VERSION ""

NS_ :

BS_:

BU_: Turbocharger OnBoardDataLogger OffBoardDiagnosticTool2 OffBoardDiagnosticTool1 FileServer ParkingBrakeController SeatControl2 FanDriveController SteeringColumnUnit CommunicationUnitRadio CommunicationUnitSatellite CommunicationUnitCellular PropulsionBatteryCharger ChassisController2 ChassisController1 EngineValveControl AuxiliaryHeater2 AuxiliaryHeater1 ClutchUnit RampControl InformationSystem1 SuspensionSystemController2 OilSensor VehicleDynamicStability ExhaustEmissionController TransmissionDisplay2 TransmissionDisplay1 ClimateControl2 WaterPumpController RearAxleSteeringController LightingOperatorControl SeatController1 IgnitionController2 IgnitionController1 TirePressureController CabController2 CabController1 PneumaticSystemController SuspensionSystemController1 HydraulicPumpController EnduranceBrakingSystem RetarderExhaustEngine2 OnBoardDiagnosticUnit HeadwayController RetarderExhaustEngine1 CabDisplay1 ManagementComputer VirtualTerminal OffVehicleGateway PowerTakeOffFront HitchControl AuxiliaryValveControl BodyController TractorTrailerBridge1 StarterSystem ElectricalSystem VehicleSecurity VehicleNavigation AerodynamicControl ElectricalChargingSystem ClimateControl1 TripRecorder InstrumentCluster SuspensionDriveAxle2 SuspensionDriveAxle1 SuspensionSteerAxle SteeringController FuelSystem CruiseControl RetarderDriveline RetarderEngine BrakesDriveAxle2 BrakesDriveAxle1 BrakesSystemController BrakesSteerAxle AxleDrive2 AxleDrive1 AxleSteering PowerTakeOff ShiftConsoleSecondary ShiftConsolePrimary Transmission2 Transmission1 Engine2 Engine1

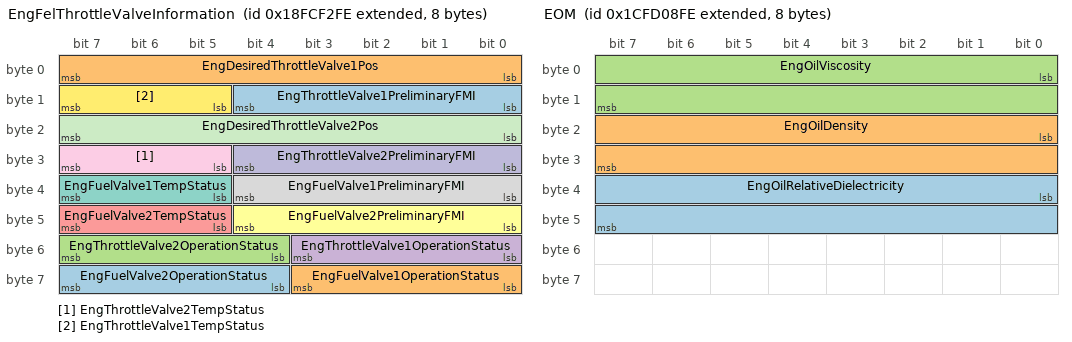
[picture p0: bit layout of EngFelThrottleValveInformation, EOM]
BO_ 2566714110 EngFelThrottleValveInformation: 8 Vector__XXX
 SG_ EngFuelValve2OperationStatus : 60|4@1+ (1,0) [0|15] "" Vector__XXX
 SG_ EngFuelValve1OperationStatus : 56|4@1+ (1,0) [0|15] "" Vector__XXX
 SG_ EngThrottleValve2OperationStatus : 52|4@1+ (1,0) [0|15] "" Vector__XXX
 SG_ EngThrottleValve1OperationStatus : 48|4@1+ (1,0) [0|15] "" Vector__XXX
 SG_ EngFuelValve2TempStatus : 45|3@1+ (1,0) [0|7] "" Vector__XXX
 SG_ EngFuelValve2PreliminaryFMI : 40|5@1+ (1,0) [0|31] "" Vector__XXX
 SG_ EngFuelValve1TempStatus : 37|3@1+ (1,0) [0|7] "" Vector__XXX
 SG_ EngFuelValve1PreliminaryFMI : 32|5@1+ (1,0) [0|31] "" Vector__XXX
 SG_ EngThrottleValve2TempStatus : 29|3@1+ (1,0) [0|7] "" Vector__XXX
 SG_ EngThrottleValve2PreliminaryFMI : 24|5@1+ (1,0) [0|31] "" Vector__XXX
 SG_ EngDesiredThrottleValve2Pos : 16|8@1+ (1,0) [0|100] "%" Vector__XXX
 SG_ EngThrottleValve1TempStatus : 13|3@1+ (1,0) [0|7] "" Vector__XXX
 SG_ EngThrottleValve1PreliminaryFMI : 8|5@1+ (1,0) [0|31] "" Vector__XXX
 SG_ EngDesiredThrottleValve1Pos : 0|8@1+ (1,0) [0|100] "%" Vector__XXX

BO_ 2566717438 ET5: 8 Vector__XXX
 SG_ EngExhstGsRcrcltn2MxerIntakeTemp : 16|16@1+ (0.03125,-273) [-273|1734.96875] "deg C" Vector__XXX
 SG_ EngExhaustGasRecirculation2Temp : 0|16@1+ (0.03125,-273) [-273|1734.96875] "deg C" Vector__XXX

BO_ 2633828606 EOM: 8 Vector__XXX
 SG_ EngOilRelativeDielectricity : 32|16@1+ (0.000122076103027,0) [0|7.844] "" Vector__XXX
 SG_ EngOilDensity : 16|16@1+ (3.051902575675E-005,0) [0|1.961] "g/cc" Vector__XXX
 SG_ EngOilViscosity : 0|16@1+ (0.015625,0) [0|1003.984375] "Cp" Vector__XXX

BO_ 2499607550 EMAP: 8 Vector__XXX
 SG_ EngExhstMnfldBnk2FlwBlncVlvActtr : 16|16@1+ (0.0025,0) [0|160.6375] "%" Vector__XXX
 SG_ EngExhstMnfldBnk1FlwBlncVlvActtr : 0|16@1+ (0.0025,0) [0|160.6375] "%" Vector__XXX

BO_ 2633825534 EMAC: 8 Vector__XXX
 SG_ EngExhstMnfldBnk2FlwBlncVlvActtr : 16|16@1+ (1,0) [0|160.6375] "%" Vector__XXX
 SG_ EngExhstMnfldBnk1FlwBlncVlvActtr : 0|16@1+ (1,0) [0|160.6375] "%" Vector__XXX

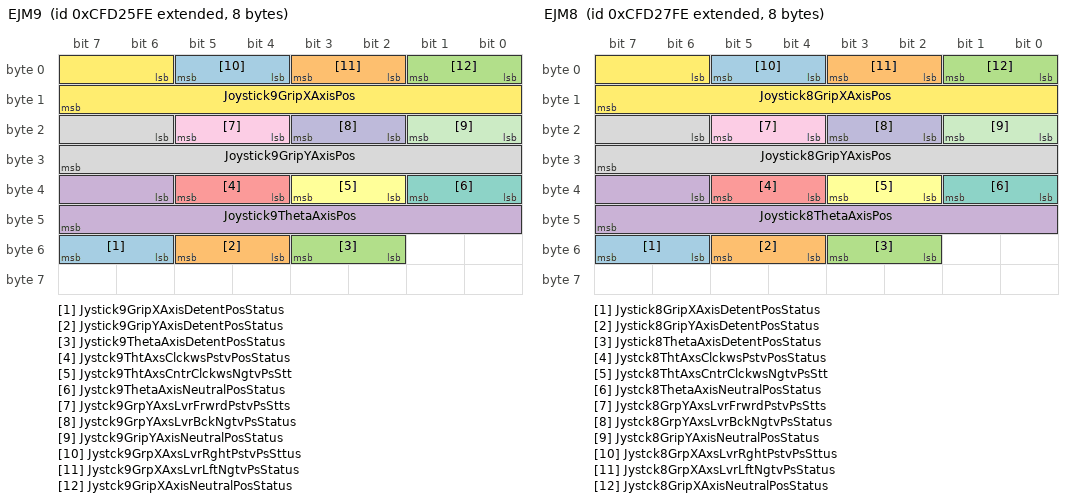
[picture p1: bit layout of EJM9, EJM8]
BO_ 2365400574 EJM9: 8 Vector__XXX
 SG_ Jystick9GripXAxisDetentPosStatus : 54|2@1+ (1,0) [0|3] "" Vector__XXX
 SG_ Jystick9GripYAxisDetentPosStatus : 52|2@1+ (1,0) [0|3] "" Vector__XXX
 SG_ Jystick9ThetaAxisDetentPosStatus : 50|2@1+ (1,0) [0|3] "" Vector__XXX
 SG_ Joystick9ThetaAxisPos : 38|10@1+ (1,0) [0|102] "%" Vector__XXX
 SG_ Jystck9ThtAxsClckwsPstvPosStatus : 36|2@1+ (1,0) [0|3] "" Vector__XXX
 SG_ Jystck9ThtAxsCntrClckwsNgtvPsStt : 34|2@1+ (1,0) [0|3] "" Vector__XXX
 SG_ Jystck9ThetaAxisNeutralPosStatus : 32|2@1+ (1,0) [0|3] "" Vector__XXX
 SG_ Joystick9GripYAxisPos : 22|10@1+ (1,0) [0|102] "%" Vector__XXX
 SG_ Jystck9GrpYAxsLvrFrwrdPstvPsStts : 20|2@1+ (1,0) [0|3] "" Vector__XXX
 SG_ Jystck9GrpYAxsLvrBckNgtvPsStatus : 18|2@1+ (1,0) [0|3] "" Vector__XXX
 SG_ Jystck9GripYAxisNeutralPosStatus : 16|2@1+ (1,0) [0|3] "" Vector__XXX
 SG_ Joystick9GripXAxisPos : 6|10@1+ (1,0) [0|102] "%" Vector__XXX
 SG_ Jystck9GrpXAxsLvrRghtPstvPsSttus : 4|2@1+ (1,0) [0|3] "" Vector__XXX
 SG_ Jystck9GrpXAxsLvrLftNgtvPsStatus : 2|2@1+ (1,0) [0|3] "" Vector__XXX
 SG_ Jystck9GripXAxisNeutralPosStatus : 0|2@1+ (1,0) [0|3] "" Vector__XXX

BO_ 2365401086 EJM8: 8 Vector__XXX
 SG_ Jystick8GripXAxisDetentPosStatus : 54|2@1+ (1,0) [0|3] "" Vector__XXX
 SG_ Jystick8GripYAxisDetentPosStatus : 52|2@1+ (1,0) [0|3] "" Vector__XXX
 SG_ Jystick8ThetaAxisDetentPosStatus : 50|2@1+ (1,0) [0|3] "" Vector__XXX
 SG_ Joystick8ThetaAxisPos : 38|10@1+ (1,0) [0|102] "%" Vector__XXX
 SG_ Jystck8ThtAxsClckwsPstvPosStatus : 36|2@1+ (1,0) [0|3] "" Vector__XXX
 SG_ Jystck8ThtAxsCntrClckwsNgtvPsStt : 34|2@1+ (1,0) [0|3] "" Vector__XXX
 SG_ Jystck8ThetaAxisNeutralPosStatus : 32|2@1+ (1,0) [0|3] "" Vector__XXX
 SG_ Joystick8GripYAxisPos : 22|10@1+ (1,0) [0|102] "%" Vector__XXX
 SG_ Jystck8GrpYAxsLvrFrwrdPstvPsStts : 20|2@1+ (1,0) [0|3] "" Vector__XXX
 SG_ Jystck8GrpYAxsLvrBckNgtvPsStatus : 18|2@1+ (1,0) [0|3] "" Vector__XXX
 SG_ Jystck8GripYAxisNeutralPosStatus : 16|2@1+ (1,0) [0|3] "" Vector__XXX
 SG_ Joystick8GripXAxisPos : 6|10@1+ (1,0) [0|102] "%" Vector__XXX
 SG_ Jystck8GrpXAxsLvrRghtPstvPsSttus : 4|2@1+ (1,0) [0|3] "" Vector__XXX
 SG_ Jystck8GrpXAxsLvrLftNgtvPsStatus : 2|2@1+ (1,0) [0|3] "" Vector__XXX
 SG_ Jystck8GripXAxisNeutralPosStatus : 0|2@1+ (1,0) [0|3] "" Vector__XXX

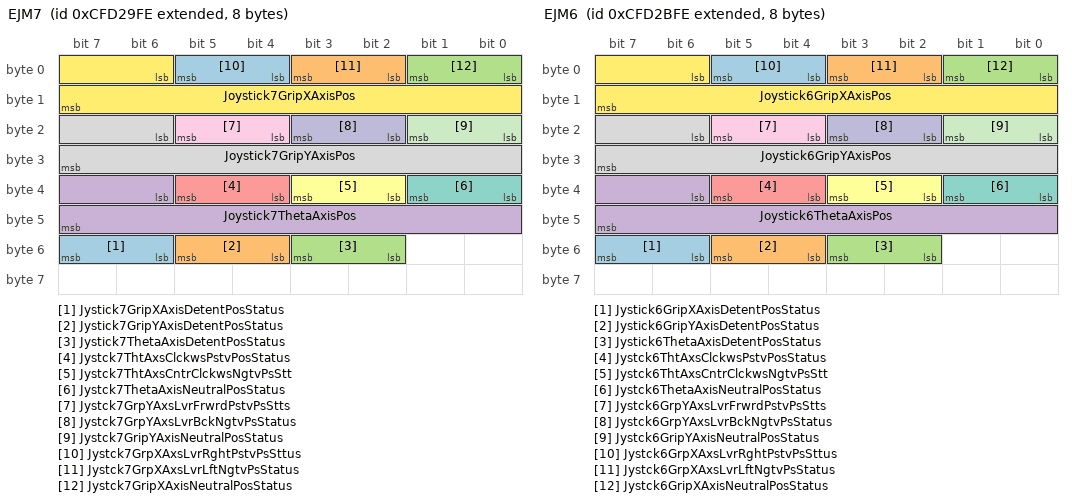
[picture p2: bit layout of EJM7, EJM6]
BO_ 2365401598 EJM7: 8 Vector__XXX
 SG_ Jystick7GripXAxisDetentPosStatus : 54|2@1+ (1,0) [0|3] "" Vector__XXX
 SG_ Jystick7GripYAxisDetentPosStatus : 52|2@1+ (1,0) [0|3] "" Vector__XXX
 SG_ Jystick7ThetaAxisDetentPosStatus : 50|2@1+ (1,0) [0|3] "" Vector__XXX
 SG_ Joystick7ThetaAxisPos : 38|10@1+ (1,0) [0|102] "%" Vector__XXX
 SG_ Jystck7ThtAxsClckwsPstvPosStatus : 36|2@1+ (1,0) [0|3] "" Vector__XXX
 SG_ Jystck7ThtAxsCntrClckwsNgtvPsStt : 34|2@1+ (1,0) [0|3] "" Vector__XXX
 SG_ Jystck7ThetaAxisNeutralPosStatus : 32|2@1+ (1,0) [0|3] "" Vector__XXX
 SG_ Joystick7GripYAxisPos : 22|10@1+ (1,0) [0|102] "%" Vector__XXX
 SG_ Jystck7GrpYAxsLvrFrwrdPstvPsStts : 20|2@1+ (1,0) [0|3] "" Vector__XXX
 SG_ Jystck7GrpYAxsLvrBckNgtvPsStatus : 18|2@1+ (1,0) [0|3] "" Vector__XXX
 SG_ Jystck7GripYAxisNeutralPosStatus : 16|2@1+ (1,0) [0|3] "" Vector__XXX
 SG_ Joystick7GripXAxisPos : 6|10@1+ (1,0) [0|102] "%" Vector__XXX
 SG_ Jystck7GrpXAxsLvrRghtPstvPsSttus : 4|2@1+ (1,0) [0|3] "" Vector__XXX
 SG_ Jystck7GrpXAxsLvrLftNgtvPsStatus : 2|2@1+ (1,0) [0|3] "" Vector__XXX
 SG_ Jystck7GripXAxisNeutralPosStatus : 0|2@1+ (1,0) [0|3] "" Vector__XXX

BO_ 2365402110 EJM6: 8 Vector__XXX
 SG_ Jystick6GripXAxisDetentPosStatus : 54|2@1+ (1,0) [0|3] "" Vector__XXX
 SG_ Jystick6GripYAxisDetentPosStatus : 52|2@1+ (1,0) [0|3] "" Vector__XXX
 SG_ Jystick6ThetaAxisDetentPosStatus : 50|2@1+ (1,0) [0|3] "" Vector__XXX
 SG_ Joystick6ThetaAxisPos : 38|10@1+ (1,0) [0|102] "%" Vector__XXX
 SG_ Jystck6ThtAxsClckwsPstvPosStatus : 36|2@1+ (1,0) [0|3] "" Vector__XXX
 SG_ Jystck6ThtAxsCntrClckwsNgtvPsStt : 34|2@1+ (1,0) [0|3] "" Vector__XXX
 SG_ Jystck6ThetaAxisNeutralPosStatus : 32|2@1+ (1,0) [0|3] "" Vector__XXX
 SG_ Joystick6GripYAxisPos : 22|10@1+ (1,0) [0|102] "%" Vector__XXX
 SG_ Jystck6GrpYAxsLvrFrwrdPstvPsStts : 20|2@1+ (1,0) [0|3] "" Vector__XXX
 SG_ Jystck6GrpYAxsLvrBckNgtvPsStatus : 18|2@1+ (1,0) [0|3] "" Vector__XXX
 SG_ Jystck6GripYAxisNeutralPosStatus : 16|2@1+ (1,0) [0|3] "" Vector__XXX
 SG_ Joystick6GripXAxisPos : 6|10@1+ (1,0) [0|102] "%" Vector__XXX
 SG_ Jystck6GrpXAxsLvrRghtPstvPsSttus : 4|2@1+ (1,0) [0|3] "" Vector__XXX
 SG_ Jystck6GrpXAxsLvrLftNgtvPsStatus : 2|2@1+ (1,0) [0|3] "" Vector__XXX
 SG_ Jystck6GripXAxisNeutralPosStatus : 0|2@1+ (1,0) [0|3] "" Vector__XXX

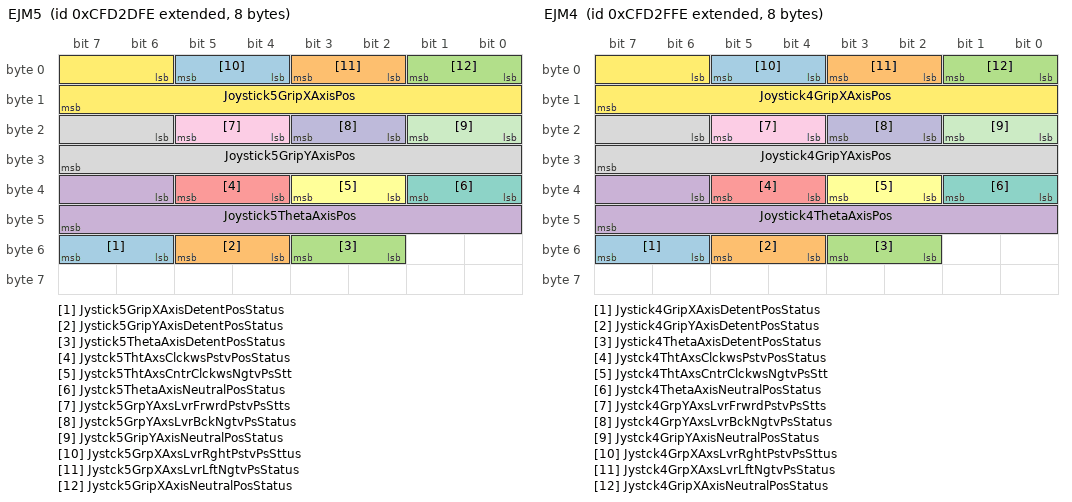
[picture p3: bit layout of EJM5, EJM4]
BO_ 2365402622 EJM5: 8 Vector__XXX
 SG_ Jystick5GripXAxisDetentPosStatus : 54|2@1+ (1,0) [0|3] "" Vector__XXX
 SG_ Jystick5GripYAxisDetentPosStatus : 52|2@1+ (1,0) [0|3] "" Vector__XXX
 SG_ Jystick5ThetaAxisDetentPosStatus : 50|2@1+ (1,0) [0|3] "" Vector__XXX
 SG_ Joystick5ThetaAxisPos : 38|10@1+ (1,0) [0|102] "%" Vector__XXX
 SG_ Jystck5ThtAxsClckwsPstvPosStatus : 36|2@1+ (1,0) [0|3] "" Vector__XXX
 SG_ Jystck5ThtAxsCntrClckwsNgtvPsStt : 34|2@1+ (1,0) [0|3] "" Vector__XXX
 SG_ Jystck5ThetaAxisNeutralPosStatus : 32|2@1+ (1,0) [0|3] "" Vector__XXX
 SG_ Joystick5GripYAxisPos : 22|10@1+ (1,0) [0|102] "%" Vector__XXX
 SG_ Jystck5GrpYAxsLvrFrwrdPstvPsStts : 20|2@1+ (1,0) [0|3] "" Vector__XXX
 SG_ Jystck5GrpYAxsLvrBckNgtvPsStatus : 18|2@1+ (1,0) [0|3] "" Vector__XXX
 SG_ Jystck5GripYAxisNeutralPosStatus : 16|2@1+ (1,0) [0|3] "" Vector__XXX
 SG_ Joystick5GripXAxisPos : 6|10@1+ (1,0) [0|102] "%" Vector__XXX
 SG_ Jystck5GrpXAxsLvrRghtPstvPsSttus : 4|2@1+ (1,0) [0|3] "" Vector__XXX
 SG_ Jystck5GrpXAxsLvrLftNgtvPsStatus : 2|2@1+ (1,0) [0|3] "" Vector__XXX
 SG_ Jystck5GripXAxisNeutralPosStatus : 0|2@1+ (1,0) [0|3] "" Vector__XXX

BO_ 2365403134 EJM4: 8 Vector__XXX
 SG_ Jystick4GripXAxisDetentPosStatus : 54|2@1+ (1,0) [0|3] "" Vector__XXX
 SG_ Jystick4GripYAxisDetentPosStatus : 52|2@1+ (1,0) [0|3] "" Vector__XXX
 SG_ Jystick4ThetaAxisDetentPosStatus : 50|2@1+ (1,0) [0|3] "" Vector__XXX
 SG_ Joystick4ThetaAxisPos : 38|10@1+ (1,0) [0|102] "%" Vector__XXX
 SG_ Jystck4ThtAxsClckwsPstvPosStatus : 36|2@1+ (1,0) [0|3] "" Vector__XXX
 SG_ Jystck4ThtAxsCntrClckwsNgtvPsStt : 34|2@1+ (1,0) [0|3] "" Vector__XXX
 SG_ Jystck4ThetaAxisNeutralPosStatus : 32|2@1+ (1,0) [0|3] "" Vector__XXX
 SG_ Joystick4GripYAxisPos : 22|10@1+ (1,0) [0|102] "%" Vector__XXX
 SG_ Jystck4GrpYAxsLvrFrwrdPstvPsStts : 20|2@1+ (1,0) [0|3] "" Vector__XXX
 SG_ Jystck4GrpYAxsLvrBckNgtvPsStatus : 18|2@1+ (1,0) [0|3] "" Vector__XXX
 SG_ Jystck4GripYAxisNeutralPosStatus : 16|2@1+ (1,0) [0|3] "" Vector__XXX
 SG_ Joystick4GripXAxisPos : 6|10@1+ (1,0) [0|102] "%" Vector__XXX
 SG_ Jystck4GrpXAxsLvrRghtPstvPsSttus : 4|2@1+ (1,0) [0|3] "" Vector__XXX
 SG_ Jystck4GrpXAxsLvrLftNgtvPsStatus : 2|2@1+ (1,0) [0|3] "" Vector__XXX
 SG_ Jystck4GripXAxisNeutralPosStatus : 0|2@1+ (1,0) [0|3] "" Vector__XXX

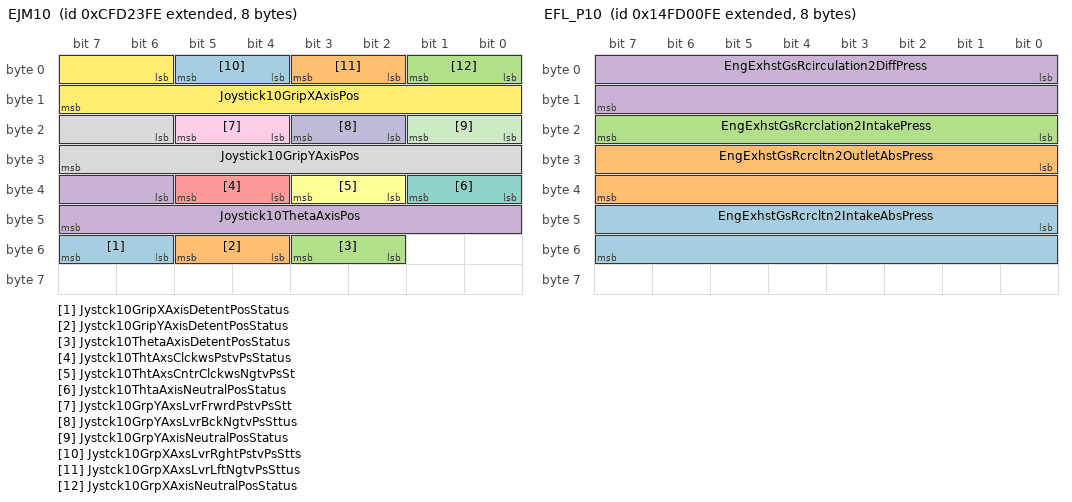
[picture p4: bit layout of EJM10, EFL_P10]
BO_ 2365400062 EJM10: 8 Vector__XXX
 SG_ Jystck10GripXAxisDetentPosStatus : 54|2@1+ (1,0) [0|3] "" Vector__XXX
 SG_ Jystck10GripYAxisDetentPosStatus : 52|2@1+ (1,0) [0|3] "" Vector__XXX
 SG_ Jystck10ThetaAxisDetentPosStatus : 50|2@1+ (1,0) [0|3] "" Vector__XXX
 SG_ Joystick10ThetaAxisPos : 38|10@1+ (1,0) [0|102] "%" Vector__XXX
 SG_ Jystck10ThtAxsClckwsPstvPsStatus : 36|2@1+ (1,0) [0|3] "" Vector__XXX
 SG_ Jystck10ThtAxsCntrClckwsNgtvPsSt : 34|2@1+ (1,0) [0|3] "" Vector__XXX
 SG_ Jystck10ThtaAxisNeutralPosStatus : 32|2@1+ (1,0) [0|3] "" Vector__XXX
 SG_ Joystick10GripYAxisPos : 22|10@1+ (1,0) [0|102] "%" Vector__XXX
 SG_ Jystck10GrpYAxsLvrFrwrdPstvPsStt : 20|2@1+ (1,0) [0|3] "" Vector__XXX
 SG_ Jystck10GrpYAxsLvrBckNgtvPsSttus : 18|2@1+ (1,0) [0|3] "" Vector__XXX
 SG_ Jystck10GrpYAxisNeutralPosStatus : 16|2@1+ (1,0) [0|3] "" Vector__XXX
 SG_ Joystick10GripXAxisPos : 6|10@1+ (1,0) [0|102] "%" Vector__XXX
 SG_ Jystck10GrpXAxsLvrRghtPstvPsStts : 4|2@1+ (1,0) [0|3] "" Vector__XXX
 SG_ Jystck10GrpXAxsLvrLftNgtvPsSttus : 2|2@1+ (1,0) [0|3] "" Vector__XXX
 SG_ Jystck10GrpXAxisNeutralPosStatus : 0|2@1+ (1,0) [0|3] "" Vector__XXX

BO_ 2566713598 EFS2: 8 Vector__XXX
 SG_ EngFuelFilterIntakeAbsPress : 0|8@1+ (2,0) [0|500] "kPa" Vector__XXX

BO_ 2499604478 EFL_P11: 8 Vector__XXX
 SG_ EngExhstGsRcrcltn1OutletAbsPress : 16|16@1+ (0.1,0) [0|6425.5] "kPa" Vector__XXX
 SG_ EngExhstGsRcrcltn1IntakeAbsPress : 0|16@1+ (0.1,0) [0|6425.5] "kPa" Vector__XXX

BO_ 2499608830 EFL_P10: 8 Vector__XXX
 SG_ EngExhstGsRcrcltn2IntakeAbsPress : 40|16@1+ (0.1,0) [0|6425.5] "kPa" Vector__XXX
 SG_ EngExhstGsRcrcltn2OutletAbsPress : 24|16@1+ (0.1,0) [0|6425.5] "kPa" Vector__XXX
 SG_ EngExhstGsRcrclation2IntakePress : 16|8@1+ (2,0) [0|500] "kPa" Vector__XXX
 SG_ EngExhstGsRcirculation2DiffPress : 0|16@1+ (0.0078124659559567,-250) [-250|251.99] "kPa" Vector__XXX

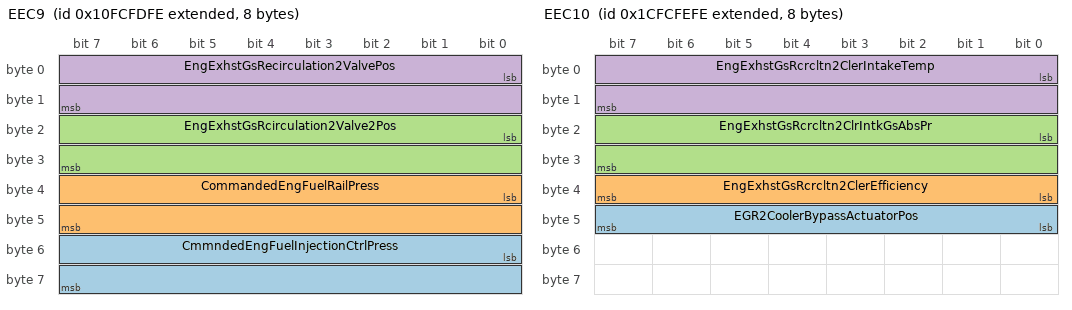
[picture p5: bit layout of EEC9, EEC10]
BO_ 2432499198 EEC9: 8 Vector__XXX
 SG_ CmmndedEngFuelInjectionCtrlPress : 48|16@1+ (0.0039063107929344,0) [0|251] "MPa" Vector__XXX
 SG_ CommandedEngFuelRailPress : 32|16@1+ (0.0039063107929344,0) [0|251] "MPa" Vector__XXX
 SG_ EngExhstGsRcirculation2Valve2Pos : 16|16@1+ (0.0025,0) [0|160.6375] "%" Vector__XXX
 SG_ EngExhstGsRecirculation2ValvePos : 0|16@1+ (0.0025,0) [0|160.6375] "%" Vector__XXX

BO_ 2633825022 EEC11: 8 Vector__XXX
 SG_ EngExhstGsRcrculation2Valve2Ctrl : 16|16@1+ (0.0025,0) [0|160.6375] "%" Vector__XXX
 SG_ EngExhstGsRcirculation2ValveCtrl : 0|16@1+ (0.0025,0) [0|160.6375] "%" Vector__XXX

BO_ 2633826046 EEC10: 8 Vector__XXX
 SG_ EGR2CoolerBypassActuatorPos : 40|8@1+ (0.4,0) [0|100] "%" Vector__XXX
 SG_ EngExhstGsRcrcltn2ClerEfficiency : 32|8@1+ (0.4,0) [0|100] "%" Vector__XXX
 SG_ EngExhstGsRcrcltn2ClrIntkGsAbsPr : 16|16@1+ (0.5,0) [0|32127.5] "kPa" Vector__XXX
 SG_ EngExhstGsRcrcltn2ClerIntakeTemp : 0|16@1+ (0.03125,-273) [-273|1734.96875] "deg C" Vector__XXX

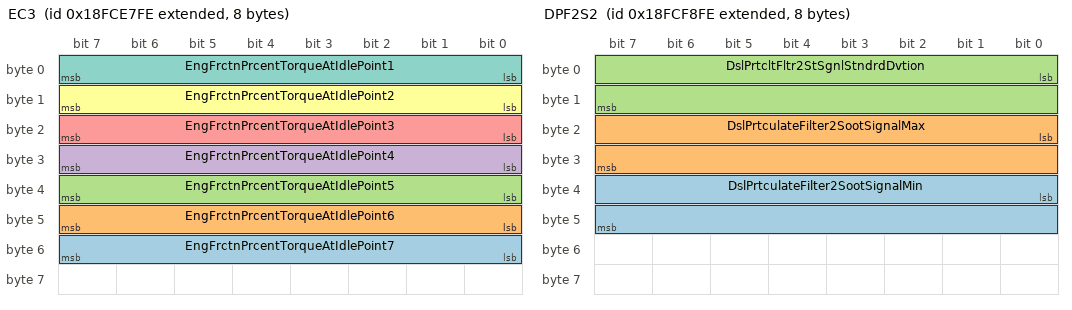
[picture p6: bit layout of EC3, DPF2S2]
BO_ 2566711294 EC3: 8 Vector__XXX
 SG_ EngFrctnPrcentTorqueAtIdlePoint7 : 48|8@1+ (1,-125) [-125|125] "%" Vector__XXX
 SG_ EngFrctnPrcentTorqueAtIdlePoint6 : 40|8@1+ (1,-125) [-125|125] "%" Vector__XXX
 SG_ EngFrctnPrcentTorqueAtIdlePoint5 : 32|8@1+ (1,-125) [-125|125] "%" Vector__XXX
 SG_ EngFrctnPrcentTorqueAtIdlePoint4 : 24|8@1+ (1,-125) [-125|125] "%" Vector__XXX
 SG_ EngFrctnPrcentTorqueAtIdlePoint3 : 16|8@1+ (1,-125) [-125|125] "%" Vector__XXX
 SG_ EngFrctnPrcentTorqueAtIdlePoint2 : 8|8@1+ (1,-125) [-125|125] "%" Vector__XXX
 SG_ EngFrctnPrcentTorqueAtIdlePoint1 : 0|8@1+ (1,-125) [-125|125] "%" Vector__XXX

BO_ 2566749438 DPFC1: 8 Vector__XXX
 SG_ DslPrtcltFltrActvRgnrtnFrcdSttus : 53|3@1+ (1,0) [0|7] "" Vector__XXX
 SG_ ExhaustSystemHighTempLampCmd : 50|3@1+ (1,0) [0|7] "" Vector__XXX
 SG_ DslPrtcltFltrAtmtcActvRgnrtnIntt : 48|2@1+ (1,0) [0|3] "" Vector__XXX
 SG_ DslPrtcltFltrActvRgnrtnInhbtdDTV : 46|2@1+ (1,0) [0|3] "" Vector__XXX
 SG_ DslPrtcltFltrActvRgnrtnInhbtdDTE : 44|2@1+ (1,0) [0|3] "" Vector__XXX
 SG_ DslPrtcltFltrActvRgnrtnInhb_0000 : 42|2@1+ (1,0) [0|3] "" Vector__XXX
 SG_ DslPrtcltFltrActvRgnrtnInhbtdDTT : 40|2@1+ (1,0) [0|3] "" Vector__XXX
 SG_ DslPrtcltFltrActvRgnrtnInhbtdDTS : 38|2@1+ (1,0) [0|3] "" Vector__XXX
 SG_ DslPrtcltFltrActvRgnrtnInhbtdDTS : 36|2@1+ (1,0) [0|3] "" Vector__XXX
 SG_ DslPrtcltFltrActvRgnrtnInhbtdDTL : 34|2@1+ (1,0) [0|3] "" Vector__XXX
 SG_ DslPrtcltFltrActvRgnrtnInhb_0001 : 32|2@1+ (1,0) [0|3] "" Vector__XXX
 SG_ DslPrtcltFltrActvRgnrtnInhb_0002 : 30|2@1+ (1,0) [0|3] "" Vector__XXX
 SG_ DslPrtcltFltrActvRgnrtnInhbtdDTO : 28|2@1+ (1,0) [0|3] "" Vector__XXX
 SG_ DslPrtcltFltrActvRgnrtnInhbtdDTA : 26|2@1+ (1,0) [0|3] "" Vector__XXX
 SG_ DslPrtcltFltrActvRgnrtnInhbtdDTP : 24|2@1+ (1,0) [0|3] "" Vector__XXX
 SG_ DslPrtcltFltrActvRgnrtnInhbtdDTS : 22|2@1+ (1,0) [0|3] "" Vector__XXX
 SG_ DslPrtcltFltrActvRgnrtnInhbtdDTC : 20|2@1+ (1,0) [0|3] "" Vector__XXX
 SG_ DslPrtcltFltrActvRgnrtnInhbtdDTI : 18|2@1+ (1,0) [0|3] "" Vector__XXX
 SG_ DslPrtcltFltrActvRgnrtnInhbtdStt : 16|2@1+ (1,0) [0|3] "" Vector__XXX
 SG_ DieselParticulateFilterStatus : 12|3@1+ (1,0) [0|7] "" Vector__XXX
 SG_ DslPrtcltFltrActvRgnrationStatus : 10|2@1+ (1,0) [0|3] "" Vector__XXX
 SG_ DslPrtcltFltrPssvRgnrationStatus : 8|2@1+ (1,0) [0|3] "" Vector__XXX
 SG_ DieselParticulateFilterLampCmd : 0|3@1+ (1,0) [0|7] "" Vector__XXX

BO_ 2566715646 DPF2S2: 8 Vector__XXX
 SG_ DslPrtculateFilter2SootSignalMin : 32|16@1+ (0.0025,0) [0|160.6375] "%" Vector__XXX
 SG_ DslPrtculateFilter2SootSignalMax : 16|16@1+ (0.0025,0) [0|160.6375] "%" Vector__XXX
 SG_ DslPrtcltFltr2StSgnlStndrdDvtion : 0|16@1+ (0.0025,0) [0|160.6375] "%" Vector__XXX

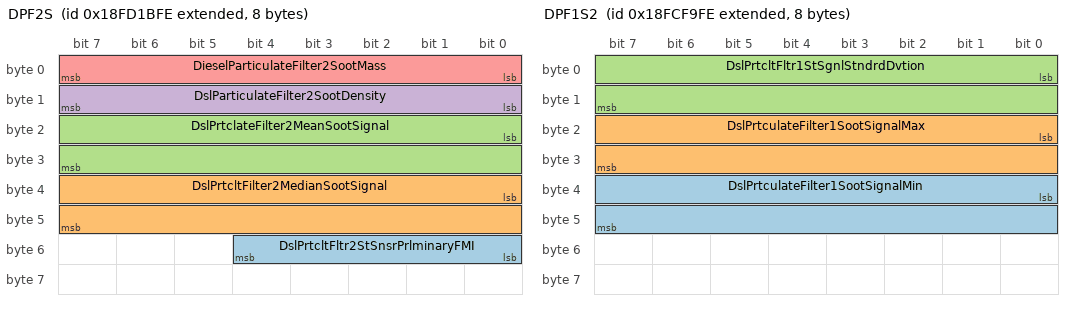
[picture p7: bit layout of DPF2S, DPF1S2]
BO_ 2566724606 DPF2S: 8 Vector__XXX
 SG_ DslPrtcltFltr2StSnsrPrlminaryFMI : 48|5@1+ (1,0) [0|31] "" Vector__XXX
 SG_ DslPrtcltFilter2MedianSootSignal : 32|16@1+ (0.0025,0) [0|160.6375] "%" Vector__XXX
 SG_ DslPrtclateFilter2MeanSootSignal : 16|16@1+ (0.0025,0) [0|160.6375] "%" Vector__XXX
 SG_ DslParticulateFilter2SootDensity : 8|8@1+ (0.08,0) [0|20] "g/L" Vector__XXX
 SG_ DieselParticulateFilter2SootMass : 0|8@1+ (4,0) [0|1000] "g" Vector__XXX

BO_ 2566715902 DPF1S2: 8 Vector__XXX
 SG_ DslPrtculateFilter1SootSignalMin : 32|16@1+ (0.0025,0) [0|160.6375] "%" Vector__XXX
 SG_ DslPrtculateFilter1SootSignalMax : 16|16@1+ (0.0025,0) [0|160.6375] "%" Vector__XXX
 SG_ DslPrtcltFltr1StSgnlStndrdDvtion : 0|16@1+ (0.0025,0) [0|160.6375] "%" Vector__XXX

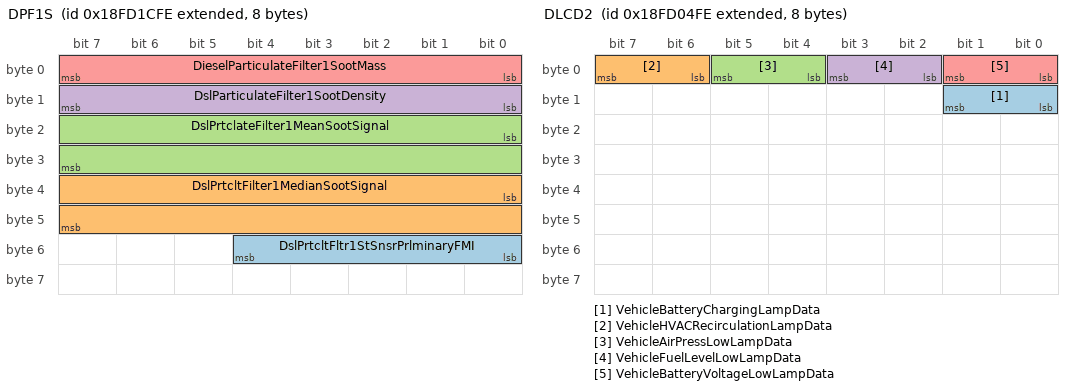
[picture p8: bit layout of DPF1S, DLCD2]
BO_ 2566724862 DPF1S: 8 Vector__XXX
 SG_ DslPrtcltFltr1StSnsrPrlminaryFMI : 48|5@1+ (1,0) [0|31] "" Vector__XXX
 SG_ DslPrtcltFilter1MedianSootSignal : 32|16@1+ (0.0025,0) [0|160.6375] "%" Vector__XXX
 SG_ DslPrtclateFilter1MeanSootSignal : 16|16@1+ (0.0025,0) [0|160.6375] "%" Vector__XXX
 SG_ DslParticulateFilter1SootDensity : 8|8@1+ (0.08,0) [0|20] "g/L" Vector__XXX
 SG_ DieselParticulateFilter1SootMass : 0|8@1+ (4,0) [0|1000] "g" Vector__XXX

BO_ 2566718718 DLCD2: 8 Vector__XXX
 SG_ VehicleBatteryChargingLampData : 8|2@1+ (1,0) [0|3] "" Vector__XXX
 SG_ VehicleHVACRecirculationLampData : 6|2@1+ (1,0) [0|3] "" Vector__XXX
 SG_ VehicleAirPressLowLampData : 4|2@1+ (1,0) [0|3] "" Vector__XXX
 SG_ VehicleFuelLevelLowLampData : 2|2@1+ (1,0) [0|3] "" Vector__XXX
 SG_ VehicleBatteryVoltageLowLampData : 0|2@1+ (1,0) [0|3] "" Vector__XXX

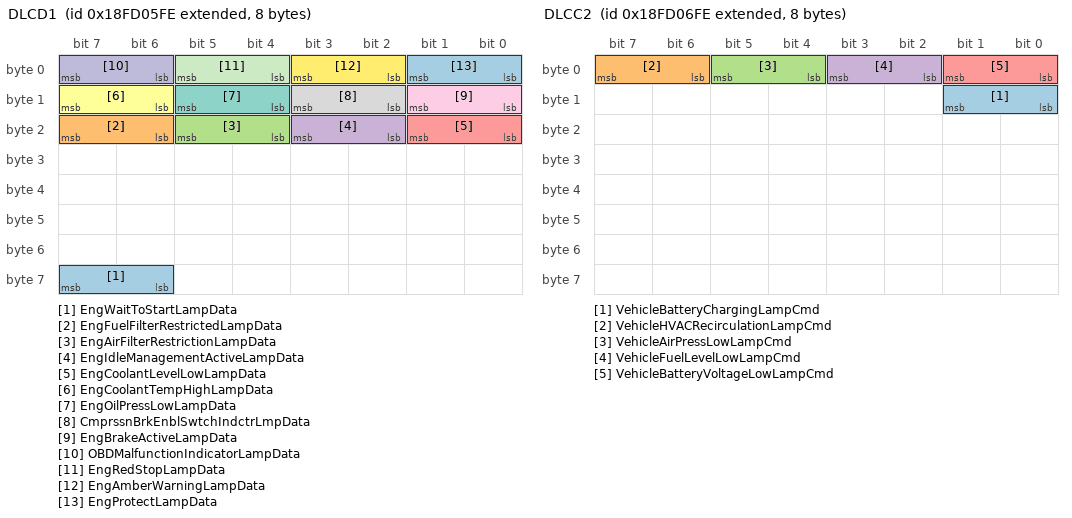
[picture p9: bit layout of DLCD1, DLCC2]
BO_ 2566718974 DLCD1: 8 Vector__XXX
 SG_ EngWaitToStartLampData : 62|2@1+ (1,0) [0|3] "" Vector__XXX
 SG_ EngFuelFilterRestrictedLampData : 22|2@1+ (1,0) [0|3] "" Vector__XXX
 SG_ EngAirFilterRestrictionLampData : 20|2@1+ (1,0) [0|3] "" Vector__XXX
 SG_ EngIdleManagementActiveLampData : 18|2@1+ (1,0) [0|3] "" Vector__XXX
 SG_ EngCoolantLevelLowLampData : 16|2@1+ (1,0) [0|3] "" Vector__XXX
 SG_ EngCoolantTempHighLampData : 14|2@1+ (1,0) [0|3] "" Vector__XXX
 SG_ EngOilPressLowLampData : 12|2@1+ (1,0) [0|3] "" Vector__XXX
 SG_ CmprssnBrkEnblSwtchIndctrLmpData : 10|2@1+ (1,0) [0|3] "" Vector__XXX
 SG_ EngBrakeActiveLampData : 8|2@1+ (1,0) [0|3] "" Vector__XXX
 SG_ OBDMalfunctionIndicatorLampData : 6|2@1+ (1,0) [0|3] "" Vector__XXX
 SG_ EngRedStopLampData : 4|2@1+ (1,0) [0|3] "" Vector__XXX
 SG_ EngAmberWarningLampData : 2|2@1+ (1,0) [0|3] "" Vector__XXX
 SG_ EngProtectLampData : 0|2@1+ (1,0) [0|3] "" Vector__XXX

BO_ 2566719230 DLCC2: 8 Vector__XXX
 SG_ VehicleBatteryChargingLampCmd : 8|2@1+ (1,0) [0|3] "" Vector__XXX
 SG_ VehicleHVACRecirculationLampCmd : 6|2@1+ (1,0) [0|3] "" Vector__XXX
 SG_ VehicleAirPressLowLampCmd : 4|2@1+ (1,0) [0|3] "" Vector__XXX
 SG_ VehicleFuelLevelLowLampCmd : 2|2@1+ (1,0) [0|3] "" Vector__XXX
 SG_ VehicleBatteryVoltageLowLampCmd : 0|2@1+ (1,0) [0|3] "" Vector__XXX

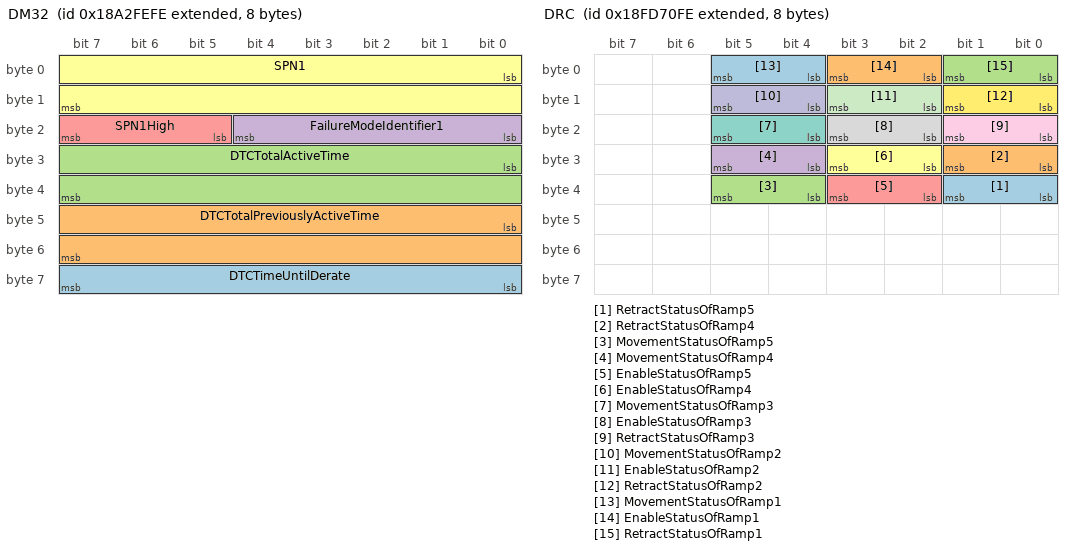
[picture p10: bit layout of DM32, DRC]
BO_ 2560818942 DM32: 8 Vector__XXX
 SG_ DTCTimeUntilDerate : 56|8@1+ (0.25,0) [0|62.5] "hr" Vector__XXX
 SG_ DTCTotalPreviouslyActiveTime : 40|16@1+ (0.2,0) [0|12851] "hr" Vector__XXX
 SG_ DTCTotalActiveTime : 24|16@1+ (0.2,0) [0|12851] "hr" Vector__XXX
 SG_ FailureModeIdentifier1 : 16|5@1+ (1,0) [0|0] "" Vector__XXX
 SG_ SPN1High : 21|3@1+ (1,0) [0|7] "" Vector__XXX
 SG_ SPN1 : 0|16@1+ (1,0) [0|65536] "" Vector__XXX

BO_ 2561212158 DISP1: 8 Vector__XXX
 SG_ TextDisplayIndex : 16|8@1+ (1,0) [0|250] "" Vector__XXX
 SG_ TextDisplayInstructions : 0|4@1+ (1,0) [0|15] "" Vector__XXX

BO_ 2566746366 DRC: 8 Vector__XXX
 SG_ RetractStatusOfRamp5 : 32|2@1+ (1,0) [0|3] "" Vector__XXX
 SG_ RetractStatusOfRamp4 : 24|2@1+ (1,0) [0|3] "" Vector__XXX
 SG_ MovementStatusOfRamp5 : 36|2@1+ (1,0) [0|3] "" Vector__XXX
 SG_ MovementStatusOfRamp4 : 28|2@1+ (1,0) [0|3] "" Vector__XXX
 SG_ EnableStatusOfRamp5 : 34|2@1+ (1,0) [0|3] "" Vector__XXX
 SG_ EnableStatusOfRamp4 : 26|2@1+ (1,0) [0|3] "" Vector__XXX
 SG_ MovementStatusOfRamp3 : 20|2@1+ (1,0) [0|3] "" Vector__XXX
 SG_ EnableStatusOfRamp3 : 18|2@1+ (1,0) [0|3] "" Vector__XXX
 SG_ RetractStatusOfRamp3 : 16|2@1+ (1,0) [0|3] "" Vector__XXX
 SG_ MovementStatusOfRamp2 : 12|2@1+ (1,0) [0|3] "" Vector__XXX
 SG_ EnableStatusOfRamp2 : 10|2@1+ (1,0) [0|3] "" Vector__XXX
 SG_ RetractStatusOfRamp2 : 8|2@1+ (1,0) [0|3] "" Vector__XXX
 SG_ MovementStatusOfRamp1 : 4|2@1+ (1,0) [0|3] "" Vector__XXX
 SG_ EnableStatusOfRamp1 : 2|2@1+ (1,0) [0|3] "" Vector__XXX
 SG_ RetractStatusOfRamp1 : 0|2@1+ (1,0) [0|3] "" Vector__XXX

BO_ 2566750206 EC2: 8 Vector__XXX
 SG_ MaxCrankAttemptsPerStartAttempt : 0|8@1+ (1,0) [0|250] "" Vector__XXX

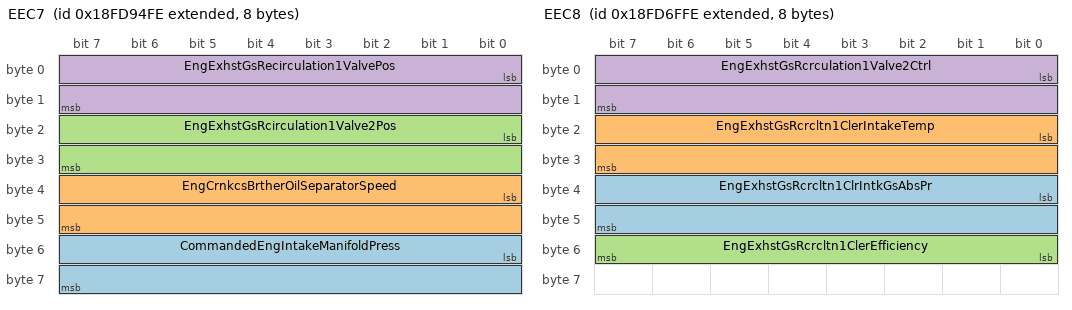
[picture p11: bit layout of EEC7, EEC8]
BO_ 2566755582 EEC7: 8 Vector__XXX
 SG_ CommandedEngIntakeManifoldPress : 48|16@1+ (0.125,0) [0|8031.875] "kPa" Vector__XXX
 SG_ EngCrnkcsBrtherOilSeparatorSpeed : 32|16@1+ (1,0) [0|64255] "rpm" Vector__XXX
 SG_ EngExhstGsRcirculation1Valve2Pos : 16|16@1+ (0.0025,0) [0|160.6375] "%" Vector__XXX
 SG_ EngExhstGsRecirculation1ValvePos : 0|16@1+ (0.0025,0) [0|160.6375] "%" Vector__XXX

BO_ 2566746110 EEC8: 8 Vector__XXX
 SG_ EngExhstGsRcrcltn1ClrIntkGsAbsPr : 32|16@1+ (0.5,0) [0|32127.5] "kPa" Vector__XXX
 SG_ EngExhstGsRcrcltn1ClerIntakeTemp : 16|16@1+ (0.03125,-273) [-273|1734.96875] "deg C" Vector__XXX
 SG_ EngExhstGsRcrcltn1ClerEfficiency : 48|8@1+ (1,0) [0|100] "%" Vector__XXX
 SG_ EngExhstGsRcrculation1Valve2Ctrl : 0|16@1+ (1,0) [0|160.6375] "%" Vector__XXX

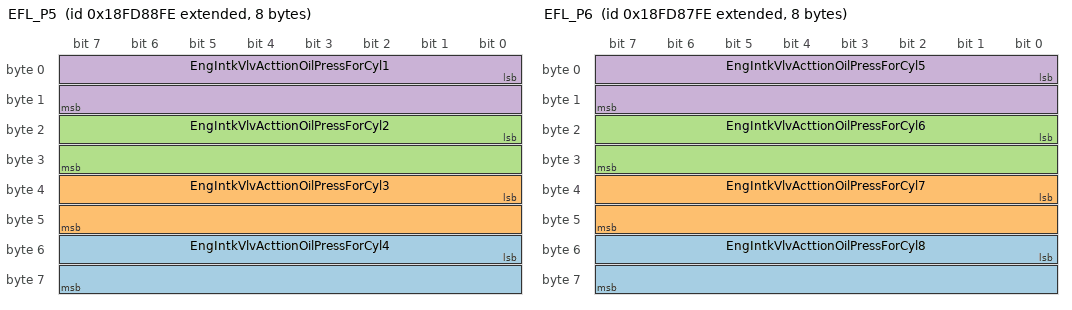
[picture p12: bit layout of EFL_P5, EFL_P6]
BO_ 2566752510 EFL_P5: 8 Vector__XXX
 SG_ EngIntkVlvActtionOilPressForCyl4 : 48|16@1+ (0.1,0) [0|6425.5] "kPa" Vector__XXX
 SG_ EngIntkVlvActtionOilPressForCyl3 : 32|16@1+ (0.1,0) [0|6425.5] "kPa" Vector__XXX
 SG_ EngIntkVlvActtionOilPressForCyl2 : 16|16@1+ (0.1,0) [0|6425.5] "kPa" Vector__XXX
 SG_ EngIntkVlvActtionOilPressForCyl1 : 0|16@1+ (0.1,0) [0|6425.5] "kPa" Vector__XXX

BO_ 2566752254 EFL_P6: 8 Vector__XXX
 SG_ EngIntkVlvActtionOilPressForCyl8 : 48|16@1+ (0.1,0) [0|6425.5] "kPa" Vector__XXX
 SG_ EngIntkVlvActtionOilPressForCyl7 : 32|16@1+ (0.1,0) [0|6425.5] "kPa" Vector__XXX
 SG_ EngIntkVlvActtionOilPressForCyl6 : 16|16@1+ (0.1,0) [0|6425.5] "kPa" Vector__XXX
 SG_ EngIntkVlvActtionOilPressForCyl5 : 0|16@1+ (0.1,0) [0|6425.5] "kPa" Vector__XXX

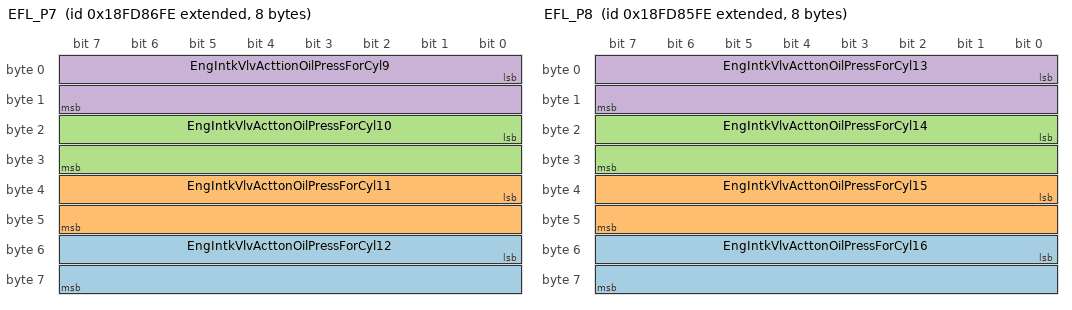
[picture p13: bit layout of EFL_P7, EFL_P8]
BO_ 2566751998 EFL_P7: 8 Vector__XXX
 SG_ EngIntkVlvActtonOilPressForCyl12 : 48|16@1+ (0.1,0) [0|6425.5] "kPa" Vector__XXX
 SG_ EngIntkVlvActtonOilPressForCyl11 : 32|16@1+ (0.1,0) [0|6425.5] "kPa" Vector__XXX
 SG_ EngIntkVlvActtonOilPressForCyl10 : 16|16@1+ (0.1,0) [0|6425.5] "kPa" Vector__XXX
 SG_ EngIntkVlvActtionOilPressForCyl9 : 0|16@1+ (0.1,0) [0|6425.5] "kPa" Vector__XXX

BO_ 2566751742 EFL_P8: 8 Vector__XXX
 SG_ EngIntkVlvActtonOilPressForCyl16 : 48|16@1+ (0.1,0) [0|6425.5] "kPa" Vector__XXX
 SG_ EngIntkVlvActtonOilPressForCyl15 : 32|16@1+ (0.1,0) [0|6425.5] "kPa" Vector__XXX
 SG_ EngIntkVlvActtonOilPressForCyl14 : 16|16@1+ (0.1,0) [0|6425.5] "kPa" Vector__XXX
 SG_ EngIntkVlvActtonOilPressForCyl13 : 0|16@1+ (0.1,0) [0|6425.5] "kPa" Vector__XXX

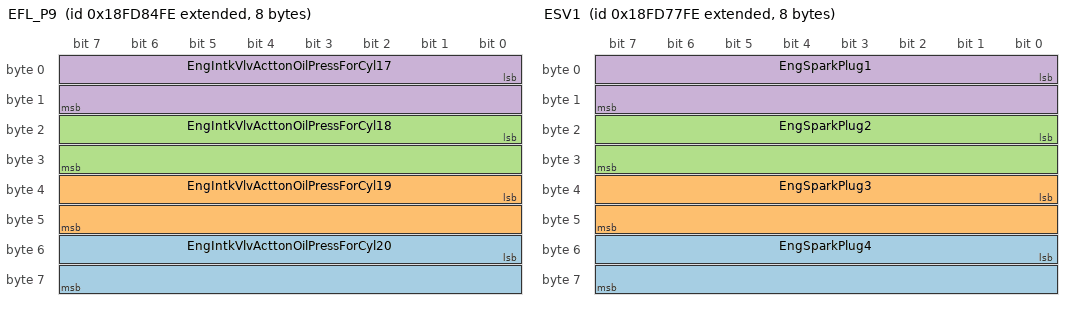
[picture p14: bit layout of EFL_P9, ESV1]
BO_ 2566751486 EFL_P9: 8 Vector__XXX
 SG_ EngIntkVlvActtonOilPressForCyl20 : 48|16@1+ (0.1,0) [0|6425.5] "kPa" Vector__XXX
 SG_ EngIntkVlvActtonOilPressForCyl19 : 32|16@1+ (0.1,0) [0|6425.5] "kPa" Vector__XXX
 SG_ EngIntkVlvActtonOilPressForCyl18 : 16|16@1+ (0.1,0) [0|6425.5] "kPa" Vector__XXX
 SG_ EngIntkVlvActtonOilPressForCyl17 : 0|16@1+ (0.1,0) [0|6425.5] "kPa" Vector__XXX

BO_ 2499641854 EGRBV: 8 Vector__XXX
 SG_ EGR1CoolerBypassActuatorPostion : 0|8@1+ (0.4,0) [0|100] "%" Vector__XXX

BO_ 2566748158 ESV1: 8 Vector__XXX
 SG_ EngSparkPlug4 : 48|16@1+ (1,0) [0|64255] "Volts" Vector__XXX
 SG_ EngSparkPlug3 : 32|16@1+ (1,0) [0|64255] "Volts" Vector__XXX
 SG_ EngSparkPlug2 : 16|16@1+ (1,0) [0|64255] "Volts" Vector__XXX
 SG_ EngSparkPlug1 : 0|16@1+ (1,0) [0|64255] "Volts" Vector__XXX

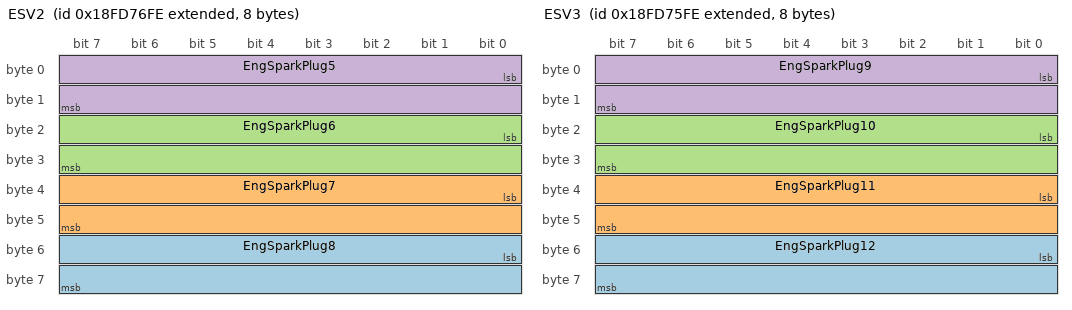
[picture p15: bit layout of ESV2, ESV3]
BO_ 2566747902 ESV2: 8 Vector__XXX
 SG_ EngSparkPlug8 : 48|16@1+ (1,0) [0|64255] "Volts" Vector__XXX
 SG_ EngSparkPlug7 : 32|16@1+ (1,0) [0|64255] "Volts" Vector__XXX
 SG_ EngSparkPlug6 : 16|16@1+ (1,0) [0|64255] "Volts" Vector__XXX
 SG_ EngSparkPlug5 : 0|16@1+ (1,0) [0|64255] "Volts" Vector__XXX

BO_ 2566747646 ESV3: 8 Vector__XXX
 SG_ EngSparkPlug12 : 48|16@1+ (1,0) [0|64255] "Volts" Vector__XXX
 SG_ EngSparkPlug11 : 32|16@1+ (1,0) [0|64255] "Volts" Vector__XXX
 SG_ EngSparkPlug10 : 16|16@1+ (1,0) [0|64255] "Volts" Vector__XXX
 SG_ EngSparkPlug9 : 0|16@1+ (1,0) [0|64255] "Volts" Vector__XXX

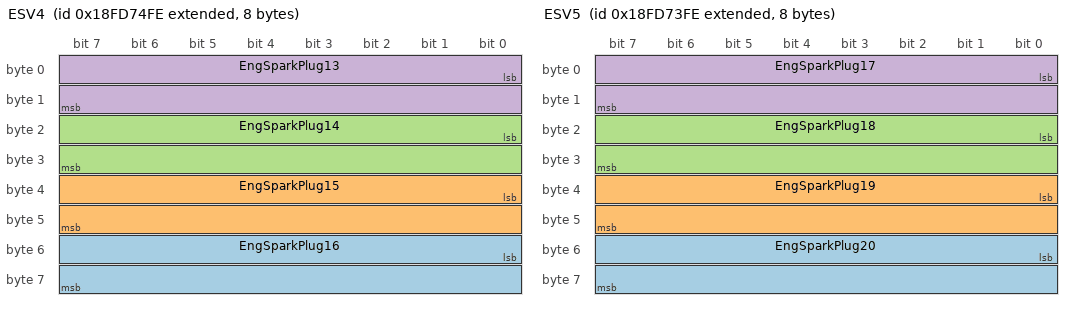
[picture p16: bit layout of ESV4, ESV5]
BO_ 2566747390 ESV4: 8 Vector__XXX
 SG_ EngSparkPlug16 : 48|16@1+ (1,0) [0|64255] "Volts" Vector__XXX
 SG_ EngSparkPlug15 : 32|16@1+ (1,0) [0|64255] "Volts" Vector__XXX
 SG_ EngSparkPlug14 : 16|16@1+ (1,0) [0|64255] "Volts" Vector__XXX
 SG_ EngSparkPlug13 : 0|16@1+ (1,0) [0|64255] "Volts" Vector__XXX

BO_ 2566747134 ESV5: 8 Vector__XXX
 SG_ EngSparkPlug20 : 48|16@1+ (1,0) [0|64255] "Volts" Vector__XXX
 SG_ EngSparkPlug19 : 32|16@1+ (1,0) [0|64255] "Volts" Vector__XXX
 SG_ EngSparkPlug18 : 16|16@1+ (1,0) [0|64255] "Volts" Vector__XXX
 SG_ EngSparkPlug17 : 0|16@1+ (1,0) [0|64255] "Volts" Vector__XXX

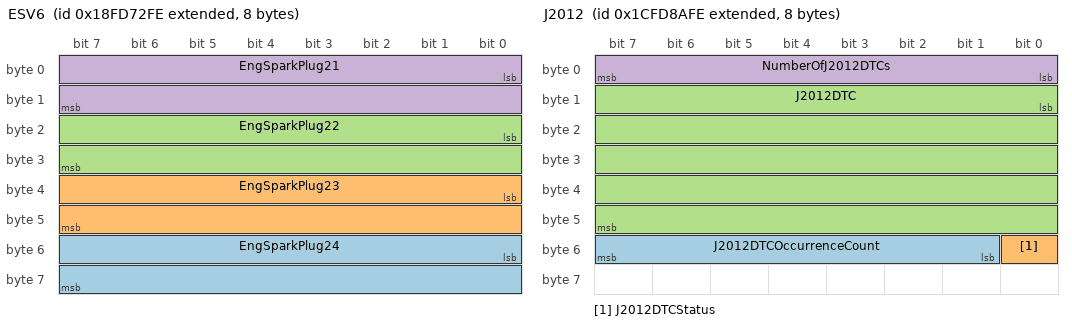
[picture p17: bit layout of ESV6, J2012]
BO_ 2566746878 ESV6: 8 Vector__XXX
 SG_ EngSparkPlug24 : 48|16@1+ (1,0) [0|64255] "Volts" Vector__XXX
 SG_ EngSparkPlug23 : 32|16@1+ (1,0) [0|64255] "Volts" Vector__XXX
 SG_ EngSparkPlug22 : 16|16@1+ (1,0) [0|64255] "Volts" Vector__XXX
 SG_ EngSparkPlug21 : 0|16@1+ (1,0) [0|64255] "Volts" Vector__XXX

BO_ 2561277694 FLIC: 8 Vector__XXX
 SG_ LaneDepartureWarningEnableCmd : 0|2@1+ (1,0) [0|3] "" Vector__XXX

BO_ 2633861886 J2012: 8 Vector__XXX
 SG_ J2012DTCOccurrenceCount : 49|7@1+ (1,0) [0|127] "" Vector__XXX
 SG_ J2012DTCStatus : 48|1@1+ (1,0) [0|1] "" Vector__XXX
 SG_ J2012DTC : 8|40@1+ (1,0) [0|255] "per byte" Vector__XXX
 SG_ NumberOfJ2012DTCs : 0|8@1+ (1,0) [0|250] "" Vector__XXX

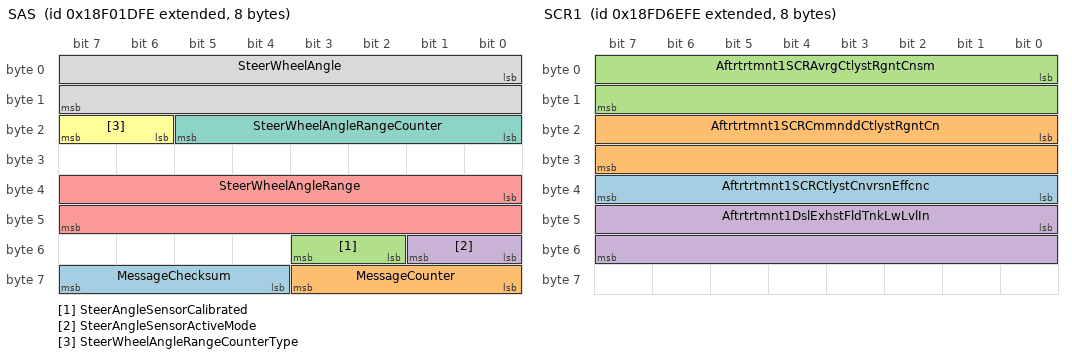
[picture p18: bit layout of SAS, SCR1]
BO_ 2565873150 SAS: 8 Vector__XXX
 SG_ MessageChecksum : 60|4@1+ (1,0) [0|15] "" Vector__XXX
 SG_ MessageCounter : 56|4@1+ (1,0) [0|15] "" Vector__XXX
 SG_ SteerAngleSensorCalibrated : 50|2@1+ (1,0) [0|3] "" Vector__XXX
 SG_ SteerAngleSensorActiveMode : 48|2@1+ (1,0) [0|3] "" Vector__XXX
 SG_ SteerWheelAngleRange : 32|16@1+ (0.00097654657225119,-31.374) [-31.374|31.374] "rad" Vector__XXX
 SG_ SteerWheelAngleRangeCounterType : 22|2@1+ (1,0) [0|3] "" Vector__XXX
 SG_ SteerWheelAngleRangeCounter : 16|6@1+ (1,-32) [-32|29] "ranges" Vector__XXX
 SG_ SteerWheelAngle : 0|16@1+ (0.00097654657225119,-31.374) [-31.374|31.374] "rad" Vector__XXX

BO_ 2566745854 SCR1: 8 Vector__XXX
 SG_ Aftrtrtmnt1SCRCtlystCnvrsnEffcnc : 32|8@1+ (0.4,0) [0|100] "%" Vector__XXX
 SG_ Aftrtrtmnt1SCRCmmnddCtlystRgntCn : 16|16@1+ (1,0) [0|3212.75] "L/h" Vector__XXX
 SG_ Aftrtrtmnt1SCRAvrgCtlystRgntCnsm : 0|16@1+ (0.05,0) [0|3212.75] "L/h" Vector__XXX
 SG_ Aftrtrtmnt1DslExhstFldTnkLwLvlIn : 40|16@1+ (1,0) [0|64255] "km" Vector__XXX

BO_ 2566751230 TCI: 8 Vector__XXX
 SG_ TransferCaseStatus : 0|3@1+ (1,0) [0|7] "" Vector__XXX

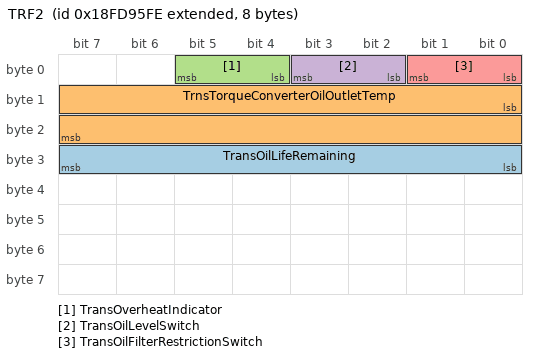
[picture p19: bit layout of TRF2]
BO_ 2566755838 TRF2: 8 Vector__XXX
 SG_ TransOilLifeRemaining : 24|8@1+ (0.4,0) [0|100] "%" Vector__XXX
 SG_ TrnsTorqueConverterOilOutletTemp : 8|16@1+ (0.03125,-273) [-273|1734.96875] "deg C" Vector__XXX
 SG_ TransOverheatIndicator : 4|2@1+ (1,0) [0|3] "" Vector__XXX
 SG_ TransOilLevelSwitch : 2|2@1+ (1,0) [0|3] "" Vector__XXX
 SG_ TransOilFilterRestrictionSwitch : 0|2@1+ (1,0) [0|3] "" Vector__XXX

BO_ 2566752766 VDS2: 8 Vector__XXX
 SG_ VehicleRoll : 0|16@1+ (0.0078124659559567,-200) [-200|301.99] "deg" Vector__XXX

BO_ 2633938942 LF: 10 Vector__XXX
 SG_ TotalEngCruiseTime : 48|32@1+ (0.05,0) [0|210554060.75] "hr" Vector__XXX
 SG_ TotalDriveAverageLoadFactor : 40|8@1+ (0.4,0) [0|100] "%" Vector__XXX
 SG_ TripDriveAverageLoadFactor : 32|8@1+ (0.4,0) [0|100] "%" Vector__XXX
 SG_ TripAverageEngSpeed : 16|16@1+ (0.125,0) [0|8031.875] "rpm" Vector__XXX
 SG_ TripMaxEngSpeed : 0|16@1+ (0.125,0) [0|8031.875] "rpm" Vector__XXX

BO_ 2566799614 LD: 8 Vector__XXX
 SG_ ImplementRearWorkLight : 62|2@1+ (1,0) [0|3] "" Vector__XXX
 SG_ ImplementLeftForwardWorkLight : 60|2@1+ (1,0) [0|3] "" Vector__XXX
 SG_ ImplementRightForwardWorkLight : 58|2@1+ (1,0) [0|3] "" Vector__XXX
 SG_ ImplementLeftFacingWorkLight : 54|2@1+ (1,0) [0|3] "" Vector__XXX
 SG_ ImplementRightFacingWorkLight : 52|2@1+ (1,0) [0|3] "" Vector__XXX
 SG_ ImplementOEMOption1Light : 50|2@1+ (1,0) [0|3] "" Vector__XXX
 SG_ ImplementOEMOption2Light : 48|2@1+ (1,0) [0|3] "" Vector__XXX
 SG_ TrctorFrontHighMountedWorkLights : 46|2@1+ (1,0) [0|3] "" Vector__XXX
 SG_ TractorFrontLowMountedWorkLights : 44|2@1+ (1,0) [0|3] "" Vector__XXX
 SG_ TractorSideHighMountedWorkLights : 42|2@1+ (1,0) [0|3] "" Vector__XXX
 SG_ TractorSideLowMountedWorkLights : 40|2@1+ (1,0) [0|3] "" Vector__XXX
 SG_ TractorRearHighMountedWorkLights : 38|2@1+ (1,0) [0|3] "" Vector__XXX
 SG_ TractorRearLowMountedWorkLights : 36|2@1+ (1,0) [0|3] "" Vector__XXX
 SG_ TrctorUndersideMountedWorkLights : 34|2@1+ (1,0) [0|3] "" Vector__XXX
 SG_ RearFogLights : 32|2@1+ (1,0) [0|3] "" Vector__XXX
 SG_ TractorMarkerLight : 30|2@1+ (1,0) [0|3] "" Vector__XXX
 SG_ ImplementMarkerLight : 28|2@1+ (1,0) [0|3] "" Vector__XXX
 SG_ TractorClearanceLight : 26|2@1+ (1,0) [0|3] "" Vector__XXX
 SG_ ImplementClearanceLight : 24|2@1+ (1,0) [0|3] "" Vector__XXX
 SG_ LeftStopLight : 22|2@1+ (1,0) [0|3] "" Vector__XXX
 SG_ RightStopLight : 20|2@1+ (1,0) [0|3] "" Vector__XXX
 SG_ CenterStopLight : 18|2@1+ (1,0) [0|3] "" Vector__XXX
 SG_ BackUpLightAndAlarmHorn : 16|2@1+ (1,0) [0|3] "" Vector__XXX
 SG_ LeftTurnSignalLights : 14|2@1+ (1,0) [0|3] "" Vector__XXX
 SG_ RightTurnSignalLights : 12|2@1+ (1,0) [0|3] "" Vector__XXX
 SG_ RotatingBeaconLight : 10|2@1+ (1,0) [0|3] "" Vector__XXX
 SG_ TractorFrontFogLights : 8|2@1+ (1,0) [0|3] "" Vector__XXX
 SG_ HighBeamHeadLightData : 6|2@1+ (1,0) [0|3] "" Vector__XXX
 SG_ LowBeamHeadLightData : 4|2@1+ (1,0) [0|3] "" Vector__XXX
 SG_ AltBeamHeadLightData : 2|2@1+ (1,0) [0|3] "" Vector__XXX
 SG_ RunningLight : 0|2@1+ (1,0) [0|3] "" Vector__XXX

CM_ BO_ 2566714110 "Engine Fuel/Throttle Valve Information";
CM_ SG_ 2566714110 EngFuelValve2OperationStatus "Used to identify the status of Engine Fuel Valve 2";
CM_ SG_ 2566714110 EngFuelValve1OperationStatus "Used to identify the status of Engine Fuel Valve 1";
CM_ SG_ 2566714110 EngThrottleValve2OperationStatus "Used to identify the status of Engine Throttle Valve 2";
CM_ SG_ 2566714110 EngThrottleValve1OperationStatus "Used to identify the status of Engine Throttle Valve 1";
CM_ SG_ 2566714110 EngFuelValve2TempStatus "Used to identify the status of the Engine Fuel valve 2 drive circuitry temperature. Temperature excursions may affect the";
CM_ SG_ 2566714110 EngFuelValve2PreliminaryFMI "Used to identify the applicable J1939-73 FMI detected in the Engine Fuel Valve 2 by the manufacturers software. When";
CM_ SG_ 2566714110 EngFuelValve1TempStatus "Used to identify the status of the Engine Fuel valve 1 drive circuitry temperature. Temperature excursions may affect the";
CM_ SG_ 2566714110 EngFuelValve1PreliminaryFMI "Used to identify the applicable J1939-73 FMI detected in the Engine Fuel Valve 1 by the manufacturers software. When";
CM_ SG_ 2566714110 EngThrottleValve2TempStatus "Used to identify the status of the Engine Throttle Valve 2 drive circuitry temperature. Temperature excursions may affect";
CM_ SG_ 2566714110 EngThrottleValve2PreliminaryFMI "Used to identify the applicable J1939-73 FMI detected in the Engine Throttle Valve 2 by the manufacturers software.";
CM_ SG_ 2566714110 EngDesiredThrottleValve2Pos "The desired position of the Throttle valve 2 that is regulating the fluid, usually air/fuel mixture to the engine as";
CM_ SG_ 2566714110 EngThrottleValve1TempStatus "Used to identify the status of the Engine Throttle Valve 1 drive circuitry temperature. Temperature excursions may affect";
CM_ SG_ 2566714110 EngThrottleValve1PreliminaryFMI "Used to identify the appplicable J1939-73 FMI detected in the Engine Throttle Valve 1 by the manufacturers software.";
CM_ SG_ 2566714110 EngDesiredThrottleValve1Pos "The desired position of the Throttle valve 1 that is regulating the fluid, usually air/fuel mixture to the engine as";
CM_ BO_ 2566717438 "Engine Temperature 5";
CM_ SG_ 2566717438 EngExhstGsRcrcltn2MxerIntakeTemp "The temperature of the EGR gas entering the intake of EGR2 system mixer.";
CM_ SG_ 2566717438 EngExhaustGasRecirculation2Temp "Temperature of Recirculated Exhaust Gas of EGR2";
CM_ BO_ 2633828606 "Engine oil related parameters";
CM_ SG_ 2633828606 EngOilRelativeDielectricity "Engine oil relative dielectricity used to describe the engine oil quality.";
CM_ SG_ 2633828606 EngOilDensity "Density of the engine oil";
CM_ SG_ 2633828606 EngOilViscosity "Dynamic viscosity of the engine oil";
CM_ BO_ 2499607550 "Engine manifold actuator position parameters";
CM_ SG_ 2499607550 EngExhstMnfldBnk2FlwBlncVlvActtr "Actual percentage of maximum Engine Manifold Bank 2 Balance valve opening. 0% means valve is closed. 100% means";
CM_ SG_ 2499607550 EngExhstMnfldBnk1FlwBlncVlvActtr "Actual percentage of maximum Engine Exhaust Manifold Bank 1 Balance valve opening. 0% means valve is closed.";
CM_ BO_ 2633825534 "Engine manifold actuator control parameters.";
CM_ SG_ 2633825534 EngExhstMnfldBnk2FlwBlncVlvActtr "Commanded percentage of maximum Engine Ehaust Manifold Bank 2 Balance valve opening. 0% means valve is closed.";
CM_ SG_ 2633825534 EngExhstMnfldBnk1FlwBlncVlvActtr "Commanded percentage of maximum Engine Exhaust Manifold Bank 1 Balance valve opening. 0% means valve is";
CM_ BO_ 2365400574 "Extended Joystick Message 9";
CM_ SG_ 2365400574 Jystick9GripXAxisDetentPosStatus "Reports when the current joystick grip position is in the detent position for that axis of travel.";
CM_ SG_ 2365400574 Jystick9GripYAxisDetentPosStatus "Reports when the current joystick grip position is in the detent position for that axis of travel.";
CM_ SG_ 2365400574 Jystick9ThetaAxisDetentPosStatus "Reports when the current joystick position is in the detent position for that axis of travel.";
CM_ SG_ 2365400574 Joystick9ThetaAxisPos "The position of the joystick in the relative motion of travel from the neutral position. Position value of 0 is Neutral and";
CM_ SG_ 2365400574 Jystck9ThtAxsClckwsPstvPosStatus "Reports when the current joystick position is on the positive travel side (forward, right, clockwise, up) relative to the";
CM_ SG_ 2365400574 Jystck9ThtAxsCntrClckwsNgtvPsStt "Reports when the current joystick position is on the negative travel side (back, left, counterclockwise, down) relative to the";
CM_ SG_ 2365400574 Jystck9ThetaAxisNeutralPosStatus "Reports when the current joystick position is in the neutral position for that axis of travel. The neutral position";
CM_ SG_ 2365400574 Joystick9GripYAxisPos "The position of the joystick grip in the relative motion of travel from the neutral position. Position value of 0 is Neutral and";
CM_ SG_ 2365400574 Jystck9GrpYAxsLvrFrwrdPstvPsStts "Reports when the current joystick grip position is on the positive travel side (forward, right, clockwise, up) relative to the";
CM_ SG_ 2365400574 Jystck9GrpYAxsLvrBckNgtvPsStatus "Reports when the current joystick grip position is on the negative travel side (back, left, counterclockwise, down) relative";
CM_ SG_ 2365400574 Jystck9GripYAxisNeutralPosStatus "Reports when the current joystick grip position is in the neutral position for that axis of travel. The neutral position";
CM_ SG_ 2365400574 Joystick9GripXAxisPos "The position of the joystick grip in the relative motion of travel from the neutral position. Position value of 0 is Neutral and";
CM_ SG_ 2365400574 Jystck9GrpXAxsLvrRghtPstvPsSttus "Reports when the current joystick grip position is on the positive travel side (forward, right, clockwise, up) relative to the";
CM_ SG_ 2365400574 Jystck9GrpXAxsLvrLftNgtvPsStatus "Reports when the current joystick grip position is on the negative travel side (back, left, counterclockwise, down) relative";
CM_ SG_ 2365400574 Jystck9GripXAxisNeutralPosStatus "Reports when the current joystick grip position is in the neutral position for that axis of travel. The neutral position";
CM_ BO_ 2365401086 "Extended Joystick Message 8";
CM_ SG_ 2365401086 Jystick8GripXAxisDetentPosStatus "Reports when the current joystick grip position is in the detent position for that axis of travel.";
CM_ SG_ 2365401086 Jystick8GripYAxisDetentPosStatus "Reports when the current joystick grip position is in the detent position for that axis of travel.";
CM_ SG_ 2365401086 Jystick8ThetaAxisDetentPosStatus "Reports when the current joystick position is in the detent position for that axis of travel.";
CM_ SG_ 2365401086 Joystick8ThetaAxisPos "The position of the joystick in the relative motion of travel from the neutral position. Position value of 0 is Neutral and";
CM_ SG_ 2365401086 Jystck8ThtAxsClckwsPstvPosStatus "Reports when the current joystick position is on the positive travel side (forward, right, clockwise, up) relative to the";
CM_ SG_ 2365401086 Jystck8ThtAxsCntrClckwsNgtvPsStt "Reports when the current joystick position is on the negative travel side (back, left, counterclockwise, down) relative to the";
CM_ SG_ 2365401086 Jystck8ThetaAxisNeutralPosStatus "Reports when the current joystick position is in the neutral position for that axis of travel. The neutral position";
CM_ SG_ 2365401086 Joystick8GripYAxisPos "The position of the joystick grip in the relative motion of travel from the neutral position. Position value of 0 is Neutral and";
CM_ SG_ 2365401086 Jystck8GrpYAxsLvrFrwrdPstvPsStts "Reports when the current joystick grip position is on the positive travel side (forward, right, clockwise, up) relative to the";
CM_ SG_ 2365401086 Jystck8GrpYAxsLvrBckNgtvPsStatus "Reports when the current joystick grip position is on the negative travel side (back, left, counterclockwise, down) relative";
CM_ SG_ 2365401086 Jystck8GripYAxisNeutralPosStatus "Reports when the current joystick grip position is in the neutral position for that axis of travel. The neutral position";
CM_ SG_ 2365401086 Joystick8GripXAxisPos "The position of the joystick grip in the relative motion of travel from the neutral position. Position value of 0 is Neutral and";
CM_ SG_ 2365401086 Jystck8GrpXAxsLvrRghtPstvPsSttus "Reports when the current joystick grip position is on the positive travel side (forward, right, clockwise, up) relative to the";
CM_ SG_ 2365401086 Jystck8GrpXAxsLvrLftNgtvPsStatus "Reports when the current joystick grip position is on the negative travel side (back, left, counterclockwise, down) relative";
CM_ SG_ 2365401086 Jystck8GripXAxisNeutralPosStatus "Reports when the current joystick grip position is in the neutral position for that axis of travel. The neutral position";
CM_ BO_ 2365401598 "Extended Joystick Message 7";
CM_ SG_ 2365401598 Jystick7GripXAxisDetentPosStatus "Reports when the current joystick grip position is in the detent position for that axis of travel.";
CM_ SG_ 2365401598 Jystick7GripYAxisDetentPosStatus "Reports when the current joystick grip position is in the detent position for that axis of travel.";
CM_ SG_ 2365401598 Jystick7ThetaAxisDetentPosStatus "Reports when the current joystick position is in the detent position for that axis of travel.";
CM_ SG_ 2365401598 Joystick7ThetaAxisPos "The position of the joystick in the relative motion of travel from the neutral position. Position value of 0 is Neutral and";
CM_ SG_ 2365401598 Jystck7ThtAxsClckwsPstvPosStatus "Reports when the current joystick position is on the positive travel side (forward, right, clockwise, up) relative to the";
CM_ SG_ 2365401598 Jystck7ThtAxsCntrClckwsNgtvPsStt "Reports when the current joystick position is on the negative travel side (back, left, counterclockwise, down) relative to the";
CM_ SG_ 2365401598 Jystck7ThetaAxisNeutralPosStatus "Reports when the current joystick position is in the neutral position for that axis of travel. The neutral position";
CM_ SG_ 2365401598 Joystick7GripYAxisPos "The position of the joystick grip in the relative motion of travel from the neutral position. Position value of 0 is Neutral and";
CM_ SG_ 2365401598 Jystck7GrpYAxsLvrFrwrdPstvPsStts "Reports when the current joystick grip position is on the positive travel side (forward, right, clockwise, up) relative to the";
CM_ SG_ 2365401598 Jystck7GrpYAxsLvrBckNgtvPsStatus "Reports when the current joystick grip position is on the negative travel side (back, left, counterclockwise, down) relative";
CM_ SG_ 2365401598 Jystck7GripYAxisNeutralPosStatus "Reports when the current joystick grip position is in the neutral position for that axis of travel. The neutral position";
CM_ SG_ 2365401598 Joystick7GripXAxisPos "The position of the joystick grip in the relative motion of travel from the neutral position. Position value of 0 is Neutral and";
CM_ SG_ 2365401598 Jystck7GrpXAxsLvrRghtPstvPsSttus "Reports when the current joystick grip position is on the positive travel side (forward, right, clockwise, up) relative to the";
CM_ SG_ 2365401598 Jystck7GrpXAxsLvrLftNgtvPsStatus "Reports when the current joystick grip position is on the negative travel side (back, left, counterclockwise, down) relative";
CM_ SG_ 2365401598 Jystck7GripXAxisNeutralPosStatus "Reports when the current joystick grip position is in the neutral position for that axis of travel. The neutral position";
CM_ BO_ 2365402110 "Extended Joystick Message 6";
CM_ SG_ 2365402110 Jystick6GripXAxisDetentPosStatus "Reports when the current joystick grip position is in the detent position for that axis of travel.";
CM_ SG_ 2365402110 Jystick6GripYAxisDetentPosStatus "Reports when the current joystick grip position is in the detent position for that axis of travel.";
CM_ SG_ 2365402110 Jystick6ThetaAxisDetentPosStatus "Reports when the current joystick position is in the detent position for that axis of travel.";
CM_ SG_ 2365402110 Joystick6ThetaAxisPos "The position of the joystick in the relative motion of travel from the neutral position. Position value of 0 is Neutral and";
CM_ SG_ 2365402110 Jystck6ThtAxsClckwsPstvPosStatus "Reports when the current joystick position is on the positive travel side (forward, right, clockwise, up) relative to the";
CM_ SG_ 2365402110 Jystck6ThtAxsCntrClckwsNgtvPsStt "Reports when the current joystick position is on the negative travel side (back, left, counterclockwise, down) relative to the";
CM_ SG_ 2365402110 Jystck6ThetaAxisNeutralPosStatus "Reports when the current joystick position is in the neutral position for that axis of travel. The neutral position";
CM_ SG_ 2365402110 Joystick6GripYAxisPos "The position of the joystick grip in the relative motion of travel from the neutral position. Position value of 0 is Neutral and";
CM_ SG_ 2365402110 Jystck6GrpYAxsLvrFrwrdPstvPsStts "Reports when the current joystick grip position is on the positive travel side (forward, right, clockwise, up) relative to the";
CM_ SG_ 2365402110 Jystck6GrpYAxsLvrBckNgtvPsStatus "Reports when the current joystick grip position is on the negative travel side (back, left, counterclockwise, down) relative";
CM_ SG_ 2365402110 Jystck6GripYAxisNeutralPosStatus "Reports when the current joystick grip position is in the neutral position for that axis of travel. The neutral position";
CM_ SG_ 2365402110 Joystick6GripXAxisPos "The position of the joystick grip in the relative motion of travel from the neutral position. Position value of 0 is Neutral and";
CM_ SG_ 2365402110 Jystck6GrpXAxsLvrRghtPstvPsSttus "Reports when the current joystick grip position is on the positive travel side (forward, right, clockwise, up) relative to the";
CM_ SG_ 2365402110 Jystck6GrpXAxsLvrLftNgtvPsStatus "Reports when the current joystick grip position is on the negative travel side (back, left, counterclockwise, down) relative";
CM_ SG_ 2365402110 Jystck6GripXAxisNeutralPosStatus "Reports when the current joystick grip position is in the neutral position for that axis of travel. The neutral position";
CM_ BO_ 2365402622 "Extended Joystick Message 5";
CM_ SG_ 2365402622 Jystick5GripXAxisDetentPosStatus "Reports when the current joystick grip position is in the detent position for that axis of travel.";
CM_ SG_ 2365402622 Jystick5GripYAxisDetentPosStatus "Reports when the current joystick grip position is in the detent position for that axis of travel.";
CM_ SG_ 2365402622 Jystick5ThetaAxisDetentPosStatus "Reports when the current joystick position is in the detent position for that axis of travel.";
CM_ SG_ 2365402622 Joystick5ThetaAxisPos "The position of the joystick in the relative motion of travel from the neutral position. Position value of 0 is Neutral and";
CM_ SG_ 2365402622 Jystck5ThtAxsClckwsPstvPosStatus "Reports when the current joystick position is on the positive travel side (forward, right, clockwise, up) relative to the";
CM_ SG_ 2365402622 Jystck5ThtAxsCntrClckwsNgtvPsStt "Reports when the current joystick position is on the negative travel side (back, left, counterclockwise, down) relative to the";
CM_ SG_ 2365402622 Jystck5ThetaAxisNeutralPosStatus "Reports when the current joystick position is in the neutral position for that axis of travel. The neutral position";
CM_ SG_ 2365402622 Joystick5GripYAxisPos "The position of the joystick grip in the relative motion of travel from the neutral position. Position value of 0 is Neutral and";
CM_ SG_ 2365402622 Jystck5GrpYAxsLvrFrwrdPstvPsStts "Reports when the current joystick grip position is on the positive travel side (forward, right, clockwise, up) relative to the";
CM_ SG_ 2365402622 Jystck5GrpYAxsLvrBckNgtvPsStatus "Reports when the current joystick grip position is on the negative travel side (back, left, counterclockwise, down) relative";
CM_ SG_ 2365402622 Jystck5GripYAxisNeutralPosStatus "Reports when the current joystick grip position is in the neutral position for that axis of travel. The neutral position";
CM_ SG_ 2365402622 Joystick5GripXAxisPos "The position of the joystick grip in the relative motion of travel from the neutral position. Position value of 0 is Neutral and";
CM_ SG_ 2365402622 Jystck5GrpXAxsLvrRghtPstvPsSttus "Reports when the current joystick grip position is on the positive travel side (forward, right, clockwise, up) relative to the";
CM_ SG_ 2365402622 Jystck5GrpXAxsLvrLftNgtvPsStatus "Reports when the current joystick grip position is on the negative travel side (back, left, counterclockwise, down) relative";
CM_ SG_ 2365402622 Jystck5GripXAxisNeutralPosStatus "Reports when the current joystick grip position is in the neutral position for that axis of travel. The neutral position";
CM_ BO_ 2365403134 "Extended Joystick Message 4";
CM_ SG_ 2365403134 Jystick4GripXAxisDetentPosStatus "Reports when the current joystick grip position is in the detent position for that axis of travel.";
CM_ SG_ 2365403134 Jystick4GripYAxisDetentPosStatus "Reports when the current joystick grip position is in the detent position for that axis of travel.";
CM_ SG_ 2365403134 Jystick4ThetaAxisDetentPosStatus "Reports when the current joystick position is in the detent position for that axis of travel.";
CM_ SG_ 2365403134 Joystick4ThetaAxisPos "The position of the joystick in the relative motion of travel from the neutral position. Position value of 0 is Neutral and";
CM_ SG_ 2365403134 Jystck4ThtAxsClckwsPstvPosStatus "Reports when the current joystick position is on the positive travel side (forward, right, clockwise, up) relative to the";
CM_ SG_ 2365403134 Jystck4ThtAxsCntrClckwsNgtvPsStt "Reports when the current joystick position is on the negative travel side (back, left, counterclockwise, down) relative to the";
CM_ SG_ 2365403134 Jystck4ThetaAxisNeutralPosStatus "Reports when the current joystick position is in the neutral position for that axis of travel. The neutral position";
CM_ SG_ 2365403134 Joystick4GripYAxisPos "The position of the joystick grip in the relative motion of travel from the neutral position. Position value of 0 is Neutral and";
CM_ SG_ 2365403134 Jystck4GrpYAxsLvrFrwrdPstvPsStts "Reports when the current joystick grip position is on the positive travel side (forward, right, clockwise, up) relative to the";
CM_ SG_ 2365403134 Jystck4GrpYAxsLvrBckNgtvPsStatus "Reports when the current joystick grip position is on the negative travel side (back, left, counterclockwise, down) relative";
CM_ SG_ 2365403134 Jystck4GripYAxisNeutralPosStatus "Reports when the current joystick grip position is in the neutral position for that axis of travel. The neutral position";
CM_ SG_ 2365403134 Joystick4GripXAxisPos "The position of the joystick grip in the relative motion of travel from the neutral position. Position value of 0 is Neutral and";
CM_ SG_ 2365403134 Jystck4GrpXAxsLvrRghtPstvPsSttus "Reports when the current joystick grip position is on the positive travel side (forward, right, clockwise, up) relative to the";
CM_ SG_ 2365403134 Jystck4GrpXAxsLvrLftNgtvPsStatus "Reports when the current joystick grip position is on the negative travel side (back, left, counterclockwise, down) relative";
CM_ SG_ 2365403134 Jystck4GripXAxisNeutralPosStatus "Reports when the current joystick grip position is in the neutral position for that axis of travel. The neutral position";
CM_ BO_ 2365400062 "Used to transfer information about the measured status of three additional axes of a joystick and switches of the joystick";
CM_ SG_ 2365400062 Jystck10GripXAxisDetentPosStatus "Reports when the current joystick grip position is in the detent position for that axis of travel.";
CM_ SG_ 2365400062 Jystck10GripYAxisDetentPosStatus "Reports when the current joystick grip position is in the detent position for that axis of travel.";
CM_ SG_ 2365400062 Jystck10ThetaAxisDetentPosStatus "Reports when the current joystick position is in the detent position for that axis of travel.";
CM_ SG_ 2365400062 Joystick10ThetaAxisPos "The position of the joystick in the relative motion of travel from the neutral position. Position value of 0 is Neutral and";
CM_ SG_ 2365400062 Jystck10ThtAxsClckwsPstvPsStatus "Reports when the current joystick position is on the positive travel side (forward, right, clockwise, up) relative to the";
CM_ SG_ 2365400062 Jystck10ThtAxsCntrClckwsNgtvPsSt "Reports when the current joystick position is on the negative travel side (back, left, counterclockwise, down) relative to the";
CM_ SG_ 2365400062 Jystck10ThtaAxisNeutralPosStatus "Reports when the current joystick position is in the neutral position for that axis of travel. The neutral position";
CM_ SG_ 2365400062 Joystick10GripYAxisPos "The position of the joystick grip in the relative motion of travel from the neutral position. Position value of 0 is Neutral and";
CM_ SG_ 2365400062 Jystck10GrpYAxsLvrFrwrdPstvPsStt "Reports when the current joystick grip position is on the positive travel side (forward, right, clockwise, up) relative to the";
CM_ SG_ 2365400062 Jystck10GrpYAxsLvrBckNgtvPsSttus "Reports when the current joystick grip position is on the negative travel side (back, left, counterclockwise, down) relative";
CM_ SG_ 2365400062 Jystck10GrpYAxisNeutralPosStatus "Reports when the current joystick grip position is in the neutral position for that axis of travel. The neutral position";
CM_ SG_ 2365400062 Joystick10GripXAxisPos "The position of the joystick grip in the relative motion of travel from the neutral position. Position value of 0 is Neutral and";
CM_ SG_ 2365400062 Jystck10GrpXAxsLvrRghtPstvPsStts "Reports when the current joystick grip position is on the positive travel side (forward, right, clockwise, up) relative to the";
CM_ SG_ 2365400062 Jystck10GrpXAxsLvrLftNgtvPsSttus "Reports when the current joystick grip position is on the negative travel side (back, left, counterclockwise, down) relative";
CM_ SG_ 2365400062 Jystck10GrpXAxisNeutralPosStatus "Reports when the current joystick grip position is in the neutral position for that axis of travel. The neutral position";
CM_ BO_ 2566713598 "Contains information on the engine fuel and lube system";
CM_ SG_ 2566713598 EngFuelFilterIntakeAbsPress "Absolute pressure of fuel at the intake of the fuel filter (suction side) located between the fuel tank and the fuel supply";
CM_ BO_ 2499604478 "Engine related parameters.";
CM_ SG_ 2499604478 EngExhstGsRcrcltn1OutletAbsPress "EGR outlet absolute pressure is measured after the EGR 1 valve. See SPN 5019 for 1 byte resolution.";
CM_ SG_ 2499604478 EngExhstGsRcrcltn1IntakeAbsPress "EGR intake absolute pressure measured before the EGR 1 valve.";
CM_ BO_ 2499608830 "Engine Fluid/Pressure 10";
CM_ SG_ 2499608830 EngExhstGsRcrcltn2IntakeAbsPress "EGR intake absolute pressure measured before the EGR 2 valve.";
CM_ SG_ 2499608830 EngExhstGsRcrcltn2OutletAbsPress "Absolute Pressure immediately after the EGR2 valve";
CM_ SG_ 2499608830 EngExhstGsRcrclation2IntakePress "EGR2 intake gauge pressure is measured after EGR2 cooler and before EGR2 valve";
CM_ SG_ 2499608830 EngExhstGsRcirculation2DiffPress "Differential Pressure across the Exhaust Gas Recirculation 2 (EGR2) system.";
CM_ BO_ 2432499198 "Engine related parameters";
CM_ SG_ 2432499198 CmmndedEngFuelInjectionCtrlPress "Provides the commanded set point value for the engine fuel injection control pressure.";
CM_ SG_ 2432499198 CommandedEngFuelRailPress "Provides the commanded set point value for the engine fuel rail pressure";
CM_ SG_ 2432499198 EngExhstGsRcirculation2Valve2Pos "The position of the second exhaust gas recirculation valve of EGR 2 expressed as a percentage of full travel. 0% means";
CM_ SG_ 2432499198 EngExhstGsRecirculation2ValvePos "Position of EGR2 valve expressed as a percentage of full travel. 0% means the valve is closed and no exhaust gas is";
CM_ BO_ 2633825022 "Engine related parameters";
CM_ SG_ 2633825022 EngExhstGsRcrculation2Valve2Ctrl "Desired percentage of maximum Exhaust Gas Recirculation 2 (EGR2) valve 2 opening. 0% means the valve is closed.";
CM_ SG_ 2633825022 EngExhstGsRcirculation2ValveCtrl "Desired percentage of maximum Exhaust Gas Recirculation 2 (EGR2) valve opening. 0% means the valve is closed.";
CM_ BO_ 2633826046 "Electronic Engine Controller 10";
CM_ SG_ 2633826046 EGR2CoolerBypassActuatorPos "EGR2 Cooler Bypass Actuator position, where 0% = Fully Closed (no gas flowing through the bypass), and 100% = Fully";
CM_ SG_ 2633826046 EngExhstGsRcrcltn2ClerEfficiency "Exhaust Gas Recirculation 2 cooler efficiency is an indication of the cooler’s ability to reduce the temperature of the";
CM_ SG_ 2633826046 EngExhstGsRcrcltn2ClrIntkGsAbsPr "Exhaust Gas Recirculation 2 gas absolute pressure is measured at EGR2 cooler intake. See SPN 5253 for EGR2";
CM_ SG_ 2633826046 EngExhstGsRcrcltn2ClerIntakeTemp "Exhaust Gas Recirculation 2 (EGR2) Temperature measured at EGR2 cooler intake. See SPN 5255 for Engine EGR2";
CM_ BO_ 2566711294 "The EC3 message contains a static engine friction torque map consisting of torque points that correspond to the speed";
CM_ SG_ 2566711294 EngFrctnPrcentTorqueAtIdlePoint7 "The static portion of the friction torque at speed point 7 (SPN 533) of the engine torque map in the engine configuration";
CM_ SG_ 2566711294 EngFrctnPrcentTorqueAtIdlePoint6 "For engine configuration map modes 1 and 2, this is the static portion of the friction torque at speed point 6 (SPN 532) of";
CM_ SG_ 2566711294 EngFrctnPrcentTorqueAtIdlePoint5 "The static portion of the friction torque at speed point 5 (SPN 531) of the engine torque map in the engine configuration";
CM_ SG_ 2566711294 EngFrctnPrcentTorqueAtIdlePoint4 "The static portion of the friction torque at speed point 4 (SPN 530) of the engine torque map in the engine configuration";
CM_ SG_ 2566711294 EngFrctnPrcentTorqueAtIdlePoint3 "The static portion of the friction torque at speed point 3 (SPN 529) of the engine torque map in the engine configuration";
CM_ SG_ 2566711294 EngFrctnPrcentTorqueAtIdlePoint2 "The static portion of the friction torque at speed point 2 (SPN 528) of the engine torque map in the engine configuration";
CM_ SG_ 2566711294 EngFrctnPrcentTorqueAtIdlePoint1 "The static portion of the friction torque at speed point 1 (SPN 188) of the engine torque map in the engine configuration";
CM_ BO_ 2566749438 "Diesel Particulate Filter Control 1";
CM_ SG_ 2566749438 DslPrtcltFltrActvRgnrtnFrcdSttus "Indicates the forced execution status of diesel particulate filter regeneration.";
CM_ SG_ 2566749438 ExhaustSystemHighTempLampCmd "Command to control the exhaust system high temperature lamp. This lamp indicates that the exhaust system";
CM_ SG_ 2566749438 DslPrtcltFltrAtmtcActvRgnrtnIntt "Indicates the configuration of diesel particulate filter active regeneration automatic initiation.";
CM_ SG_ 2566749438 DslPrtcltFltrActvRgnrtnInhbtdDTV "Speed";
CM_ SG_ 2566749438 DslPrtcltFltrActvRgnrtnInhbtdDTE "Indicates the state of diesel particulate filter active regeneration inhibition due to the engine not being warmed up.";
CM_ SG_ 2566749438 DslPrtcltFltrActvRgnrtnInhb_0000 "Indicates the state of diesel particulate filter active regeneration inhibition due to a permanent system lockout.";
CM_ SG_ 2566749438 DslPrtcltFltrActvRgnrtnInhbtdDTT "Indicates the state of diesel particulate filter active regeneration inhibition due to a temporary system lockout.";
CM_ SG_ 2566749438 DslPrtcltFltrActvRgnrtnInhbtdDTS "Indicates the state of diesel particulate filter active regeneration inhibition due to a system timeout.Indicates the state of diesel particulate filter active regeneration inhibition due to a system fault being active.Indicates the state of diesel particulate filter active regeneration inhibition due to the service brake being active.";
CM_ SG_ 2566749438 DslPrtcltFltrActvRgnrtnInhbtdDTL "Indicates the state of diesel particulate filter active regeneration inhibition due to the exhaust gas temperature being too";
CM_ SG_ 2566749438 DslPrtcltFltrActvRgnrtnInhb_0001 "Indicates the state of diesel particulate filter active regeneration inhibition due to the parking brake being not set.";
CM_ SG_ 2566749438 DslPrtcltFltrActvRgnrtnInhb_0002 "Speed";
CM_ SG_ 2566749438 DslPrtcltFltrActvRgnrtnInhbtdDTO "Indicates the state of diesel particulate filter active regeneration inhibition due to the transmission being out of neutral.";
CM_ SG_ 2566749438 DslPrtcltFltrActvRgnrtnInhbtdDTA "Indicates the state of diesel particulate filter active regeneration inhibition due to the accelerator pedal being off idle.";
CM_ SG_ 2566749438 DslPrtcltFltrActvRgnrtnInhbtdDTP "Indicates the state of diesel particulate filter active regeneration inhibition due to the PTO being active.";
CM_ SG_ 2566749438 DslPrtcltFltrActvRgnrtnInhbtdDTC "Indicates the state of diesel particulate filter active regeneration inhibition due to the clutch being disengaged.";
CM_ SG_ 2566749438 DslPrtcltFltrActvRgnrtnInhbtdDTI "Indicates the state of diesel particulate filter active regeneration inhibition due to the Diesel Particulate Filter Regeneration";
CM_ SG_ 2566749438 DslPrtcltFltrActvRgnrtnInhbtdStt "Indicates the state of diesel particulate filter active regeneration inhibition.";
CM_ SG_ 2566749438 DieselParticulateFilterStatus "Indicates the state of the diesel particulate filter regeneration need and urgency.";
CM_ SG_ 2566749438 DslPrtcltFltrActvRgnrationStatus "Indicates the state of diesel particulate filter active regeneration.";
CM_ SG_ 2566749438 DslPrtcltFltrPssvRgnrationStatus "Indicates the state of diesel particulate filter passive regeneration.";
CM_ SG_ 2566749438 DieselParticulateFilterLampCmd "Command to control the diesel particulate filter lamp.";
CM_ BO_ 2566715646 "Additional diesel particulate filter soot parameters for diesel particulate filter 2.";
CM_ SG_ 2566715646 DslPrtculateFilter2SootSignalMin "Minimum output signal level of the current soot measurement from diesel particulate filter 2 soot sensor. This is a";
CM_ SG_ 2566715646 DslPrtculateFilter2SootSignalMax "Maximum output signal level of the current soot measurement from diesel particulate filter 2 soot sensor. This is a";
CM_ SG_ 2566715646 DslPrtcltFltr2StSgnlStndrdDvtion "Standard deviation of the soot measurement from diesel particulate filter 2 soot sensor.";
CM_ BO_ 2566724606 "Diesel particulate filter soot parameters for diesel particulate filter 2.";
CM_ SG_ 2566724606 DslPrtcltFltr2StSnsrPrlminaryFMI "Used to identify the applicable J1939-73 FMI detected in the soot sensor signal by the manufacturer’s sensor control";
CM_ SG_ 2566724606 DslPrtcltFilter2MedianSootSignal "Median output signal level from diesel particulate filter 2 soot sensor.";
CM_ SG_ 2566724606 DslPrtclateFilter2MeanSootSignal "Mean output signal level from diesel particulate filter 2 soot sensor.";
CM_ SG_ 2566724606 DslParticulateFilter2SootDensity "Soot density in diesel particulate filter 2.";
CM_ SG_ 2566724606 DieselParticulateFilter2SootMass "Soot mass in diesel particulate filter 2.";
CM_ BO_ 2566715902 "Additional diesel particulate filter soot parameters for diesel particulate filter 1.";
CM_ SG_ 2566715902 DslPrtculateFilter1SootSignalMin "Minimum output signal level of the current soot measurement from diesel particulate filter 1 soot sensor. This is a";
CM_ SG_ 2566715902 DslPrtculateFilter1SootSignalMax "Maximum output signal level of the current soot measurement from diesel particulate filter 1 soot sensor. This is a";
CM_ SG_ 2566715902 DslPrtcltFltr1StSgnlStndrdDvtion "Standard deviation of the soot measurement from diesel particulate filter 1 soot sensor.";
CM_ BO_ 2566724862 "Diesel particulate filter soot parameters for diesel particulate filter 1.";
CM_ SG_ 2566724862 DslPrtcltFltr1StSnsrPrlminaryFMI "Used to identify the applicable J1939-73 FMI detected in the soot sensor signal by the manufacturer’s sensor control";
CM_ SG_ 2566724862 DslPrtcltFilter1MedianSootSignal "Median output signal level from diesel particulate filter 1 soot sensor.";
CM_ SG_ 2566724862 DslPrtclateFilter1MeanSootSignal "Mean output signal level from diesel particulate filter 1 soot sensor.";
CM_ SG_ 2566724862 DslParticulateFilter1SootDensity "Soot density in diesel particulate filter 1.";
CM_ SG_ 2566724862 DieselParticulateFilter1SootMass "Soot mass in diesel particulate filter 1.";
CM_ BO_ 2566718718 "This message will be transmitted by the controller that is illuminating the lamps.";
CM_ SG_ 2566718718 VehicleBatteryChargingLampData "This parameter provides measured data from the Vehicle Battery Charging Lamp.";
CM_ SG_ 2566718718 VehicleHVACRecirculationLampData "This parameter provides measured data from the Vehicle HVAC Recirculation Lamp.";
CM_ SG_ 2566718718 VehicleAirPressLowLampData "This parameter provides measured data from the Vehicle Air Pressure Low Lamp.";
CM_ SG_ 2566718718 VehicleFuelLevelLowLampData "This parameter provides measured data from theVehicle Fuel Level Low Lamp.";
CM_ SG_ 2566718718 VehicleBatteryVoltageLowLampData "This parameter provides measured data from the Vehicle Battery Voltage Low Lamp.";
CM_ BO_ 2566718974 "This message will be transmitted by the controller that is illuminating the lamps.";
CM_ SG_ 2566718974 EngWaitToStartLampData "This parameter provides measured data from the Engine Wait To Start Lamp. See SPN 1081 for the command.";
CM_ SG_ 2566718974 EngFuelFilterRestrictedLampData "Command signal directly controlling the Vehicle Fuel Filter Restricted Lamp.";
CM_ SG_ 2566718974 EngAirFilterRestrictionLampData "This parameter provides measured data from the Engine Air Filter Restriction Lamp.";
CM_ SG_ 2566718974 EngIdleManagementActiveLampData "This parameter provides measured data from the Engine Idle Management Active Lamp.";
CM_ SG_ 2566718974 EngCoolantLevelLowLampData "This parameter provides measured data from the Engine Coolant Level Low Lamp.";
CM_ SG_ 2566718974 EngCoolantTempHighLampData "This parameter provides measured data from the Engine Coolant Temperature High Lamp.";
CM_ SG_ 2566718974 EngOilPressLowLampData "This parameter provides measured data from the Engine Oil Pressure Low Lamp.";
CM_ SG_ 2566718974 CmprssnBrkEnblSwtchIndctrLmpData "This parameter provides measured data from the Compression Brake Enable Switch Indicator Lamp.";
CM_ SG_ 2566718974 EngBrakeActiveLampData "This parameter provides measured data from the Engine Brake Active Lamp.";
CM_ SG_ 2566718974 OBDMalfunctionIndicatorLampData "This parameter provides measured data from the OBD Malfunction Indicator Lamp.";
CM_ SG_ 2566718974 EngRedStopLampData "This parameter provides measured data from the Engine Red Stop Lamp.";
CM_ SG_ 2566718974 EngAmberWarningLampData "This parameter provides measured data from the Engine Amber Warning Lamp.";
CM_ SG_ 2566718974 EngProtectLampData "This parameter provides measured data from the Engine Protect Lamp.";
CM_ BO_ 2566719230 "Message that directly controls the driver indicator lamps. See also PGN 64775 for additional lamps and PGN 64772 for";
CM_ SG_ 2566719230 VehicleBatteryChargingLampCmd "Command signal directly controlling the Vehicle Battery Charging Lamp.";
CM_ SG_ 2566719230 VehicleHVACRecirculationLampCmd "Command signal directly controlling the Vehicle HVAC Recirculation Lamp.";
CM_ SG_ 2566719230 VehicleAirPressLowLampCmd "Command signal directly controlling the Vehicle Air Pressure Low Lamp.";
CM_ SG_ 2566719230 VehicleFuelLevelLowLampCmd "Command signal directly controlling the Vehicle Fuel Level Low Lamp.";
CM_ SG_ 2566719230 VehicleBatteryVoltageLowLampCmd "Command signal directly controlling the Vehicle Battery Voltage Low Lamp.";
CM_ BO_ 2560818942 "DM32 provides the DTCs and associated timers";
CM_ SG_ 2560818942 DTCTimeUntilDerate "This timer provides the number of hours the malfunction has until the OBD required derate will occur";
CM_ SG_ 2560818942 DTCTotalPreviouslyActiveTime "This timer provides the number of hours the NOx malfunction has been confirmed and previously active";
CM_ SG_ 2560818942 DTCTotalActiveTime "This timer provides the total number of hours the DTC has been confirmed and active";
CM_ SG_ 2560818942 FailureModeIdentifier1 "The FMI defines the type of failure detected in the subsystem identified by an SPN.";
CM_ SG_ 2560818942 SPN1High "SPN #1 (Conversion Version 4)";
CM_ SG_ 2560818942 SPN1 "SPN #1 (Conversion Version 4)";
CM_ BO_ 2561212158 "This provides ASCII text information, for example to an display instrument. Broadcast rate should be on event and 1-5";
CM_ SG_ 2561212158 TextDisplayIndex "Used for overwriting consecutive bytes of a displayed string when byte 1 \"Text Display Instructions\" state is set for";
CM_ SG_ 2561212158 TextDisplayInstructions "This parameter describes the status for the display how to show the information.";
CM_ BO_ 2566746366 "Door ramp control";
CM_ SG_ 2566746366 RetractStatusOfRamp5 "Retract status of ramp at doorway 5, counting from front to back on the vehicle.";
CM_ SG_ 2566746366 RetractStatusOfRamp4 "Retract status of ramp at doorway 4, counting from front to back on the vehicle.";
CM_ SG_ 2566746366 MovementStatusOfRamp5 "Movement status of ramp at doorway 5, counting from front to back on the vehicle.";
CM_ SG_ 2566746366 MovementStatusOfRamp4 "Movement status of ramp at doorway 4, counting from front to back on the vehicle.";
CM_ SG_ 2566746366 EnableStatusOfRamp5 "Enable status of ramp at doorway 5, counting from front to back on the vehicle.";
CM_ SG_ 2566746366 EnableStatusOfRamp4 "Enable status of ramp at doorway 4, counting from front to back on the vehicle.";
CM_ SG_ 2566746366 MovementStatusOfRamp3 "Movement status of ramp at doorway 3, counting from front to back on the vehicle.";
CM_ SG_ 2566746366 EnableStatusOfRamp3 "Enable status of ramp at doorway 3, counting from front to back on the vehicle.";
CM_ SG_ 2566746366 RetractStatusOfRamp3 "Retract status of ramp at doorway 3, counting from front to back on the vehicle.";
CM_ SG_ 2566746366 MovementStatusOfRamp2 "Movement status of ramp at doorway 2, counting from front to back on the vehicle.";
CM_ SG_ 2566746366 EnableStatusOfRamp2 "Enable status of ramp at doorway 2, counting from front to back on the vehicle.";
CM_ SG_ 2566746366 RetractStatusOfRamp2 "Retract status of ramp at doorway 2, counting from front to back on the vehicle.";
CM_ SG_ 2566746366 MovementStatusOfRamp1 "Movement status of ramp at doorway 1, counting from front to back on the vehicle.";
CM_ SG_ 2566746366 EnableStatusOfRamp1 "Enable status of ramp at doorway 1, counting from front to back on the vehicle.";
CM_ SG_ 2566746366 RetractStatusOfRamp1 "Retract status of ramp at doorway 1, counting from front to back on the vehicle.";
CM_ BO_ 2566750206 "Engine Configuration 2";
CM_ SG_ 2566750206 MaxCrankAttemptsPerStartAttempt "The number of cranking cycles that will be performed before ending the start attempt. This is intended to be used in";
CM_ BO_ 2566755582 "Engine related parameters";
CM_ SG_ 2566755582 CommandedEngIntakeManifoldPress "Provides the commanded set point value for the engine intake manifold pressure.";
CM_ SG_ 2566755582 EngCrnkcsBrtherOilSeparatorSpeed "The speed of a rotating (centrifugal) crankcase oil separator.";
CM_ SG_ 2566755582 EngExhstGsRcirculation1Valve2Pos "The position of the second exhaust gas recirculation valve expressed as a percentage of full travel. Zero percent means";
CM_ SG_ 2566755582 EngExhstGsRecirculation1ValvePos "The position of the exhaust gas recirculation valve expressed as a percentage of full travel. Zero percent means the valve";
CM_ BO_ 2566746110 "Electronic Engine Controller 8";
CM_ SG_ 2566746110 EngExhstGsRcrcltn1ClrIntkGsAbsPr "Exhaust Gas Recirculation gas absolute pressure is measured at the EGR cooler intake. See SPN 3358 for EGR";
CM_ SG_ 2566746110 EngExhstGsRcrcltn1ClerIntakeTemp "Exhaust Gas Recirculation (EGR) Temperature measured at the EGR cooler intake. See SPN 412 for Engine EGR";
CM_ SG_ 2566746110 EngExhstGsRcrcltn1ClerEfficiency "Exhaust Gas Recirculation cooler efficiency is an indication of the cooler’s ability to reduce the temperature of the exhaust";
CM_ SG_ 2566746110 EngExhstGsRcrculation1Valve2Ctrl "Desired percentage of maximum Exhaust Gas Recirculation (EGR) valve opening for valve 2. 0% means valve is closed.";
CM_ BO_ 2566752510 "Engine Fluid Level/Pressure 5";
CM_ SG_ 2566752510 EngIntkVlvActtionOilPressForCyl4 "The gage pressure of the oil in the hydraulic accumulator that powers the engine intake valve for cylinder #4.";
CM_ SG_ 2566752510 EngIntkVlvActtionOilPressForCyl3 "The gage pressure of the oil in the hydraulic accumulator that powers the engine intake valve for cylinder #3.";
CM_ SG_ 2566752510 EngIntkVlvActtionOilPressForCyl2 "The gage pressure of the oil in the hydraulic accumulator that powers the engine intake valve for cylinder #2.";
CM_ SG_ 2566752510 EngIntkVlvActtionOilPressForCyl1 "The gage pressure of the oil in the hydraulic accumulator that powers the engine intake valve for cylinder #1.";
CM_ BO_ 2566752254 "Engine Fluid Level/Pressure 6";
CM_ SG_ 2566752254 EngIntkVlvActtionOilPressForCyl8 "The gage pressure of the oil in the hydraulic accumulator that powers the engine intake valve for cylinder #8.";
CM_ SG_ 2566752254 EngIntkVlvActtionOilPressForCyl7 "The gage pressure of the oil in the hydraulic accumulator that powers the engine intake valve for cylinder #7.";
CM_ SG_ 2566752254 EngIntkVlvActtionOilPressForCyl6 "The gage pressure of the oil in the hydraulic accumulator that powers the engine intake valve for cylinder #6.";
CM_ SG_ 2566752254 EngIntkVlvActtionOilPressForCyl5 "The gage pressure of the oil in the hydraulic accumulator that powers the engine intake valve for cylinder #5.";
CM_ BO_ 2566751998 "Engine Fluid Level/Pressure 7";
CM_ SG_ 2566751998 EngIntkVlvActtonOilPressForCyl12 "The gage pressure of the oil in the hydraulic accumulator that powers the engine intake valve for cylinder #12.";
CM_ SG_ 2566751998 EngIntkVlvActtonOilPressForCyl11 "The gage pressure of the oil in the hydraulic accumulator that powers the engine intake valve for cylinder #11.";
CM_ SG_ 2566751998 EngIntkVlvActtonOilPressForCyl10 "The gage pressure of the oil in the hydraulic accumulator that powers the engine intake valve for cylinder #10.";
CM_ SG_ 2566751998 EngIntkVlvActtionOilPressForCyl9 "The gage pressure of the oil in the hydraulic accumulator that powers the engine intake valve for cylinder #9.";
CM_ BO_ 2566751742 "Engine Fluid Level/Pressure 8";
CM_ SG_ 2566751742 EngIntkVlvActtonOilPressForCyl16 "The gage pressure of the oil in the hydraulic accumulator that powers the engine intake valve for cylinder #16.";
CM_ SG_ 2566751742 EngIntkVlvActtonOilPressForCyl15 "The gage pressure of the oil in the hydraulic accumulator that powers the engine intake valve for cylinder #15.";
CM_ SG_ 2566751742 EngIntkVlvActtonOilPressForCyl14 "The gage pressure of the oil in the hydraulic accumulator that powers the engine intake valve for cylinder #14.";
CM_ SG_ 2566751742 EngIntkVlvActtonOilPressForCyl13 "The gage pressure of the oil in the hydraulic accumulator that powers the engine intake valve for cylinder #13.";
CM_ BO_ 2566751486 "Engine Fluid Level/Pressure 9";
CM_ SG_ 2566751486 EngIntkVlvActtonOilPressForCyl20 "The gage pressure of the oil in the hydraulic accumulator that powers the engine intake valve for cylinder #20.";
CM_ SG_ 2566751486 EngIntkVlvActtonOilPressForCyl19 "The gage pressure of the oil in the hydraulic accumulator that powers the engine intake valve for cylinder #19.";
CM_ SG_ 2566751486 EngIntkVlvActtonOilPressForCyl18 "The gage pressure of the oil in the hydraulic accumulator that powers the engine intake valve for cylinder #18.";
CM_ SG_ 2566751486 EngIntkVlvActtonOilPressForCyl17 "The gage pressure of the oil in the hydraulic accumulator that powers the engine intake valve for cylinder #17.";
CM_ BO_ 2499641854 "Contains information about the EGR Cooler Bypass";
CM_ SG_ 2499641854 EGR1CoolerBypassActuatorPostion "The parameter gives the % open of the EGR Cooler Bypass Actuator, where 0% = Fully Closed (no gas flowing through";
CM_ BO_ 2566748158 "The PGN contains information about spark voltage values for cylinders 1 through 4. This is the secondary voltage of the";
CM_ SG_ 2566748158 EngSparkPlug4 "The measured voltage of the spark event on Cylinder #4";
CM_ SG_ 2566748158 EngSparkPlug3 "The measured voltage of the spark event on Cylinder #3";
CM_ SG_ 2566748158 EngSparkPlug2 "The measured voltage of the spark event on Cylinder #2";
CM_ SG_ 2566748158 EngSparkPlug1 "The measured voltage of the spark event on Cylinder #1";
CM_ BO_ 2566747902 "The PGN contains information about spark voltage values for cylinders 5 through 8. This is the secondary voltage of the";
CM_ SG_ 2566747902 EngSparkPlug8 "The measured voltage of the spark event on Cylinder #8";
CM_ SG_ 2566747902 EngSparkPlug7 "The measured voltage of the spark event on Cylinder #7";
CM_ SG_ 2566747902 EngSparkPlug6 "The measured voltage of the spark event on Cylinder #6";
CM_ SG_ 2566747902 EngSparkPlug5 "The measured voltage of the spark event on Cylinder #5";
CM_ BO_ 2566747646 "The PGN contains information about spark voltage values for cylinders 9 through 12. This is the secondary voltage of the";
CM_ SG_ 2566747646 EngSparkPlug12 "The measured voltage of the spark event on Cylinder #12";
CM_ SG_ 2566747646 EngSparkPlug11 "The measured voltage of the spark event on Cylinder #11";
CM_ SG_ 2566747646 EngSparkPlug10 "The measured voltage of the spark event on Cylinder #10";
CM_ SG_ 2566747646 EngSparkPlug9 "The measured voltage of the spark event on Cylinder #9";
CM_ BO_ 2566747390 "Engine Spark Voltage 4";
CM_ SG_ 2566747390 EngSparkPlug16 "The measured voltage of the spark event on Cylinder #16";
CM_ SG_ 2566747390 EngSparkPlug15 "The measured voltage of the spark event on Cylinder #15";
CM_ SG_ 2566747390 EngSparkPlug14 "The measured voltage of the spark event on Cylinder #14";
CM_ SG_ 2566747390 EngSparkPlug13 "The measured voltage of the spark event on Cylinder #13";
CM_ BO_ 2566747134 "The PGN contains information about spark voltage values for cylinders 17 through 20. This is the secondary voltage of";
CM_ SG_ 2566747134 EngSparkPlug20 "The measured voltage of the spark event on Cylinder #20";
CM_ SG_ 2566747134 EngSparkPlug19 "The measured voltage of the spark event on Cylinder #19";
CM_ SG_ 2566747134 EngSparkPlug18 "The measured voltage of the spark event on Cylinder #18";
CM_ SG_ 2566747134 EngSparkPlug17 "The measured voltage of the spark event on Cylinder #17";
CM_ BO_ 2566746878 "The PGN contains information about spark voltage values for cylinders 21 through 24. This is the secondary voltage of";
CM_ SG_ 2566746878 EngSparkPlug24 "The measured voltage of the spark event on Cylinder #24";
CM_ SG_ 2566746878 EngSparkPlug23 "The measured voltage of the spark event on Cylinder #23";
CM_ SG_ 2566746878 EngSparkPlug22 "The measured voltage of the spark event on Cylinder #22";
CM_ SG_ 2566746878 EngSparkPlug21 "The measured voltage of the spark event on Cylinder #21";
CM_ BO_ 2561277694 "Message containing commands, sent to the forward image controller";
CM_ SG_ 2561277694 LaneDepartureWarningEnableCmd "Command to enable/disable Lane Departure Indication";
CM_ BO_ 2633861886 "Conveys basic SAE J2012 DTC information for on-board or service tool displays.";
CM_ SG_ 2633861886 J2012DTCOccurrenceCount "Number of occurrences of the respective SAE J2012 DTC being conveyed.";
CM_ SG_ 2633861886 J2012DTCStatus "Indicates if the respective SAE J2012 DTC is active or previously active.";
CM_ SG_ 2633861886 J2012DTC "Five character ASCII SAE J2012 DTC, sent most significant byte first.";
CM_ SG_ 2633861886 NumberOfJ2012DTCs "The number J2012 DTCs being conveyed in PGN 64906. If the value of this parameter is zero, the device broadcasting";
CM_ BO_ 2565873150 "Contains information which relates to a steering angle sensor.";
CM_ SG_ 2565873150 MessageChecksum "The message checksum is used to verify the signal path from the demanding device to the steering controller. The";
CM_ SG_ 2565873150 MessageCounter "The message counter is to verify the signal path from the demanding device to the steering controller. The support of this";
CM_ SG_ 2565873150 SteerAngleSensorCalibrated "This signal indicates the calibration status of the steering angle sensor.";
CM_ SG_ 2565873150 SteerAngleSensorActiveMode "This signal indicates the operational mode of the steering angle sensor.";
CM_ SG_ 2565873150 SteerWheelAngleRange "The signal indicates the range of the steering wheel angle the sensor element is capable to measure. The steering wheel";
CM_ SG_ 2565873150 SteerWheelAngleRangeCounterType "The signal indicates whether the steering wheel angle sensor is capable of absolute measuring of the number of steering";
CM_ SG_ 2565873150 SteerWheelAngleRangeCounter "The signal indicates the number of steering wheel angle range overflows if the operating range of steering wheel is";
CM_ SG_ 2565873150 SteerWheelAngle "The main operator`s steering wheel angle (on the steering column, not the actual wheel angle). The vehicle being steered";
CM_ BO_ 2566745854 "Aftertreatment 1 SCR Service Information";
CM_ SG_ 2566745854 Aftrtrtmnt1SCRCtlystCnvrsnEffcnc "The SCR catalyst conversion efficiency percentage. Calculated as 100 times the catalyst intake NOx minus the catalyst";
CM_ SG_ 2566745854 Aftrtrtmnt1SCRCmmnddCtlystRgntCn "This parameter transmits the amount of reagent that the emissions control system has requested to be used, averaged";
CM_ SG_ 2566745854 Aftrtrtmnt1SCRAvrgCtlystRgntCnsm "Measured use of reagent by a Selective Catalytic Reduction system for exhaust emission control, averaged over the";
CM_ SG_ 2566745854 Aftrtrtmnt1DslExhstFldTnkLwLvlIn "The distance traveled while diesel exhaust fluid is low/empty or driver warning/inducement strategy is active. Note:";
CM_ BO_ 2566751230 "Transfer Case Information";
CM_ SG_ 2566751230 TransferCaseStatus "This parameter describes the feedback from the transfer case controller . Used by instrument clusters, tachographs,";
CM_ SG_ 2566755838 TransOilLifeRemaining "Signal which indicates the actual oil life remaining in percent. 100% means the transmission oil is brand new, and 0%";
CM_ SG_ 2566755838 TrnsTorqueConverterOilOutletTemp "Temperature of transmission torque converter outlet oil.";
CM_ SG_ 2566755838 TransOverheatIndicator "Signal from transmission indicating that its fluid temperature is above normal acceptable limits, and as a result,";
CM_ SG_ 2566755838 TransOilLevelSwitch "This switch indicates whether transmission oil level is full or empty.";
CM_ SG_ 2566755838 TransOilFilterRestrictionSwitch "This switch indicates whether the transmission oil filter is clogged.";
CM_ BO_ 2566752766 "Vehicle Direction/Speed 2";
CM_ SG_ 2566752766 VehicleRoll "This parameter indicates the roll in degrees from level. Facing the direction of travel a tip to the left would be indicated by";
CM_ SG_ 2633938942 TotalEngCruiseTime "Total time that the engine has operated in the cruise hold state, excluding time in accelerator override, over the life of the";
CM_ SG_ 2633938942 TotalDriveAverageLoadFactor "Average engine load factor while engine speed is greater than zero, vehicle speed is greater than or equal to 2 km/h, and";
CM_ SG_ 2633938942 TripDriveAverageLoadFactor "Average engine load factor while engine speed is greater than zero, vehicle speed is greater than or equal to 2 km/h, and";
CM_ SG_ 2633938942 TripAverageEngSpeed "Average speed of the engine since the last trip reset.";
CM_ SG_ 2633938942 TripMaxEngSpeed "Maximum engine speed achieved since the last trip reset.";
CM_ BO_ 2566799614 "This lighting message is a response to the request for lighting data in the lighting command message. Each lighting";
CM_ SG_ 2566799614 ImplementRearWorkLight "This parameter provides measured data from the implement rear work lamps.";
CM_ SG_ 2566799614 ImplementLeftForwardWorkLight "This parameter provides measured data from the forward facing work lights toward the left end of the implement.";
CM_ SG_ 2566799614 ImplementRightForwardWorkLight "This parameter provides measured data from the forward facing work lights toward the right end of the implement.";
CM_ SG_ 2566799614 ImplementLeftFacingWorkLight "This parameter provides measured data from the work lights mounted on an implement to illuminate beyond left end of";
CM_ SG_ 2566799614 ImplementRightFacingWorkLight "This parameter provides measured data from the work lights mounted on an implement to illuminate beyond right end of";
CM_ SG_ 2566799614 ImplementOEMOption1Light "This parameter provides measured data from the implement OEM option 1 light.";
CM_ SG_ 2566799614 ImplementOEMOption2Light "This parameter provides measured data from the implement OEM option 2 light.";
CM_ SG_ 2566799614 TrctorFrontHighMountedWorkLights "This parameter provides measured data from the tractor front high mounted work lights.";
CM_ SG_ 2566799614 TractorFrontLowMountedWorkLights "This parameter provides measured data from the tractor front low mounted work lights.";
CM_ SG_ 2566799614 TractorSideHighMountedWorkLights "This parameter provides measured data from the tractor side high mounted work lights.";
CM_ SG_ 2566799614 TractorSideLowMountedWorkLights "This parameter provides measured data from the tractor side low mounted work lights.";
CM_ SG_ 2566799614 TractorRearHighMountedWorkLights "This parameter provides measured data from the tractor rear high mounted work lights.";
CM_ SG_ 2566799614 TractorRearLowMountedWorkLights "This parameter provides measured data from the tractor rear low mounted work lights.";
CM_ SG_ 2566799614 TrctorUndersideMountedWorkLights "This parameter provides measured data from the tractor underside mounted work lights.";
CM_ SG_ 2566799614 RearFogLights "This parameter provides measured data from the tractor and/or implement rear fog lights.";
CM_ SG_ 2566799614 TractorMarkerLight "This parameter provides measured data from the tractor and attached implement marker lights, including front position";
CM_ SG_ 2566799614 ImplementMarkerLight "This parameter provides measured data from an attached implement marker lights, including front position lights, rear tail";
CM_ SG_ 2566799614 TractorClearanceLight "This parameter provides measured data from the tractor high mounted clearance and center ID lights.";
CM_ SG_ 2566799614 ImplementClearanceLight "This parameter provides measured data from an attached implement high mounted clearance lights.";
CM_ SG_ 2566799614 LeftStopLight "This parameter provides measured data from the tractor and attached implement left stop lights.";
CM_ SG_ 2566799614 RightStopLight "This parameter provides measured data from the tractor and attached implement right stop lights.";
CM_ SG_ 2566799614 CenterStopLight "This parameter provides measured data from the tractor and attached implement center stop lights.";
CM_ SG_ 2566799614 BackUpLightAndAlarmHorn "This parameter provides measured data from the back up lights and/ or associated alarm.";
CM_ SG_ 2566799614 LeftTurnSignalLights "This parameter provides measured data from the tractor and attached implement left turn signal lights.";
CM_ SG_ 2566799614 RightTurnSignalLights "This parameter provides measured data from the tractor and attached implement right turn signal lights.";
CM_ SG_ 2566799614 RotatingBeaconLight "This parameter provides measured data from the beacon light on tractor or attached implements.";
CM_ SG_ 2566799614 TractorFrontFogLights "This parameter provides measured data from the tractor front fog lights.";
CM_ SG_ 2566799614 HighBeamHeadLightData "This parameter provides measured data from the tractor high beam head light lamps.";
CM_ SG_ 2566799614 LowBeamHeadLightData "This parameter provides measured data from the tractor low beam head light lamps.";
CM_ SG_ 2566799614 AltBeamHeadLightData "This parameter provides measured data from the tractor alternate beam head light lamps.";
CM_ SG_ 2566799614 RunningLight "This parameter provides measured data from the vehicle’s running lights.";
BA_DEF_ BO_  "GenMsgCycleTimeFast" INT 0 3600000;
BA_DEF_ SG_  "SigType" ENUM  "Default","Range","RangeSigned","ASCII","Discrete","Control","ReferencePGN","DTC","StringDelimiter","StringLength","StringLengthControl";
BA_DEF_ SG_  "GenSigStartValue" INT 0 10000;
BA_DEF_ SG_  "GenSigSendType" ENUM  "Cyclic","OnWrite","reserved","OnChange","reserved","reserved","reserved","NoSigSendType";
BA_DEF_ SG_  "GenSigILSupport" ENUM  "Yes","No";
BA_DEF_ SG_  "GenSigEVName" STRING ;
BA_DEF_ SG_  "SPN" INT 0 524287;
BA_DEF_ SG_  "DDI" INT 0 65535;
BA_DEF_ SG_  "SAEDocument" STRING ;
BA_DEF_ BO_  "GenMsgStartDelayTime" INT 0 100000;
BA_DEF_ BO_  "GenMsgILSupport" ENUM  "Yes","No";
BA_DEF_ BO_  "GenMsgRequestable" INT 0 1;
BA_DEF_ BO_  "GenMsgSendType" ENUM  "cyclic","reserved","cyclicIfActive","reserved","reserved","reserved","reserved","reserved","noMsgSendType";
BA_DEF_ BO_  "VFrameFormat" ENUM  "StandardCAN","ExtendedCAN","reserved","J1939PG";
BA_DEF_ BO_  "SingleFrame" INT 0 1;
BA_DEF_ BO_  "GenMsgCycleTime" INT 0 3600000;
BA_DEF_ BO_  "SAE_Document" STRING ;
BA_DEF_ SG_  "SystemSignalLongSymbol" STRING ;
BA_DEF_DEF_  "GenMsgCycleTimeFast" 0;
BA_DEF_DEF_  "SigType" "Default";
BA_DEF_DEF_  "GenSigStartValue" 0;
BA_DEF_DEF_  "GenSigSendType" "NoSigSendType";
BA_DEF_DEF_  "GenSigILSupport" "Yes";
BA_DEF_DEF_  "GenSigEVName" "Env@Nodename_@Signame";
BA_DEF_DEF_  "SPN" 0;
BA_DEF_DEF_  "DDI" 0;
BA_DEF_DEF_  "SAEDocument" "";
BA_DEF_DEF_  "GenMsgStartDelayTime" 0;
BA_DEF_DEF_  "GenMsgILSupport" "Yes";
BA_DEF_DEF_  "GenMsgRequestable" 1;
BA_DEF_DEF_  "GenMsgSendType" "noMsgSendType";
BA_DEF_DEF_  "VFrameFormat" "J1939PG";
BA_DEF_DEF_  "SingleFrame" 1;
BA_DEF_DEF_  "GenMsgCycleTime" 0;
BA_DEF_DEF_  "SAE_Document" "";
BA_DEF_DEF_  "SystemSignalLongSymbol" "";
BA_ "GenMsgSendType" BO_ 2566714110 0;
BA_ "GenMsgCycleTime" BO_ 2566714110 100;
BA_ "SAE_Document" BO_ 2566714110 "J1939-71";
BA_ "GenMsgSendType" BO_ 2566717438 0;
BA_ "GenMsgCycleTime" BO_ 2566717438 1000;
BA_ "SAE_Document" BO_ 2566717438 "J1939-71";
BA_ "GenMsgSendType" BO_ 2633828606 0;
BA_ "GenMsgCycleTime" BO_ 2633828606 30000;
BA_ "SAE_Document" BO_ 2633828606 "J1939-71";
BA_ "SAE_Document" BO_ 2499607550 "J1939-71";
BA_ "SAE_Document" BO_ 2633825534 "J1939-71";
BA_ "SAE_Document" BO_ 2365400574 "J1939-71";
BA_ "SAE_Document" BO_ 2365401086 "J1939-71";
BA_ "SAE_Document" BO_ 2365401598 "J1939-71";
BA_ "SAE_Document" BO_ 2365402110 "J1939-71";
BA_ "SAE_Document" BO_ 2365402622 "J1939-71";
BA_ "SAE_Document" BO_ 2365403134 "J1939-71";
BA_ "SAE_Document" BO_ 2365400062 "J1939-71";
BA_ "GenMsgSendType" BO_ 2566713598 0;
BA_ "GenMsgCycleTime" BO_ 2566713598 500;
BA_ "SAE_Document" BO_ 2566713598 "J1939-71";
BA_ "GenMsgSendType" BO_ 2499604478 0;
BA_ "GenMsgCycleTime" BO_ 2499604478 500;
BA_ "SAE_Document" BO_ 2499604478 "J1939-71";
BA_ "GenMsgSendType" BO_ 2499608830 0;
BA_ "GenMsgCycleTime" BO_ 2499608830 500;
BA_ "SAE_Document" BO_ 2499608830 "J1939-71";
BA_ "GenMsgSendType" BO_ 2432499198 0;
BA_ "GenMsgCycleTime" BO_ 2432499198 100;
BA_ "SAE_Document" BO_ 2432499198 "J1939-71";
BA_ "SAE_Document" BO_ 2633825022 "J1939-71";
BA_ "SAE_Document" BO_ 2633826046 "J1939-71";
BA_ "GenMsgSendType" BO_ 2566711294 0;
BA_ "GenMsgCycleTime" BO_ 2566711294 5000;
BA_ "SAE_Document" BO_ 2566711294 "J1939-71";
BA_ "SAE_Document" BO_ 2566749438 "J1939-71";
BA_ "GenMsgSendType" BO_ 2566715646 0;
BA_ "GenMsgCycleTime" BO_ 2566715646 1000;
BA_ "SAE_Document" BO_ 2566715646 "J1939-71";
BA_ "GenMsgSendType" BO_ 2566724606 0;
BA_ "GenMsgCycleTime" BO_ 2566724606 1000;
BA_ "SAE_Document" BO_ 2566724606 "J1939-71";
BA_ "GenMsgSendType" BO_ 2566715902 0;
BA_ "GenMsgCycleTime" BO_ 2566715902 1000;
BA_ "SAE_Document" BO_ 2566715902 "J1939-71";
BA_ "GenMsgSendType" BO_ 2566724862 0;
BA_ "GenMsgCycleTime" BO_ 2566724862 1000;
BA_ "SAE_Document" BO_ 2566724862 "J1939-71";
BA_ "GenMsgSendType" BO_ 2566718718 0;
BA_ "GenMsgCycleTime" BO_ 2566718718 1000;
BA_ "SAE_Document" BO_ 2566718718 "J1939-71";
BA_ "GenMsgSendType" BO_ 2566718974 0;
BA_ "GenMsgCycleTime" BO_ 2566718974 1000;
BA_ "SAE_Document" BO_ 2566718974 "J1939-71";
BA_ "GenMsgSendType" BO_ 2566719230 0;
BA_ "GenMsgCycleTime" BO_ 2566719230 1000;
BA_ "SAE_Document" BO_ 2566719230 "J1939-71";
BA_ "SAE_Document" BO_ 2560818942 "J1939_73";
BA_ "SAE_Document" BO_ 2561212158 "J1939-71";
BA_ "GenMsgCycleTime" BO_ 2566746366 1000;
BA_ "SAE_Document" BO_ 2566746366 "J1939-71";
BA_ "SAE_Document" BO_ 2566750206 "J1939-71";
BA_ "GenMsgSendType" BO_ 2566755582 0;
BA_ "GenMsgCycleTime" BO_ 2566755582 100;
BA_ "SAE_Document" BO_ 2566755582 "J1939-71";
BA_ "SAE_Document" BO_ 2566746110 "J1939-71";
BA_ "GenMsgSendType" BO_ 2566752510 0;
BA_ "GenMsgCycleTime" BO_ 2566752510 500;
BA_ "SAE_Document" BO_ 2566752510 "J1939-71";
BA_ "GenMsgSendType" BO_ 2566752254 0;
BA_ "GenMsgCycleTime" BO_ 2566752254 500;
BA_ "SAE_Document" BO_ 2566752254 "J1939-71";
BA_ "GenMsgSendType" BO_ 2566751998 0;
BA_ "GenMsgCycleTime" BO_ 2566751998 500;
BA_ "SAE_Document" BO_ 2566751998 "J1939-71";
BA_ "GenMsgSendType" BO_ 2566751742 0;
BA_ "GenMsgCycleTime" BO_ 2566751742 500;
BA_ "SAE_Document" BO_ 2566751742 "J1939-71";
BA_ "GenMsgSendType" BO_ 2566751486 0;
BA_ "GenMsgCycleTime" BO_ 2566751486 500;
BA_ "SAE_Document" BO_ 2566751486 "J1939-71";
BA_ "GenMsgSendType" BO_ 2499641854 0;
BA_ "GenMsgCycleTime" BO_ 2499641854 500;
BA_ "SAE_Document" BO_ 2499641854 "J1939-71";
BA_ "SAE_Document" BO_ 2566748158 "J1939-71";
BA_ "SAE_Document" BO_ 2566747902 "J1939-71";
BA_ "SAE_Document" BO_ 2566747646 "J1939-71";
BA_ "SAE_Document" BO_ 2566747390 "J1939-71";
BA_ "SAE_Document" BO_ 2566747134 "J1939-71";
BA_ "SAE_Document" BO_ 2566746878 "J1939-71";
BA_ "SAE_Document" BO_ 2561277694 "J1939-71";
BA_ "SAE_Document" BO_ 2633861886 "J1939-71";
BA_ "GenMsgSendType" BO_ 2565873150 0;
BA_ "GenMsgCycleTime" BO_ 2565873150 10;
BA_ "SAE_Document" BO_ 2565873150 "J1939-71";
BA_ "SAE_Document" BO_ 2566745854 "J1939-71";
BA_ "GenMsgSendType" BO_ 2566751230 0;
BA_ "GenMsgCycleTime" BO_ 2566751230 1000;
BA_ "SAE_Document" BO_ 2566751230 "J1939-71";
BA_ "GenMsgSendType" BO_ 2566755838 0;
BA_ "GenMsgCycleTime" BO_ 2566755838 1000;
BA_ "SAE_Document" BO_ 2566755838 "J1939-71";
BA_ "SAE_Document" BO_ 2566752766 "J1939-71";
BA_ "SAE_Document" BO_ 2633938942 "J1939-71";
BA_ "SAE_Document" BO_ 2566799614 "J1939-71";
BA_ "SPN" SG_ 2566714110 EngFuelValve2OperationStatus 5448;
BA_ "SAEDocument" SG_ 2566714110 EngFuelValve2OperationStatus "J1939-71";
BA_ "SPN" SG_ 2566714110 EngFuelValve1OperationStatus 5447;
BA_ "SAEDocument" SG_ 2566714110 EngFuelValve1OperationStatus "J1939-71";
BA_ "SPN" SG_ 2566714110 EngThrottleValve2OperationStatus 5446;
BA_ "SAEDocument" SG_ 2566714110 EngThrottleValve2OperationStatus "J1939-71";
BA_ "SPN" SG_ 2566714110 EngThrottleValve1OperationStatus 5445;
BA_ "SAEDocument" SG_ 2566714110 EngThrottleValve1OperationStatus "J1939-71";
BA_ "SPN" SG_ 2566714110 EngFuelValve2TempStatus 5383;
BA_ "SAEDocument" SG_ 2566714110 EngFuelValve2TempStatus "J1939-71";
BA_ "SPN" SG_ 2566714110 EngFuelValve2PreliminaryFMI 5382;
BA_ "SAEDocument" SG_ 2566714110 EngFuelValve2PreliminaryFMI "J1939-71";
BA_ "SPN" SG_ 2566714110 EngFuelValve1TempStatus 5381;
BA_ "SAEDocument" SG_ 2566714110 EngFuelValve1TempStatus "J1939-71";
BA_ "SPN" SG_ 2566714110 EngFuelValve1PreliminaryFMI 5380;
BA_ "SAEDocument" SG_ 2566714110 EngFuelValve1PreliminaryFMI "J1939-71";
BA_ "SPN" SG_ 2566714110 EngThrottleValve2TempStatus 5379;
BA_ "SAEDocument" SG_ 2566714110 EngThrottleValve2TempStatus "J1939-71";
BA_ "SPN" SG_ 2566714110 EngThrottleValve2PreliminaryFMI 5378;
BA_ "SAEDocument" SG_ 2566714110 EngThrottleValve2PreliminaryFMI "J1939-71";
BA_ "SPN" SG_ 2566714110 EngDesiredThrottleValve2Pos 5377;
BA_ "SAEDocument" SG_ 2566714110 EngDesiredThrottleValve2Pos "J1939-71";
BA_ "SPN" SG_ 2566714110 EngThrottleValve1TempStatus 5376;
BA_ "SAEDocument" SG_ 2566714110 EngThrottleValve1TempStatus "J1939-71";
BA_ "SPN" SG_ 2566714110 EngThrottleValve1PreliminaryFMI 5375;
BA_ "SAEDocument" SG_ 2566714110 EngThrottleValve1PreliminaryFMI "J1939-71";
BA_ "SPN" SG_ 2566714110 EngDesiredThrottleValve1Pos 5374;
BA_ "SAEDocument" SG_ 2566714110 EngDesiredThrottleValve1Pos "J1939-71";
BA_ "SigType" SG_ 2566717438 EngExhstGsRcrcltn2MxerIntakeTemp 1;
BA_ "SPN" SG_ 2566717438 EngExhstGsRcrcltn2MxerIntakeTemp 5256;
BA_ "SAEDocument" SG_ 2566717438 EngExhstGsRcrcltn2MxerIntakeTemp "J1939-71";
BA_ "SigType" SG_ 2566717438 EngExhaustGasRecirculation2Temp 1;
BA_ "SPN" SG_ 2566717438 EngExhaustGasRecirculation2Temp 5255;
BA_ "SAEDocument" SG_ 2566717438 EngExhaustGasRecirculation2Temp "J1939-71";
BA_ "SigType" SG_ 2633828606 EngOilRelativeDielectricity 1;
BA_ "SPN" SG_ 2633828606 EngOilRelativeDielectricity 5468;
BA_ "SAEDocument" SG_ 2633828606 EngOilRelativeDielectricity "J1939-71";
BA_ "SigType" SG_ 2633828606 EngOilDensity 1;
BA_ "SPN" SG_ 2633828606 EngOilDensity 5056;
BA_ "SAEDocument" SG_ 2633828606 EngOilDensity "J1939-71";
BA_ "SigType" SG_ 2633828606 EngOilViscosity 1;
BA_ "SPN" SG_ 2633828606 EngOilViscosity 5055;
BA_ "SAEDocument" SG_ 2633828606 EngOilViscosity "J1939-71";
BA_ "SigType" SG_ 2499607550 EngExhstMnfldBnk2FlwBlncVlvActtr 1;
BA_ "SPN" SG_ 2499607550 EngExhstMnfldBnk2FlwBlncVlvActtr 5279;
BA_ "SAEDocument" SG_ 2499607550 EngExhstMnfldBnk2FlwBlncVlvActtr "J1939-71";
BA_ "SigType" SG_ 2499607550 EngExhstMnfldBnk1FlwBlncVlvActtr 1;
BA_ "SPN" SG_ 2499607550 EngExhstMnfldBnk1FlwBlncVlvActtr 5277;
BA_ "SAEDocument" SG_ 2499607550 EngExhstMnfldBnk1FlwBlncVlvActtr "J1939-71";
BA_ "SPN" SG_ 2633825534 EngExhstMnfldBnk2FlwBlncVlvActtr 5278;
BA_ "SAEDocument" SG_ 2633825534 EngExhstMnfldBnk2FlwBlncVlvActtr "J1939-71";
BA_ "SPN" SG_ 2633825534 EngExhstMnfldBnk1FlwBlncVlvActtr 5276;
BA_ "SAEDocument" SG_ 2633825534 EngExhstMnfldBnk1FlwBlncVlvActtr "J1939-71";
BA_ "SigType" SG_ 2365400574 Jystick9GripXAxisDetentPosStatus 4;
BA_ "SPN" SG_ 2365400574 Jystick9GripXAxisDetentPosStatus 4712;
BA_ "SAEDocument" SG_ 2365400574 Jystick9GripXAxisDetentPosStatus "J1939-71";
BA_ "SigType" SG_ 2365400574 Jystick9GripYAxisDetentPosStatus 4;
BA_ "SPN" SG_ 2365400574 Jystick9GripYAxisDetentPosStatus 4711;
BA_ "SAEDocument" SG_ 2365400574 Jystick9GripYAxisDetentPosStatus "J1939-71";
BA_ "SigType" SG_ 2365400574 Jystick9ThetaAxisDetentPosStatus 4;
BA_ "SPN" SG_ 2365400574 Jystick9ThetaAxisDetentPosStatus 4710;
BA_ "SAEDocument" SG_ 2365400574 Jystick9ThetaAxisDetentPosStatus "J1939-71";
BA_ "SPN" SG_ 2365400574 Joystick9ThetaAxisPos 4709;
BA_ "SAEDocument" SG_ 2365400574 Joystick9ThetaAxisPos "J1939-71";
BA_ "SigType" SG_ 2365400574 Jystck9ThtAxsClckwsPstvPosStatus 4;
BA_ "SPN" SG_ 2365400574 Jystck9ThtAxsClckwsPstvPosStatus 4708;
BA_ "SAEDocument" SG_ 2365400574 Jystck9ThtAxsClckwsPstvPosStatus "J1939-71";
BA_ "SigType" SG_ 2365400574 Jystck9ThtAxsCntrClckwsNgtvPsStt 4;
BA_ "SPN" SG_ 2365400574 Jystck9ThtAxsCntrClckwsNgtvPsStt 4707;
BA_ "SAEDocument" SG_ 2365400574 Jystck9ThtAxsCntrClckwsNgtvPsStt "J1939-71";
BA_ "SigType" SG_ 2365400574 Jystck9ThetaAxisNeutralPosStatus 4;
BA_ "SPN" SG_ 2365400574 Jystck9ThetaAxisNeutralPosStatus 4706;
BA_ "SAEDocument" SG_ 2365400574 Jystck9ThetaAxisNeutralPosStatus "J1939-71";
BA_ "SPN" SG_ 2365400574 Joystick9GripYAxisPos 4705;
BA_ "SAEDocument" SG_ 2365400574 Joystick9GripYAxisPos "J1939-71";
BA_ "SigType" SG_ 2365400574 Jystck9GrpYAxsLvrFrwrdPstvPsStts 4;
BA_ "SPN" SG_ 2365400574 Jystck9GrpYAxsLvrFrwrdPstvPsStts 4704;
BA_ "SAEDocument" SG_ 2365400574 Jystck9GrpYAxsLvrFrwrdPstvPsStts "J1939-71";
BA_ "SigType" SG_ 2365400574 Jystck9GrpYAxsLvrBckNgtvPsStatus 4;
BA_ "SPN" SG_ 2365400574 Jystck9GrpYAxsLvrBckNgtvPsStatus 4703;
BA_ "SAEDocument" SG_ 2365400574 Jystck9GrpYAxsLvrBckNgtvPsStatus "J1939-71";
BA_ "SigType" SG_ 2365400574 Jystck9GripYAxisNeutralPosStatus 4;
BA_ "SPN" SG_ 2365400574 Jystck9GripYAxisNeutralPosStatus 4702;
BA_ "SAEDocument" SG_ 2365400574 Jystck9GripYAxisNeutralPosStatus "J1939-71";
BA_ "SPN" SG_ 2365400574 Joystick9GripXAxisPos 4701;
BA_ "SAEDocument" SG_ 2365400574 Joystick9GripXAxisPos "J1939-71";
BA_ "SigType" SG_ 2365400574 Jystck9GrpXAxsLvrRghtPstvPsSttus 4;
BA_ "SPN" SG_ 2365400574 Jystck9GrpXAxsLvrRghtPstvPsSttus 4700;
BA_ "SAEDocument" SG_ 2365400574 Jystck9GrpXAxsLvrRghtPstvPsSttus "J1939-71";
BA_ "SigType" SG_ 2365400574 Jystck9GrpXAxsLvrLftNgtvPsStatus 4;
BA_ "SPN" SG_ 2365400574 Jystck9GrpXAxsLvrLftNgtvPsStatus 4699;
BA_ "SAEDocument" SG_ 2365400574 Jystck9GrpXAxsLvrLftNgtvPsStatus "J1939-71";
BA_ "SigType" SG_ 2365400574 Jystck9GripXAxisNeutralPosStatus 4;
BA_ "SPN" SG_ 2365400574 Jystck9GripXAxisNeutralPosStatus 4698;
BA_ "SAEDocument" SG_ 2365400574 Jystck9GripXAxisNeutralPosStatus "J1939-71";
BA_ "SigType" SG_ 2365401086 Jystick8GripXAxisDetentPosStatus 4;
BA_ "SPN" SG_ 2365401086 Jystick8GripXAxisDetentPosStatus 4675;
BA_ "SAEDocument" SG_ 2365401086 Jystick8GripXAxisDetentPosStatus "J1939-71";
BA_ "SigType" SG_ 2365401086 Jystick8GripYAxisDetentPosStatus 4;
BA_ "SPN" SG_ 2365401086 Jystick8GripYAxisDetentPosStatus 4674;
BA_ "SAEDocument" SG_ 2365401086 Jystick8GripYAxisDetentPosStatus "J1939-71";
BA_ "SigType" SG_ 2365401086 Jystick8ThetaAxisDetentPosStatus 4;
BA_ "SPN" SG_ 2365401086 Jystick8ThetaAxisDetentPosStatus 4673;
BA_ "SAEDocument" SG_ 2365401086 Jystick8ThetaAxisDetentPosStatus "J1939-71";
BA_ "SPN" SG_ 2365401086 Joystick8ThetaAxisPos 4672;
BA_ "SAEDocument" SG_ 2365401086 Joystick8ThetaAxisPos "J1939-71";
BA_ "SigType" SG_ 2365401086 Jystck8ThtAxsClckwsPstvPosStatus 4;
BA_ "SPN" SG_ 2365401086 Jystck8ThtAxsClckwsPstvPosStatus 4671;
BA_ "SAEDocument" SG_ 2365401086 Jystck8ThtAxsClckwsPstvPosStatus "J1939-71";
BA_ "SigType" SG_ 2365401086 Jystck8ThtAxsCntrClckwsNgtvPsStt 4;
BA_ "SPN" SG_ 2365401086 Jystck8ThtAxsCntrClckwsNgtvPsStt 4670;
BA_ "SAEDocument" SG_ 2365401086 Jystck8ThtAxsCntrClckwsNgtvPsStt "J1939-71";
BA_ "SigType" SG_ 2365401086 Jystck8ThetaAxisNeutralPosStatus 4;
BA_ "SPN" SG_ 2365401086 Jystck8ThetaAxisNeutralPosStatus 4669;
BA_ "SAEDocument" SG_ 2365401086 Jystck8ThetaAxisNeutralPosStatus "J1939-71";
BA_ "SPN" SG_ 2365401086 Joystick8GripYAxisPos 4668;
BA_ "SAEDocument" SG_ 2365401086 Joystick8GripYAxisPos "J1939-71";
BA_ "SigType" SG_ 2365401086 Jystck8GrpYAxsLvrFrwrdPstvPsStts 4;
BA_ "SPN" SG_ 2365401086 Jystck8GrpYAxsLvrFrwrdPstvPsStts 4667;
BA_ "SAEDocument" SG_ 2365401086 Jystck8GrpYAxsLvrFrwrdPstvPsStts "J1939-71";
BA_ "SigType" SG_ 2365401086 Jystck8GrpYAxsLvrBckNgtvPsStatus 4;
BA_ "SPN" SG_ 2365401086 Jystck8GrpYAxsLvrBckNgtvPsStatus 4666;
BA_ "SAEDocument" SG_ 2365401086 Jystck8GrpYAxsLvrBckNgtvPsStatus "J1939-71";
BA_ "SigType" SG_ 2365401086 Jystck8GripYAxisNeutralPosStatus 4;
BA_ "SPN" SG_ 2365401086 Jystck8GripYAxisNeutralPosStatus 4665;
BA_ "SAEDocument" SG_ 2365401086 Jystck8GripYAxisNeutralPosStatus "J1939-71";
BA_ "SPN" SG_ 2365401086 Joystick8GripXAxisPos 4664;
BA_ "SAEDocument" SG_ 2365401086 Joystick8GripXAxisPos "J1939-71";
BA_ "SigType" SG_ 2365401086 Jystck8GrpXAxsLvrRghtPstvPsSttus 4;
BA_ "SPN" SG_ 2365401086 Jystck8GrpXAxsLvrRghtPstvPsSttus 4663;
BA_ "SAEDocument" SG_ 2365401086 Jystck8GrpXAxsLvrRghtPstvPsSttus "J1939-71";
BA_ "SigType" SG_ 2365401086 Jystck8GrpXAxsLvrLftNgtvPsStatus 4;
BA_ "SPN" SG_ 2365401086 Jystck8GrpXAxsLvrLftNgtvPsStatus 4662;
BA_ "SAEDocument" SG_ 2365401086 Jystck8GrpXAxsLvrLftNgtvPsStatus "J1939-71";
BA_ "SigType" SG_ 2365401086 Jystck8GripXAxisNeutralPosStatus 4;
BA_ "SPN" SG_ 2365401086 Jystck8GripXAxisNeutralPosStatus 4661;
BA_ "SAEDocument" SG_ 2365401086 Jystck8GripXAxisNeutralPosStatus "J1939-71";
BA_ "SigType" SG_ 2365401598 Jystick7GripXAxisDetentPosStatus 4;
BA_ "SPN" SG_ 2365401598 Jystick7GripXAxisDetentPosStatus 4638;
BA_ "SAEDocument" SG_ 2365401598 Jystick7GripXAxisDetentPosStatus "J1939-71";
BA_ "SigType" SG_ 2365401598 Jystick7GripYAxisDetentPosStatus 4;
BA_ "SPN" SG_ 2365401598 Jystick7GripYAxisDetentPosStatus 4637;
BA_ "SAEDocument" SG_ 2365401598 Jystick7GripYAxisDetentPosStatus "J1939-71";
BA_ "SigType" SG_ 2365401598 Jystick7ThetaAxisDetentPosStatus 4;
BA_ "SPN" SG_ 2365401598 Jystick7ThetaAxisDetentPosStatus 4636;
BA_ "SAEDocument" SG_ 2365401598 Jystick7ThetaAxisDetentPosStatus "J1939-71";
BA_ "SPN" SG_ 2365401598 Joystick7ThetaAxisPos 4635;
BA_ "SAEDocument" SG_ 2365401598 Joystick7ThetaAxisPos "J1939-71";
BA_ "SigType" SG_ 2365401598 Jystck7ThtAxsClckwsPstvPosStatus 4;
BA_ "SPN" SG_ 2365401598 Jystck7ThtAxsClckwsPstvPosStatus 4634;
BA_ "SAEDocument" SG_ 2365401598 Jystck7ThtAxsClckwsPstvPosStatus "J1939-71";
BA_ "SigType" SG_ 2365401598 Jystck7ThtAxsCntrClckwsNgtvPsStt 4;
BA_ "SPN" SG_ 2365401598 Jystck7ThtAxsCntrClckwsNgtvPsStt 4633;
BA_ "SAEDocument" SG_ 2365401598 Jystck7ThtAxsCntrClckwsNgtvPsStt "J1939-71";
BA_ "SigType" SG_ 2365401598 Jystck7ThetaAxisNeutralPosStatus 4;
BA_ "SPN" SG_ 2365401598 Jystck7ThetaAxisNeutralPosStatus 4632;
BA_ "SAEDocument" SG_ 2365401598 Jystck7ThetaAxisNeutralPosStatus "J1939-71";
BA_ "SPN" SG_ 2365401598 Joystick7GripYAxisPos 4631;
BA_ "SAEDocument" SG_ 2365401598 Joystick7GripYAxisPos "J1939-71";
BA_ "SigType" SG_ 2365401598 Jystck7GrpYAxsLvrFrwrdPstvPsStts 4;
BA_ "SPN" SG_ 2365401598 Jystck7GrpYAxsLvrFrwrdPstvPsStts 4630;
BA_ "SAEDocument" SG_ 2365401598 Jystck7GrpYAxsLvrFrwrdPstvPsStts "J1939-71";
BA_ "SigType" SG_ 2365401598 Jystck7GrpYAxsLvrBckNgtvPsStatus 4;
BA_ "SPN" SG_ 2365401598 Jystck7GrpYAxsLvrBckNgtvPsStatus 4629;
BA_ "SAEDocument" SG_ 2365401598 Jystck7GrpYAxsLvrBckNgtvPsStatus "J1939-71";
BA_ "SigType" SG_ 2365401598 Jystck7GripYAxisNeutralPosStatus 4;
BA_ "SPN" SG_ 2365401598 Jystck7GripYAxisNeutralPosStatus 4628;
BA_ "SAEDocument" SG_ 2365401598 Jystck7GripYAxisNeutralPosStatus "J1939-71";
BA_ "SPN" SG_ 2365401598 Joystick7GripXAxisPos 4627;
BA_ "SAEDocument" SG_ 2365401598 Joystick7GripXAxisPos "J1939-71";
BA_ "SigType" SG_ 2365401598 Jystck7GrpXAxsLvrRghtPstvPsSttus 4;
BA_ "SPN" SG_ 2365401598 Jystck7GrpXAxsLvrRghtPstvPsSttus 4626;
BA_ "SAEDocument" SG_ 2365401598 Jystck7GrpXAxsLvrRghtPstvPsSttus "J1939-71";
BA_ "SigType" SG_ 2365401598 Jystck7GrpXAxsLvrLftNgtvPsStatus 4;
BA_ "SPN" SG_ 2365401598 Jystck7GrpXAxsLvrLftNgtvPsStatus 4625;
BA_ "SAEDocument" SG_ 2365401598 Jystck7GrpXAxsLvrLftNgtvPsStatus "J1939-71";
BA_ "SigType" SG_ 2365401598 Jystck7GripXAxisNeutralPosStatus 4;
BA_ "SPN" SG_ 2365401598 Jystck7GripXAxisNeutralPosStatus 4624;
BA_ "SAEDocument" SG_ 2365401598 Jystck7GripXAxisNeutralPosStatus "J1939-71";
BA_ "SigType" SG_ 2365402110 Jystick6GripXAxisDetentPosStatus 4;
BA_ "SPN" SG_ 2365402110 Jystick6GripXAxisDetentPosStatus 4601;
BA_ "SAEDocument" SG_ 2365402110 Jystick6GripXAxisDetentPosStatus "J1939-71";
BA_ "SigType" SG_ 2365402110 Jystick6GripYAxisDetentPosStatus 4;
BA_ "SPN" SG_ 2365402110 Jystick6GripYAxisDetentPosStatus 4600;
BA_ "SAEDocument" SG_ 2365402110 Jystick6GripYAxisDetentPosStatus "J1939-71";
BA_ "SigType" SG_ 2365402110 Jystick6ThetaAxisDetentPosStatus 4;
BA_ "SPN" SG_ 2365402110 Jystick6ThetaAxisDetentPosStatus 4599;
BA_ "SAEDocument" SG_ 2365402110 Jystick6ThetaAxisDetentPosStatus "J1939-71";
BA_ "SPN" SG_ 2365402110 Joystick6ThetaAxisPos 4598;
BA_ "SAEDocument" SG_ 2365402110 Joystick6ThetaAxisPos "J1939-71";
BA_ "SigType" SG_ 2365402110 Jystck6ThtAxsClckwsPstvPosStatus 4;
BA_ "SPN" SG_ 2365402110 Jystck6ThtAxsClckwsPstvPosStatus 4597;
BA_ "SAEDocument" SG_ 2365402110 Jystck6ThtAxsClckwsPstvPosStatus "J1939-71";
BA_ "SigType" SG_ 2365402110 Jystck6ThtAxsCntrClckwsNgtvPsStt 4;
BA_ "SPN" SG_ 2365402110 Jystck6ThtAxsCntrClckwsNgtvPsStt 4596;
BA_ "SAEDocument" SG_ 2365402110 Jystck6ThtAxsCntrClckwsNgtvPsStt "J1939-71";
BA_ "SigType" SG_ 2365402110 Jystck6ThetaAxisNeutralPosStatus 4;
BA_ "SPN" SG_ 2365402110 Jystck6ThetaAxisNeutralPosStatus 4595;
BA_ "SAEDocument" SG_ 2365402110 Jystck6ThetaAxisNeutralPosStatus "J1939-71";
BA_ "SPN" SG_ 2365402110 Joystick6GripYAxisPos 4594;
BA_ "SAEDocument" SG_ 2365402110 Joystick6GripYAxisPos "J1939-71";
BA_ "SigType" SG_ 2365402110 Jystck6GrpYAxsLvrFrwrdPstvPsStts 4;
BA_ "SPN" SG_ 2365402110 Jystck6GrpYAxsLvrFrwrdPstvPsStts 4593;
BA_ "SAEDocument" SG_ 2365402110 Jystck6GrpYAxsLvrFrwrdPstvPsStts "J1939-71";
BA_ "SigType" SG_ 2365402110 Jystck6GrpYAxsLvrBckNgtvPsStatus 4;
BA_ "SPN" SG_ 2365402110 Jystck6GrpYAxsLvrBckNgtvPsStatus 4592;
BA_ "SAEDocument" SG_ 2365402110 Jystck6GrpYAxsLvrBckNgtvPsStatus "J1939-71";
BA_ "SigType" SG_ 2365402110 Jystck6GripYAxisNeutralPosStatus 4;
BA_ "SPN" SG_ 2365402110 Jystck6GripYAxisNeutralPosStatus 4591;
BA_ "SAEDocument" SG_ 2365402110 Jystck6GripYAxisNeutralPosStatus "J1939-71";
BA_ "SPN" SG_ 2365402110 Joystick6GripXAxisPos 4590;
BA_ "SAEDocument" SG_ 2365402110 Joystick6GripXAxisPos "J1939-71";
BA_ "SigType" SG_ 2365402110 Jystck6GrpXAxsLvrRghtPstvPsSttus 4;
BA_ "SPN" SG_ 2365402110 Jystck6GrpXAxsLvrRghtPstvPsSttus 4589;
BA_ "SAEDocument" SG_ 2365402110 Jystck6GrpXAxsLvrRghtPstvPsSttus "J1939-71";
BA_ "SigType" SG_ 2365402110 Jystck6GrpXAxsLvrLftNgtvPsStatus 4;
BA_ "SPN" SG_ 2365402110 Jystck6GrpXAxsLvrLftNgtvPsStatus 4588;
BA_ "SAEDocument" SG_ 2365402110 Jystck6GrpXAxsLvrLftNgtvPsStatus "J1939-71";
BA_ "SigType" SG_ 2365402110 Jystck6GripXAxisNeutralPosStatus 4;
BA_ "SPN" SG_ 2365402110 Jystck6GripXAxisNeutralPosStatus 4587;
BA_ "SAEDocument" SG_ 2365402110 Jystck6GripXAxisNeutralPosStatus "J1939-71";
BA_ "SigType" SG_ 2365402622 Jystick5GripXAxisDetentPosStatus 4;
BA_ "SPN" SG_ 2365402622 Jystick5GripXAxisDetentPosStatus 4564;
BA_ "SAEDocument" SG_ 2365402622 Jystick5GripXAxisDetentPosStatus "J1939-71";
BA_ "SigType" SG_ 2365402622 Jystick5GripYAxisDetentPosStatus 4;
BA_ "SPN" SG_ 2365402622 Jystick5GripYAxisDetentPosStatus 4563;
BA_ "SAEDocument" SG_ 2365402622 Jystick5GripYAxisDetentPosStatus "J1939-71";
BA_ "SigType" SG_ 2365402622 Jystick5ThetaAxisDetentPosStatus 4;
BA_ "SPN" SG_ 2365402622 Jystick5ThetaAxisDetentPosStatus 4562;
BA_ "SAEDocument" SG_ 2365402622 Jystick5ThetaAxisDetentPosStatus "J1939-71";
BA_ "SPN" SG_ 2365402622 Joystick5ThetaAxisPos 4561;
BA_ "SAEDocument" SG_ 2365402622 Joystick5ThetaAxisPos "J1939-71";
BA_ "SigType" SG_ 2365402622 Jystck5ThtAxsClckwsPstvPosStatus 4;
BA_ "SPN" SG_ 2365402622 Jystck5ThtAxsClckwsPstvPosStatus 4560;
BA_ "SAEDocument" SG_ 2365402622 Jystck5ThtAxsClckwsPstvPosStatus "J1939-71";
BA_ "SigType" SG_ 2365402622 Jystck5ThtAxsCntrClckwsNgtvPsStt 4;
BA_ "SPN" SG_ 2365402622 Jystck5ThtAxsCntrClckwsNgtvPsStt 4559;
BA_ "SAEDocument" SG_ 2365402622 Jystck5ThtAxsCntrClckwsNgtvPsStt "J1939-71";
BA_ "SigType" SG_ 2365402622 Jystck5ThetaAxisNeutralPosStatus 4;
BA_ "SPN" SG_ 2365402622 Jystck5ThetaAxisNeutralPosStatus 4558;
BA_ "SAEDocument" SG_ 2365402622 Jystck5ThetaAxisNeutralPosStatus "J1939-71";
BA_ "SPN" SG_ 2365402622 Joystick5GripYAxisPos 4557;
BA_ "SAEDocument" SG_ 2365402622 Joystick5GripYAxisPos "J1939-71";
BA_ "SigType" SG_ 2365402622 Jystck5GrpYAxsLvrFrwrdPstvPsStts 4;
BA_ "SPN" SG_ 2365402622 Jystck5GrpYAxsLvrFrwrdPstvPsStts 4556;
BA_ "SAEDocument" SG_ 2365402622 Jystck5GrpYAxsLvrFrwrdPstvPsStts "J1939-71";
BA_ "SigType" SG_ 2365402622 Jystck5GrpYAxsLvrBckNgtvPsStatus 4;
BA_ "SPN" SG_ 2365402622 Jystck5GrpYAxsLvrBckNgtvPsStatus 4555;
BA_ "SAEDocument" SG_ 2365402622 Jystck5GrpYAxsLvrBckNgtvPsStatus "J1939-71";
BA_ "SigType" SG_ 2365402622 Jystck5GripYAxisNeutralPosStatus 4;
BA_ "SPN" SG_ 2365402622 Jystck5GripYAxisNeutralPosStatus 4554;
BA_ "SAEDocument" SG_ 2365402622 Jystck5GripYAxisNeutralPosStatus "J1939-71";
BA_ "SPN" SG_ 2365402622 Joystick5GripXAxisPos 4553;
BA_ "SAEDocument" SG_ 2365402622 Joystick5GripXAxisPos "J1939-71";
BA_ "SigType" SG_ 2365402622 Jystck5GrpXAxsLvrRghtPstvPsSttus 4;
BA_ "SPN" SG_ 2365402622 Jystck5GrpXAxsLvrRghtPstvPsSttus 4552;
BA_ "SAEDocument" SG_ 2365402622 Jystck5GrpXAxsLvrRghtPstvPsSttus "J1939-71";
BA_ "SigType" SG_ 2365402622 Jystck5GrpXAxsLvrLftNgtvPsStatus 4;
BA_ "SPN" SG_ 2365402622 Jystck5GrpXAxsLvrLftNgtvPsStatus 4551;
BA_ "SAEDocument" SG_ 2365402622 Jystck5GrpXAxsLvrLftNgtvPsStatus "J1939-71";
BA_ "SigType" SG_ 2365402622 Jystck5GripXAxisNeutralPosStatus 4;
BA_ "SPN" SG_ 2365402622 Jystck5GripXAxisNeutralPosStatus 4550;
BA_ "SAEDocument" SG_ 2365402622 Jystck5GripXAxisNeutralPosStatus "J1939-71";
BA_ "SigType" SG_ 2365403134 Jystick4GripXAxisDetentPosStatus 4;
BA_ "SPN" SG_ 2365403134 Jystick4GripXAxisDetentPosStatus 4527;
BA_ "SAEDocument" SG_ 2365403134 Jystick4GripXAxisDetentPosStatus "J1939-71";
BA_ "SigType" SG_ 2365403134 Jystick4GripYAxisDetentPosStatus 4;
BA_ "SPN" SG_ 2365403134 Jystick4GripYAxisDetentPosStatus 4526;
BA_ "SAEDocument" SG_ 2365403134 Jystick4GripYAxisDetentPosStatus "J1939-71";
BA_ "SigType" SG_ 2365403134 Jystick4ThetaAxisDetentPosStatus 4;
BA_ "SPN" SG_ 2365403134 Jystick4ThetaAxisDetentPosStatus 4525;
BA_ "SAEDocument" SG_ 2365403134 Jystick4ThetaAxisDetentPosStatus "J1939-71";
BA_ "SPN" SG_ 2365403134 Joystick4ThetaAxisPos 4524;
BA_ "SAEDocument" SG_ 2365403134 Joystick4ThetaAxisPos "J1939-71";
BA_ "SigType" SG_ 2365403134 Jystck4ThtAxsClckwsPstvPosStatus 4;
BA_ "SPN" SG_ 2365403134 Jystck4ThtAxsClckwsPstvPosStatus 4523;
BA_ "SAEDocument" SG_ 2365403134 Jystck4ThtAxsClckwsPstvPosStatus "J1939-71";
BA_ "SigType" SG_ 2365403134 Jystck4ThtAxsCntrClckwsNgtvPsStt 4;
BA_ "SPN" SG_ 2365403134 Jystck4ThtAxsCntrClckwsNgtvPsStt 4522;
BA_ "SAEDocument" SG_ 2365403134 Jystck4ThtAxsCntrClckwsNgtvPsStt "J1939-71";
BA_ "SigType" SG_ 2365403134 Jystck4ThetaAxisNeutralPosStatus 4;
BA_ "SPN" SG_ 2365403134 Jystck4ThetaAxisNeutralPosStatus 4521;
BA_ "SAEDocument" SG_ 2365403134 Jystck4ThetaAxisNeutralPosStatus "J1939-71";
BA_ "SPN" SG_ 2365403134 Joystick4GripYAxisPos 4520;
BA_ "SAEDocument" SG_ 2365403134 Joystick4GripYAxisPos "J1939-71";
BA_ "SigType" SG_ 2365403134 Jystck4GrpYAxsLvrFrwrdPstvPsStts 4;
BA_ "SPN" SG_ 2365403134 Jystck4GrpYAxsLvrFrwrdPstvPsStts 4519;
BA_ "SAEDocument" SG_ 2365403134 Jystck4GrpYAxsLvrFrwrdPstvPsStts "J1939-71";
BA_ "SigType" SG_ 2365403134 Jystck4GrpYAxsLvrBckNgtvPsStatus 4;
BA_ "SPN" SG_ 2365403134 Jystck4GrpYAxsLvrBckNgtvPsStatus 4518;
BA_ "SAEDocument" SG_ 2365403134 Jystck4GrpYAxsLvrBckNgtvPsStatus "J1939-71";
BA_ "SigType" SG_ 2365403134 Jystck4GripYAxisNeutralPosStatus 4;
BA_ "SPN" SG_ 2365403134 Jystck4GripYAxisNeutralPosStatus 4517;
BA_ "SAEDocument" SG_ 2365403134 Jystck4GripYAxisNeutralPosStatus "J1939-71";
BA_ "SPN" SG_ 2365403134 Joystick4GripXAxisPos 4516;
BA_ "SAEDocument" SG_ 2365403134 Joystick4GripXAxisPos "J1939-71";
BA_ "SigType" SG_ 2365403134 Jystck4GrpXAxsLvrRghtPstvPsSttus 4;
BA_ "SPN" SG_ 2365403134 Jystck4GrpXAxsLvrRghtPstvPsSttus 4515;
BA_ "SAEDocument" SG_ 2365403134 Jystck4GrpXAxsLvrRghtPstvPsSttus "J1939-71";
BA_ "SigType" SG_ 2365403134 Jystck4GrpXAxsLvrLftNgtvPsStatus 4;
BA_ "SPN" SG_ 2365403134 Jystck4GrpXAxsLvrLftNgtvPsStatus 4514;
BA_ "SAEDocument" SG_ 2365403134 Jystck4GrpXAxsLvrLftNgtvPsStatus "J1939-71";
BA_ "SigType" SG_ 2365403134 Jystck4GripXAxisNeutralPosStatus 4;
BA_ "SPN" SG_ 2365403134 Jystck4GripXAxisNeutralPosStatus 4513;
BA_ "SAEDocument" SG_ 2365403134 Jystck4GripXAxisNeutralPosStatus "J1939-71";
BA_ "SigType" SG_ 2365400062 Jystck10GripXAxisDetentPosStatus 4;
BA_ "SPN" SG_ 2365400062 Jystck10GripXAxisDetentPosStatus 4749;
BA_ "SAEDocument" SG_ 2365400062 Jystck10GripXAxisDetentPosStatus "J1939-71";
BA_ "SigType" SG_ 2365400062 Jystck10GripYAxisDetentPosStatus 4;
BA_ "SPN" SG_ 2365400062 Jystck10GripYAxisDetentPosStatus 4748;
BA_ "SAEDocument" SG_ 2365400062 Jystck10GripYAxisDetentPosStatus "J1939-71";
BA_ "SigType" SG_ 2365400062 Jystck10ThetaAxisDetentPosStatus 4;
BA_ "SPN" SG_ 2365400062 Jystck10ThetaAxisDetentPosStatus 4747;
BA_ "SAEDocument" SG_ 2365400062 Jystck10ThetaAxisDetentPosStatus "J1939-71";
BA_ "SPN" SG_ 2365400062 Joystick10ThetaAxisPos 4746;
BA_ "SAEDocument" SG_ 2365400062 Joystick10ThetaAxisPos "J1939-71";
BA_ "SigType" SG_ 2365400062 Jystck10ThtAxsClckwsPstvPsStatus 4;
BA_ "SPN" SG_ 2365400062 Jystck10ThtAxsClckwsPstvPsStatus 4745;
BA_ "SAEDocument" SG_ 2365400062 Jystck10ThtAxsClckwsPstvPsStatus "J1939-71";
BA_ "SigType" SG_ 2365400062 Jystck10ThtAxsCntrClckwsNgtvPsSt 4;
BA_ "SPN" SG_ 2365400062 Jystck10ThtAxsCntrClckwsNgtvPsSt 4744;
BA_ "SAEDocument" SG_ 2365400062 Jystck10ThtAxsCntrClckwsNgtvPsSt "J1939-71";
BA_ "SigType" SG_ 2365400062 Jystck10ThtaAxisNeutralPosStatus 4;
BA_ "SPN" SG_ 2365400062 Jystck10ThtaAxisNeutralPosStatus 4743;
BA_ "SAEDocument" SG_ 2365400062 Jystck10ThtaAxisNeutralPosStatus "J1939-71";
BA_ "SPN" SG_ 2365400062 Joystick10GripYAxisPos 4742;
BA_ "SAEDocument" SG_ 2365400062 Joystick10GripYAxisPos "J1939-71";
BA_ "SigType" SG_ 2365400062 Jystck10GrpYAxsLvrFrwrdPstvPsStt 4;
BA_ "SPN" SG_ 2365400062 Jystck10GrpYAxsLvrFrwrdPstvPsStt 4741;
BA_ "SAEDocument" SG_ 2365400062 Jystck10GrpYAxsLvrFrwrdPstvPsStt "J1939-71";
BA_ "SigType" SG_ 2365400062 Jystck10GrpYAxsLvrBckNgtvPsSttus 4;
BA_ "SPN" SG_ 2365400062 Jystck10GrpYAxsLvrBckNgtvPsSttus 4740;
BA_ "SAEDocument" SG_ 2365400062 Jystck10GrpYAxsLvrBckNgtvPsSttus "J1939-71";
BA_ "SigType" SG_ 2365400062 Jystck10GrpYAxisNeutralPosStatus 4;
BA_ "SPN" SG_ 2365400062 Jystck10GrpYAxisNeutralPosStatus 4739;
BA_ "SAEDocument" SG_ 2365400062 Jystck10GrpYAxisNeutralPosStatus "J1939-71";
BA_ "SPN" SG_ 2365400062 Joystick10GripXAxisPos 4738;
BA_ "SAEDocument" SG_ 2365400062 Joystick10GripXAxisPos "J1939-71";
BA_ "SigType" SG_ 2365400062 Jystck10GrpXAxsLvrRghtPstvPsStts 4;
BA_ "SPN" SG_ 2365400062 Jystck10GrpXAxsLvrRghtPstvPsStts 4737;
BA_ "SAEDocument" SG_ 2365400062 Jystck10GrpXAxsLvrRghtPstvPsStts "J1939-71";
BA_ "SigType" SG_ 2365400062 Jystck10GrpXAxsLvrLftNgtvPsSttus 4;
BA_ "SPN" SG_ 2365400062 Jystck10GrpXAxsLvrLftNgtvPsSttus 4736;
BA_ "SAEDocument" SG_ 2365400062 Jystck10GrpXAxsLvrLftNgtvPsSttus "J1939-71";
BA_ "SigType" SG_ 2365400062 Jystck10GrpXAxisNeutralPosStatus 4;
BA_ "SPN" SG_ 2365400062 Jystck10GrpXAxisNeutralPosStatus 4735;
BA_ "SAEDocument" SG_ 2365400062 Jystck10GrpXAxisNeutralPosStatus "J1939-71";
BA_ "SigType" SG_ 2566713598 EngFuelFilterIntakeAbsPress 1;
BA_ "SPN" SG_ 2566713598 EngFuelFilterIntakeAbsPress 5417;
BA_ "SAEDocument" SG_ 2566713598 EngFuelFilterIntakeAbsPress "J1939-71";
BA_ "SigType" SG_ 2499604478 EngExhstGsRcrcltn1OutletAbsPress 1;
BA_ "SPN" SG_ 2499604478 EngExhstGsRcrcltn1OutletAbsPress 5431;
BA_ "SAEDocument" SG_ 2499604478 EngExhstGsRcrcltn1OutletAbsPress "J1939-71";
BA_ "SigType" SG_ 2499604478 EngExhstGsRcrcltn1IntakeAbsPress 1;
BA_ "SPN" SG_ 2499604478 EngExhstGsRcrcltn1IntakeAbsPress 5430;
BA_ "SAEDocument" SG_ 2499604478 EngExhstGsRcrcltn1IntakeAbsPress "J1939-71";
BA_ "SigType" SG_ 2499608830 EngExhstGsRcrcltn2IntakeAbsPress 1;
BA_ "SPN" SG_ 2499608830 EngExhstGsRcrcltn2IntakeAbsPress 5429;
BA_ "SAEDocument" SG_ 2499608830 EngExhstGsRcrcltn2IntakeAbsPress "J1939-71";
BA_ "SigType" SG_ 2499608830 EngExhstGsRcrcltn2OutletAbsPress 1;
BA_ "SPN" SG_ 2499608830 EngExhstGsRcrcltn2OutletAbsPress 5254;
BA_ "SAEDocument" SG_ 2499608830 EngExhstGsRcrcltn2OutletAbsPress "J1939-71";
BA_ "SigType" SG_ 2499608830 EngExhstGsRcrclation2IntakePress 1;
BA_ "SPN" SG_ 2499608830 EngExhstGsRcrclation2IntakePress 5253;
BA_ "SAEDocument" SG_ 2499608830 EngExhstGsRcrclation2IntakePress "J1939-71";
BA_ "SigType" SG_ 2499608830 EngExhstGsRcirculation2DiffPress 1;
BA_ "SPN" SG_ 2499608830 EngExhstGsRcirculation2DiffPress 5252;
BA_ "SAEDocument" SG_ 2499608830 EngExhstGsRcirculation2DiffPress "J1939-71";
BA_ "SigType" SG_ 2432499198 CmmndedEngFuelInjectionCtrlPress 1;
BA_ "SPN" SG_ 2432499198 CmmndedEngFuelInjectionCtrlPress 5314;
BA_ "SAEDocument" SG_ 2432499198 CmmndedEngFuelInjectionCtrlPress "J1939-71";
BA_ "SigType" SG_ 2432499198 CommandedEngFuelRailPress 1;
BA_ "SPN" SG_ 2432499198 CommandedEngFuelRailPress 5313;
BA_ "SAEDocument" SG_ 2432499198 CommandedEngFuelRailPress "J1939-71";
BA_ "SigType" SG_ 2432499198 EngExhstGsRcirculation2Valve2Pos 1;
BA_ "SPN" SG_ 2432499198 EngExhstGsRcirculation2Valve2Pos 5263;
BA_ "SAEDocument" SG_ 2432499198 EngExhstGsRcirculation2Valve2Pos "J1939-71";
BA_ "SigType" SG_ 2432499198 EngExhstGsRecirculation2ValvePos 1;
BA_ "SPN" SG_ 2432499198 EngExhstGsRecirculation2ValvePos 5262;
BA_ "SAEDocument" SG_ 2432499198 EngExhstGsRecirculation2ValvePos "J1939-71";
BA_ "SigType" SG_ 2633825022 EngExhstGsRcrculation2Valve2Ctrl 1;
BA_ "SPN" SG_ 2633825022 EngExhstGsRcrculation2Valve2Ctrl 5265;
BA_ "SAEDocument" SG_ 2633825022 EngExhstGsRcrculation2Valve2Ctrl "J1939-71";
BA_ "SigType" SG_ 2633825022 EngExhstGsRcirculation2ValveCtrl 1;
BA_ "SPN" SG_ 2633825022 EngExhstGsRcirculation2ValveCtrl 5264;
BA_ "SAEDocument" SG_ 2633825022 EngExhstGsRcirculation2ValveCtrl "J1939-71";
BA_ "SigType" SG_ 2633826046 EGR2CoolerBypassActuatorPos 1;
BA_ "SPN" SG_ 2633826046 EGR2CoolerBypassActuatorPos 5261;
BA_ "SAEDocument" SG_ 2633826046 EGR2CoolerBypassActuatorPos "J1939-71";
BA_ "SigType" SG_ 2633826046 EngExhstGsRcrcltn2ClerEfficiency 1;
BA_ "SPN" SG_ 2633826046 EngExhstGsRcrcltn2ClerEfficiency 5260;
BA_ "SAEDocument" SG_ 2633826046 EngExhstGsRcrcltn2ClerEfficiency "J1939-71";
BA_ "SigType" SG_ 2633826046 EngExhstGsRcrcltn2ClrIntkGsAbsPr 1;
BA_ "SPN" SG_ 2633826046 EngExhstGsRcrcltn2ClrIntkGsAbsPr 5259;
BA_ "SAEDocument" SG_ 2633826046 EngExhstGsRcrcltn2ClrIntkGsAbsPr "J1939-71";
BA_ "SigType" SG_ 2633826046 EngExhstGsRcrcltn2ClerIntakeTemp 1;
BA_ "SPN" SG_ 2633826046 EngExhstGsRcrcltn2ClerIntakeTemp 5258;
BA_ "SAEDocument" SG_ 2633826046 EngExhstGsRcrcltn2ClerIntakeTemp "J1939-71";
BA_ "SigType" SG_ 2566711294 EngFrctnPrcentTorqueAtIdlePoint7 1;
BA_ "SPN" SG_ 2566711294 EngFrctnPrcentTorqueAtIdlePoint7 5477;
BA_ "SAEDocument" SG_ 2566711294 EngFrctnPrcentTorqueAtIdlePoint7 "J1939-71";
BA_ "SigType" SG_ 2566711294 EngFrctnPrcentTorqueAtIdlePoint6 1;
BA_ "SPN" SG_ 2566711294 EngFrctnPrcentTorqueAtIdlePoint6 5476;
BA_ "SAEDocument" SG_ 2566711294 EngFrctnPrcentTorqueAtIdlePoint6 "J1939-71";
BA_ "SigType" SG_ 2566711294 EngFrctnPrcentTorqueAtIdlePoint5 1;
BA_ "SPN" SG_ 2566711294 EngFrctnPrcentTorqueAtIdlePoint5 5475;
BA_ "SAEDocument" SG_ 2566711294 EngFrctnPrcentTorqueAtIdlePoint5 "J1939-71";
BA_ "SigType" SG_ 2566711294 EngFrctnPrcentTorqueAtIdlePoint4 1;
BA_ "SPN" SG_ 2566711294 EngFrctnPrcentTorqueAtIdlePoint4 5474;
BA_ "SAEDocument" SG_ 2566711294 EngFrctnPrcentTorqueAtIdlePoint4 "J1939-71";
BA_ "SigType" SG_ 2566711294 EngFrctnPrcentTorqueAtIdlePoint3 1;
BA_ "SPN" SG_ 2566711294 EngFrctnPrcentTorqueAtIdlePoint3 5473;
BA_ "SAEDocument" SG_ 2566711294 EngFrctnPrcentTorqueAtIdlePoint3 "J1939-71";
BA_ "SigType" SG_ 2566711294 EngFrctnPrcentTorqueAtIdlePoint2 1;
BA_ "SPN" SG_ 2566711294 EngFrctnPrcentTorqueAtIdlePoint2 5472;
BA_ "SAEDocument" SG_ 2566711294 EngFrctnPrcentTorqueAtIdlePoint2 "J1939-71";
BA_ "SigType" SG_ 2566711294 EngFrctnPrcentTorqueAtIdlePoint1 1;
BA_ "SPN" SG_ 2566711294 EngFrctnPrcentTorqueAtIdlePoint1 5471;
BA_ "SAEDocument" SG_ 2566711294 EngFrctnPrcentTorqueAtIdlePoint1 "J1939-71";
BA_ "SPN" SG_ 2566749438 DslPrtcltFltrActvRgnrtnFrcdSttus 4175;
BA_ "SAEDocument" SG_ 2566749438 DslPrtcltFltrActvRgnrtnFrcdSttus "J1939-71";
BA_ "SPN" SG_ 2566749438 ExhaustSystemHighTempLampCmd 3698;
BA_ "SAEDocument" SG_ 2566749438 ExhaustSystemHighTempLampCmd "J1939-71";
BA_ "SigType" SG_ 2566749438 DslPrtcltFltrAtmtcActvRgnrtnIntt 5;
BA_ "SPN" SG_ 2566749438 DslPrtcltFltrAtmtcActvRgnrtnIntt 3718;
BA_ "SAEDocument" SG_ 2566749438 DslPrtcltFltrAtmtcActvRgnrtnIntt "J1939-71";
BA_ "SigType" SG_ 2566749438 DslPrtcltFltrActvRgnrtnInhbtdDTV 4;
BA_ "SPN" SG_ 2566749438 DslPrtcltFltrActvRgnrtnInhbtdDTV 3717;
BA_ "SAEDocument" SG_ 2566749438 DslPrtcltFltrActvRgnrtnInhbtdDTV "J1939-71";
BA_ "SystemSignalLongSymbol" SG_ 2566749438 DslPrtcltFltrActvRgnrtnInhbtdDTV "DslPrtcltFltrActvRgnrtnInhbtdDTVhclSpdBlwAllwd";
BA_ "SigType" SG_ 2566749438 DslPrtcltFltrActvRgnrtnInhbtdDTE 4;
BA_ "SPN" SG_ 2566749438 DslPrtcltFltrActvRgnrtnInhbtdDTE 3716;
BA_ "SAEDocument" SG_ 2566749438 DslPrtcltFltrActvRgnrtnInhbtdDTE "J1939-71";
BA_ "SystemSignalLongSymbol" SG_ 2566749438 DslPrtcltFltrActvRgnrtnInhbtdDTE "DslPrtcltFltrActvRgnrtnInhbtdDTEngNtWrmdUp";
BA_ "SigType" SG_ 2566749438 DslPrtcltFltrActvRgnrtnInhb_0000 4;
BA_ "SPN" SG_ 2566749438 DslPrtcltFltrActvRgnrtnInhb_0000 3715;
BA_ "SAEDocument" SG_ 2566749438 DslPrtcltFltrActvRgnrtnInhb_0000 "J1939-71";
BA_ "SystemSignalLongSymbol" SG_ 2566749438 DslPrtcltFltrActvRgnrtnInhb_0000 "DslPrtcltFltrActvRgnrtnInhbtdDTPrmnntSystmLckt";
BA_ "SigType" SG_ 2566749438 DslPrtcltFltrActvRgnrtnInhbtdDTT 5;
BA_ "SPN" SG_ 2566749438 DslPrtcltFltrActvRgnrtnInhbtdDTT 3714;
BA_ "SAEDocument" SG_ 2566749438 DslPrtcltFltrActvRgnrtnInhbtdDTT "J1939-71";
BA_ "SigType" SG_ 2566749438 DslPrtcltFltrActvRgnrtnInhbtdDTS 5;
BA_ "SPN" SG_ 2566749438 DslPrtcltFltrActvRgnrtnInhbtdDTS 3705;
BA_ "SAEDocument" SG_ 2566749438 DslPrtcltFltrActvRgnrtnInhbtdDTS "J1939-71";
BA_ "SigType" SG_ 2566749438 DslPrtcltFltrActvRgnrtnInhbtdDTL 4;
BA_ "SPN" SG_ 2566749438 DslPrtcltFltrActvRgnrtnInhbtdDTL 3711;
BA_ "SAEDocument" SG_ 2566749438 DslPrtcltFltrActvRgnrtnInhbtdDTL "J1939-71";
BA_ "SigType" SG_ 2566749438 DslPrtcltFltrActvRgnrtnInhb_0001 4;
BA_ "SPN" SG_ 2566749438 DslPrtcltFltrActvRgnrtnInhb_0001 3710;
BA_ "SAEDocument" SG_ 2566749438 DslPrtcltFltrActvRgnrtnInhb_0001 "J1939-71";
BA_ "SystemSignalLongSymbol" SG_ 2566749438 DslPrtcltFltrActvRgnrtnInhb_0001 "DslPrtcltFltrActvRgnrtnInhbtdDTPrkngBrkNtSt";
BA_ "SigType" SG_ 2566749438 DslPrtcltFltrActvRgnrtnInhb_0002 4;
BA_ "SPN" SG_ 2566749438 DslPrtcltFltrActvRgnrtnInhb_0002 3709;
BA_ "SAEDocument" SG_ 2566749438 DslPrtcltFltrActvRgnrtnInhb_0002 "J1939-71";
BA_ "SystemSignalLongSymbol" SG_ 2566749438 DslPrtcltFltrActvRgnrtnInhb_0002 "DslPrtcltFltrActvRgnrtnInhbtdDTVhclSpdAbvAllwd";
BA_ "SigType" SG_ 2566749438 DslPrtcltFltrActvRgnrtnInhbtdDTO 4;
BA_ "SPN" SG_ 2566749438 DslPrtcltFltrActvRgnrtnInhbtdDTO 3708;
BA_ "SAEDocument" SG_ 2566749438 DslPrtcltFltrActvRgnrtnInhbtdDTO "J1939-71";
BA_ "SystemSignalLongSymbol" SG_ 2566749438 DslPrtcltFltrActvRgnrtnInhbtdDTO "DslPrtcltFltrActvRgnrtnInhbtdDTOtOfNtrl";
BA_ "SigType" SG_ 2566749438 DslPrtcltFltrActvRgnrtnInhbtdDTA 5;
BA_ "SPN" SG_ 2566749438 DslPrtcltFltrActvRgnrtnInhbtdDTA 3707;
BA_ "SAEDocument" SG_ 2566749438 DslPrtcltFltrActvRgnrtnInhbtdDTA "J1939-71";
BA_ "SigType" SG_ 2566749438 DslPrtcltFltrActvRgnrtnInhbtdDTP 5;
BA_ "SPN" SG_ 2566749438 DslPrtcltFltrActvRgnrtnInhbtdDTP 3706;
BA_ "SAEDocument" SG_ 2566749438 DslPrtcltFltrActvRgnrtnInhbtdDTP "J1939-71";
BA_ "SigType" SG_ 2566749438 DslPrtcltFltrActvRgnrtnInhbtdDTC 5;
BA_ "SPN" SG_ 2566749438 DslPrtcltFltrActvRgnrtnInhbtdDTC 3704;
BA_ "SAEDocument" SG_ 2566749438 DslPrtcltFltrActvRgnrtnInhbtdDTC "J1939-71";
BA_ "SigType" SG_ 2566749438 DslPrtcltFltrActvRgnrtnInhbtdDTI 5;
BA_ "SPN" SG_ 2566749438 DslPrtcltFltrActvRgnrtnInhbtdDTI 3703;
BA_ "SAEDocument" SG_ 2566749438 DslPrtcltFltrActvRgnrtnInhbtdDTI "J1939-71";
BA_ "SigType" SG_ 2566749438 DslPrtcltFltrActvRgnrtnInhbtdStt 5;
BA_ "SPN" SG_ 2566749438 DslPrtcltFltrActvRgnrtnInhbtdStt 3702;
BA_ "SAEDocument" SG_ 2566749438 DslPrtcltFltrActvRgnrtnInhbtdStt "J1939-71";
BA_ "SPN" SG_ 2566749438 DieselParticulateFilterStatus 3701;
BA_ "SAEDocument" SG_ 2566749438 DieselParticulateFilterStatus "J1939-71";
BA_ "SigType" SG_ 2566749438 DslPrtcltFltrActvRgnrationStatus 5;
BA_ "SPN" SG_ 2566749438 DslPrtcltFltrActvRgnrationStatus 3700;
BA_ "SAEDocument" SG_ 2566749438 DslPrtcltFltrActvRgnrationStatus "J1939-71";
BA_ "SigType" SG_ 2566749438 DslPrtcltFltrPssvRgnrationStatus 5;
BA_ "SPN" SG_ 2566749438 DslPrtcltFltrPssvRgnrationStatus 3699;
BA_ "SAEDocument" SG_ 2566749438 DslPrtcltFltrPssvRgnrationStatus "J1939-71";
BA_ "SPN" SG_ 2566749438 DieselParticulateFilterLampCmd 3697;
BA_ "SAEDocument" SG_ 2566749438 DieselParticulateFilterLampCmd "J1939-71";
BA_ "SigType" SG_ 2566715646 DslPrtculateFilter2SootSignalMin 1;
BA_ "SPN" SG_ 2566715646 DslPrtculateFilter2SootSignalMin 5271;
BA_ "SAEDocument" SG_ 2566715646 DslPrtculateFilter2SootSignalMin "J1939-71";
BA_ "SigType" SG_ 2566715646 DslPrtculateFilter2SootSignalMax 1;
BA_ "SPN" SG_ 2566715646 DslPrtculateFilter2SootSignalMax 5270;
BA_ "SAEDocument" SG_ 2566715646 DslPrtculateFilter2SootSignalMax "J1939-71";
BA_ "SigType" SG_ 2566715646 DslPrtcltFltr2StSgnlStndrdDvtion 1;
BA_ "SPN" SG_ 2566715646 DslPrtcltFltr2StSgnlStndrdDvtion 5269;
BA_ "SAEDocument" SG_ 2566715646 DslPrtcltFltr2StSgnlStndrdDvtion "J1939-71";
BA_ "SPN" SG_ 2566724606 DslPrtcltFltr2StSnsrPrlminaryFMI 4790;
BA_ "SAEDocument" SG_ 2566724606 DslPrtcltFltr2StSnsrPrlminaryFMI "J1939-71";
BA_ "SigType" SG_ 2566724606 DslPrtcltFilter2MedianSootSignal 1;
BA_ "SPN" SG_ 2566724606 DslPrtcltFilter2MedianSootSignal 4789;
BA_ "SAEDocument" SG_ 2566724606 DslPrtcltFilter2MedianSootSignal "J1939-71";
BA_ "SigType" SG_ 2566724606 DslPrtclateFilter2MeanSootSignal 1;
BA_ "SPN" SG_ 2566724606 DslPrtclateFilter2MeanSootSignal 4788;
BA_ "SAEDocument" SG_ 2566724606 DslPrtclateFilter2MeanSootSignal "J1939-71";
BA_ "SigType" SG_ 2566724606 DslParticulateFilter2SootDensity 1;
BA_ "SPN" SG_ 2566724606 DslParticulateFilter2SootDensity 4787;
BA_ "SAEDocument" SG_ 2566724606 DslParticulateFilter2SootDensity "J1939-71";
BA_ "SigType" SG_ 2566724606 DieselParticulateFilter2SootMass 1;
BA_ "SPN" SG_ 2566724606 DieselParticulateFilter2SootMass 4786;
BA_ "SAEDocument" SG_ 2566724606 DieselParticulateFilter2SootMass "J1939-71";
BA_ "SigType" SG_ 2566715902 DslPrtculateFilter1SootSignalMin 1;
BA_ "SPN" SG_ 2566715902 DslPrtculateFilter1SootSignalMin 5268;
BA_ "SAEDocument" SG_ 2566715902 DslPrtculateFilter1SootSignalMin "J1939-71";
BA_ "SigType" SG_ 2566715902 DslPrtculateFilter1SootSignalMax 1;
BA_ "SPN" SG_ 2566715902 DslPrtculateFilter1SootSignalMax 5267;
BA_ "SAEDocument" SG_ 2566715902 DslPrtculateFilter1SootSignalMax "J1939-71";
BA_ "SigType" SG_ 2566715902 DslPrtcltFltr1StSgnlStndrdDvtion 1;
BA_ "SPN" SG_ 2566715902 DslPrtcltFltr1StSgnlStndrdDvtion 5266;
BA_ "SAEDocument" SG_ 2566715902 DslPrtcltFltr1StSgnlStndrdDvtion "J1939-71";
BA_ "SPN" SG_ 2566724862 DslPrtcltFltr1StSnsrPrlminaryFMI 4785;
BA_ "SAEDocument" SG_ 2566724862 DslPrtcltFltr1StSnsrPrlminaryFMI "J1939-71";
BA_ "SigType" SG_ 2566724862 DslPrtcltFilter1MedianSootSignal 1;
BA_ "SPN" SG_ 2566724862 DslPrtcltFilter1MedianSootSignal 4784;
BA_ "SAEDocument" SG_ 2566724862 DslPrtcltFilter1MedianSootSignal "J1939-71";
BA_ "SigType" SG_ 2566724862 DslPrtclateFilter1MeanSootSignal 1;
BA_ "SPN" SG_ 2566724862 DslPrtclateFilter1MeanSootSignal 4783;
BA_ "SAEDocument" SG_ 2566724862 DslPrtclateFilter1MeanSootSignal "J1939-71";
BA_ "SigType" SG_ 2566724862 DslParticulateFilter1SootDensity 1;
BA_ "SPN" SG_ 2566724862 DslParticulateFilter1SootDensity 4782;
BA_ "SAEDocument" SG_ 2566724862 DslParticulateFilter1SootDensity "J1939-71";
BA_ "SigType" SG_ 2566724862 DieselParticulateFilter1SootMass 1;
BA_ "SPN" SG_ 2566724862 DieselParticulateFilter1SootMass 4781;
BA_ "SAEDocument" SG_ 2566724862 DieselParticulateFilter1SootMass "J1939-71";
BA_ "SigType" SG_ 2566718718 VehicleBatteryChargingLampData 4;
BA_ "SPN" SG_ 2566718718 VehicleBatteryChargingLampData 5108;
BA_ "SAEDocument" SG_ 2566718718 VehicleBatteryChargingLampData "J1939-71";
BA_ "SigType" SG_ 2566718718 VehicleHVACRecirculationLampData 4;
BA_ "SPN" SG_ 2566718718 VehicleHVACRecirculationLampData 5107;
BA_ "SAEDocument" SG_ 2566718718 VehicleHVACRecirculationLampData "J1939-71";
BA_ "SigType" SG_ 2566718718 VehicleAirPressLowLampData 4;
BA_ "SPN" SG_ 2566718718 VehicleAirPressLowLampData 5106;
BA_ "SAEDocument" SG_ 2566718718 VehicleAirPressLowLampData "J1939-71";
BA_ "SigType" SG_ 2566718718 VehicleFuelLevelLowLampData 4;
BA_ "SPN" SG_ 2566718718 VehicleFuelLevelLowLampData 5105;
BA_ "SAEDocument" SG_ 2566718718 VehicleFuelLevelLowLampData "J1939-71";
BA_ "SigType" SG_ 2566718718 VehicleBatteryVoltageLowLampData 4;
BA_ "SPN" SG_ 2566718718 VehicleBatteryVoltageLowLampData 5104;
BA_ "SAEDocument" SG_ 2566718718 VehicleBatteryVoltageLowLampData "J1939-71";
BA_ "SigType" SG_ 2566718974 EngWaitToStartLampData 4;
BA_ "SPN" SG_ 2566718974 EngWaitToStartLampData 5416;
BA_ "SAEDocument" SG_ 2566718974 EngWaitToStartLampData "J1939-71";
BA_ "SigType" SG_ 2566718974 EngFuelFilterRestrictedLampData 5;
BA_ "SPN" SG_ 2566718974 EngFuelFilterRestrictedLampData 5470;
BA_ "SAEDocument" SG_ 2566718974 EngFuelFilterRestrictedLampData "J1939-71";
BA_ "SigType" SG_ 2566718974 EngAirFilterRestrictionLampData 4;
BA_ "SPN" SG_ 2566718974 EngAirFilterRestrictionLampData 5103;
BA_ "SAEDocument" SG_ 2566718974 EngAirFilterRestrictionLampData "J1939-71";
BA_ "SigType" SG_ 2566718974 EngIdleManagementActiveLampData 4;
BA_ "SPN" SG_ 2566718974 EngIdleManagementActiveLampData 5102;
BA_ "SAEDocument" SG_ 2566718974 EngIdleManagementActiveLampData "J1939-71";
BA_ "SigType" SG_ 2566718974 EngCoolantLevelLowLampData 4;
BA_ "SPN" SG_ 2566718974 EngCoolantLevelLowLampData 5101;
BA_ "SAEDocument" SG_ 2566718974 EngCoolantLevelLowLampData "J1939-71";
BA_ "SigType" SG_ 2566718974 EngCoolantTempHighLampData 4;
BA_ "SPN" SG_ 2566718974 EngCoolantTempHighLampData 5100;
BA_ "SAEDocument" SG_ 2566718974 EngCoolantTempHighLampData "J1939-71";
BA_ "SigType" SG_ 2566718974 EngOilPressLowLampData 4;
BA_ "SPN" SG_ 2566718974 EngOilPressLowLampData 5099;
BA_ "SAEDocument" SG_ 2566718974 EngOilPressLowLampData "J1939-71";
BA_ "SigType" SG_ 2566718974 CmprssnBrkEnblSwtchIndctrLmpData 4;
BA_ "SPN" SG_ 2566718974 CmprssnBrkEnblSwtchIndctrLmpData 5098;
BA_ "SAEDocument" SG_ 2566718974 CmprssnBrkEnblSwtchIndctrLmpData "J1939-71";
BA_ "SigType" SG_ 2566718974 EngBrakeActiveLampData 4;
BA_ "SPN" SG_ 2566718974 EngBrakeActiveLampData 5097;
BA_ "SAEDocument" SG_ 2566718974 EngBrakeActiveLampData "J1939-71";
BA_ "SigType" SG_ 2566718974 OBDMalfunctionIndicatorLampData 4;
BA_ "SPN" SG_ 2566718974 OBDMalfunctionIndicatorLampData 5096;
BA_ "SAEDocument" SG_ 2566718974 OBDMalfunctionIndicatorLampData "J1939-71";
BA_ "SigType" SG_ 2566718974 EngRedStopLampData 4;
BA_ "SPN" SG_ 2566718974 EngRedStopLampData 5095;
BA_ "SAEDocument" SG_ 2566718974 EngRedStopLampData "J1939-71";
BA_ "SigType" SG_ 2566718974 EngAmberWarningLampData 4;
BA_ "SPN" SG_ 2566718974 EngAmberWarningLampData 5094;
BA_ "SAEDocument" SG_ 2566718974 EngAmberWarningLampData "J1939-71";
BA_ "SigType" SG_ 2566718974 EngProtectLampData 4;
BA_ "SPN" SG_ 2566718974 EngProtectLampData 5093;
BA_ "SAEDocument" SG_ 2566718974 EngProtectLampData "J1939-71";
BA_ "SigType" SG_ 2566719230 VehicleBatteryChargingLampCmd 5;
BA_ "SPN" SG_ 2566719230 VehicleBatteryChargingLampCmd 5091;
BA_ "SAEDocument" SG_ 2566719230 VehicleBatteryChargingLampCmd "J1939-71";
BA_ "SigType" SG_ 2566719230 VehicleHVACRecirculationLampCmd 5;
BA_ "SPN" SG_ 2566719230 VehicleHVACRecirculationLampCmd 5090;
BA_ "SAEDocument" SG_ 2566719230 VehicleHVACRecirculationLampCmd "J1939-71";
BA_ "SigType" SG_ 2566719230 VehicleAirPressLowLampCmd 5;
BA_ "SPN" SG_ 2566719230 VehicleAirPressLowLampCmd 5089;
BA_ "SAEDocument" SG_ 2566719230 VehicleAirPressLowLampCmd "J1939-71";
BA_ "SigType" SG_ 2566719230 VehicleFuelLevelLowLampCmd 5;
BA_ "SPN" SG_ 2566719230 VehicleFuelLevelLowLampCmd 5088;
BA_ "SAEDocument" SG_ 2566719230 VehicleFuelLevelLowLampCmd "J1939-71";
BA_ "SigType" SG_ 2566719230 VehicleBatteryVoltageLowLampCmd 5;
BA_ "SPN" SG_ 2566719230 VehicleBatteryVoltageLowLampCmd 5087;
BA_ "SAEDocument" SG_ 2566719230 VehicleBatteryVoltageLowLampCmd "J1939-71";
BA_ "SigType" SG_ 2560818942 DTCTimeUntilDerate 1;
BA_ "SPN" SG_ 2560818942 DTCTimeUntilDerate 4123;
BA_ "SAEDocument" SG_ 2560818942 DTCTimeUntilDerate "J1939_73";
BA_ "SigType" SG_ 2560818942 DTCTotalPreviouslyActiveTime 1;
BA_ "SPN" SG_ 2560818942 DTCTotalPreviouslyActiveTime 4122;
BA_ "SAEDocument" SG_ 2560818942 DTCTotalPreviouslyActiveTime "J1939_73";
BA_ "SigType" SG_ 2560818942 DTCTotalActiveTime 1;
BA_ "SPN" SG_ 2560818942 DTCTotalActiveTime 4121;
BA_ "SAEDocument" SG_ 2560818942 DTCTotalActiveTime "J1939_73";
BA_ "SPN" SG_ 2560818942 FailureModeIdentifier1 1215;
BA_ "SAEDocument" SG_ 2560818942 FailureModeIdentifier1 "J1939-73";
BA_ "SAEDocument" SG_ 2560818942 SPN1High "J1939-73";
BA_ "SPN" SG_ 2560818942 SPN1 1214;
BA_ "SAEDocument" SG_ 2560818942 SPN1 "J1939-73";
BA_ "SPN" SG_ 2561212158 TextDisplayIndex 3614;
BA_ "SAEDocument" SG_ 2561212158 TextDisplayIndex "J1939-71";
BA_ "SPN" SG_ 2561212158 TextDisplayInstructions 3613;
BA_ "SAEDocument" SG_ 2561212158 TextDisplayInstructions "J1939-71";
BA_ "SigType" SG_ 2566746366 RetractStatusOfRamp5 5;
BA_ "SPN" SG_ 2566746366 RetractStatusOfRamp5 4457;
BA_ "SAEDocument" SG_ 2566746366 RetractStatusOfRamp5 "J1939-71";
BA_ "SigType" SG_ 2566746366 RetractStatusOfRamp4 5;
BA_ "SPN" SG_ 2566746366 RetractStatusOfRamp4 4454;
BA_ "SAEDocument" SG_ 2566746366 RetractStatusOfRamp4 "J1939-71";
BA_ "SigType" SG_ 2566746366 MovementStatusOfRamp5 5;
BA_ "SPN" SG_ 2566746366 MovementStatusOfRamp5 4459;
BA_ "SAEDocument" SG_ 2566746366 MovementStatusOfRamp5 "J1939-71";
BA_ "SigType" SG_ 2566746366 MovementStatusOfRamp4 5;
BA_ "SPN" SG_ 2566746366 MovementStatusOfRamp4 4456;
BA_ "SAEDocument" SG_ 2566746366 MovementStatusOfRamp4 "J1939-71";
BA_ "SigType" SG_ 2566746366 EnableStatusOfRamp5 5;
BA_ "SPN" SG_ 2566746366 EnableStatusOfRamp5 4458;
BA_ "SAEDocument" SG_ 2566746366 EnableStatusOfRamp5 "J1939-71";
BA_ "SigType" SG_ 2566746366 EnableStatusOfRamp4 5;
BA_ "SPN" SG_ 2566746366 EnableStatusOfRamp4 4455;
BA_ "SAEDocument" SG_ 2566746366 EnableStatusOfRamp4 "J1939-71";
BA_ "SigType" SG_ 2566746366 MovementStatusOfRamp3 5;
BA_ "SPN" SG_ 2566746366 MovementStatusOfRamp3 3818;
BA_ "SAEDocument" SG_ 2566746366 MovementStatusOfRamp3 "J1939-71";
BA_ "SigType" SG_ 2566746366 EnableStatusOfRamp3 5;
BA_ "SPN" SG_ 2566746366 EnableStatusOfRamp3 3817;
BA_ "SAEDocument" SG_ 2566746366 EnableStatusOfRamp3 "J1939-71";
BA_ "SigType" SG_ 2566746366 RetractStatusOfRamp3 5;
BA_ "SPN" SG_ 2566746366 RetractStatusOfRamp3 3816;
BA_ "SAEDocument" SG_ 2566746366 RetractStatusOfRamp3 "J1939-71";
BA_ "SigType" SG_ 2566746366 MovementStatusOfRamp2 5;
BA_ "SPN" SG_ 2566746366 MovementStatusOfRamp2 3815;
BA_ "SAEDocument" SG_ 2566746366 MovementStatusOfRamp2 "J1939-71";
BA_ "SigType" SG_ 2566746366 EnableStatusOfRamp2 5;
BA_ "SPN" SG_ 2566746366 EnableStatusOfRamp2 3814;
BA_ "SAEDocument" SG_ 2566746366 EnableStatusOfRamp2 "J1939-71";
BA_ "SigType" SG_ 2566746366 RetractStatusOfRamp2 5;
BA_ "SPN" SG_ 2566746366 RetractStatusOfRamp2 3813;
BA_ "SAEDocument" SG_ 2566746366 RetractStatusOfRamp2 "J1939-71";
BA_ "SigType" SG_ 2566746366 MovementStatusOfRamp1 5;
BA_ "SPN" SG_ 2566746366 MovementStatusOfRamp1 3812;
BA_ "SAEDocument" SG_ 2566746366 MovementStatusOfRamp1 "J1939-71";
BA_ "SigType" SG_ 2566746366 EnableStatusOfRamp1 5;
BA_ "SPN" SG_ 2566746366 EnableStatusOfRamp1 3811;
BA_ "SAEDocument" SG_ 2566746366 EnableStatusOfRamp1 "J1939-71";
BA_ "SigType" SG_ 2566746366 RetractStatusOfRamp1 5;
BA_ "SPN" SG_ 2566746366 RetractStatusOfRamp1 3810;
BA_ "SAEDocument" SG_ 2566746366 RetractStatusOfRamp1 "J1939-71";
BA_ "SPN" SG_ 2566750206 MaxCrankAttemptsPerStartAttempt 3670;
BA_ "SAEDocument" SG_ 2566750206 MaxCrankAttemptsPerStartAttempt "J1939-71";
BA_ "SigType" SG_ 2566755582 CommandedEngIntakeManifoldPress 1;
BA_ "SPN" SG_ 2566755582 CommandedEngIntakeManifoldPress 5312;
BA_ "SAEDocument" SG_ 2566755582 CommandedEngIntakeManifoldPress "J1939-71";
BA_ "SigType" SG_ 2566755582 EngCrnkcsBrtherOilSeparatorSpeed 1;
BA_ "SPN" SG_ 2566755582 EngCrnkcsBrtherOilSeparatorSpeed 5444;
BA_ "SAEDocument" SG_ 2566755582 EngCrnkcsBrtherOilSeparatorSpeed "J1939-71";
BA_ "SigType" SG_ 2566755582 EngExhstGsRcirculation1Valve2Pos 1;
BA_ "SPN" SG_ 2566755582 EngExhstGsRcirculation1Valve2Pos 3822;
BA_ "SAEDocument" SG_ 2566755582 EngExhstGsRcirculation1Valve2Pos "J1939-71";
BA_ "SigType" SG_ 2566755582 EngExhstGsRecirculation1ValvePos 1;
BA_ "SPN" SG_ 2566755582 EngExhstGsRecirculation1ValvePos 27;
BA_ "SAEDocument" SG_ 2566755582 EngExhstGsRecirculation1ValvePos "J1939-71";
BA_ "SigType" SG_ 2566746110 EngExhstGsRcrcltn1ClrIntkGsAbsPr 1;
BA_ "SPN" SG_ 2566746110 EngExhstGsRcrcltn1ClrIntkGsAbsPr 4751;
BA_ "SAEDocument" SG_ 2566746110 EngExhstGsRcrcltn1ClrIntkGsAbsPr "J1939-71";
BA_ "SigType" SG_ 2566746110 EngExhstGsRcrcltn1ClerIntakeTemp 1;
BA_ "SPN" SG_ 2566746110 EngExhstGsRcrcltn1ClerIntakeTemp 4750;
BA_ "SAEDocument" SG_ 2566746110 EngExhstGsRcrcltn1ClerIntakeTemp "J1939-71";
BA_ "SPN" SG_ 2566746110 EngExhstGsRcrcltn1ClerEfficiency 4752;
BA_ "SAEDocument" SG_ 2566746110 EngExhstGsRcrcltn1ClerEfficiency "J1939-71";
BA_ "SPN" SG_ 2566746110 EngExhstGsRcrculation1Valve2Ctrl 3821;
BA_ "SAEDocument" SG_ 2566746110 EngExhstGsRcrculation1Valve2Ctrl "J1939-71";
BA_ "SigType" SG_ 2566752510 EngIntkVlvActtionOilPressForCyl4 1;
BA_ "SPN" SG_ 2566752510 EngIntkVlvActtionOilPressForCyl4 3627;
BA_ "SAEDocument" SG_ 2566752510 EngIntkVlvActtionOilPressForCyl4 "J1939-71";
BA_ "SigType" SG_ 2566752510 EngIntkVlvActtionOilPressForCyl3 1;
BA_ "SPN" SG_ 2566752510 EngIntkVlvActtionOilPressForCyl3 3626;
BA_ "SAEDocument" SG_ 2566752510 EngIntkVlvActtionOilPressForCyl3 "J1939-71";
BA_ "SigType" SG_ 2566752510 EngIntkVlvActtionOilPressForCyl2 1;
BA_ "SPN" SG_ 2566752510 EngIntkVlvActtionOilPressForCyl2 3625;
BA_ "SAEDocument" SG_ 2566752510 EngIntkVlvActtionOilPressForCyl2 "J1939-71";
BA_ "SigType" SG_ 2566752510 EngIntkVlvActtionOilPressForCyl1 1;
BA_ "SPN" SG_ 2566752510 EngIntkVlvActtionOilPressForCyl1 3624;
BA_ "SAEDocument" SG_ 2566752510 EngIntkVlvActtionOilPressForCyl1 "J1939-71";
BA_ "SigType" SG_ 2566752254 EngIntkVlvActtionOilPressForCyl8 1;
BA_ "SPN" SG_ 2566752254 EngIntkVlvActtionOilPressForCyl8 3631;
BA_ "SAEDocument" SG_ 2566752254 EngIntkVlvActtionOilPressForCyl8 "J1939-71";
BA_ "SigType" SG_ 2566752254 EngIntkVlvActtionOilPressForCyl7 1;
BA_ "SPN" SG_ 2566752254 EngIntkVlvActtionOilPressForCyl7 3630;
BA_ "SAEDocument" SG_ 2566752254 EngIntkVlvActtionOilPressForCyl7 "J1939-71";
BA_ "SigType" SG_ 2566752254 EngIntkVlvActtionOilPressForCyl6 1;
BA_ "SPN" SG_ 2566752254 EngIntkVlvActtionOilPressForCyl6 3629;
BA_ "SAEDocument" SG_ 2566752254 EngIntkVlvActtionOilPressForCyl6 "J1939-71";
BA_ "SigType" SG_ 2566752254 EngIntkVlvActtionOilPressForCyl5 1;
BA_ "SPN" SG_ 2566752254 EngIntkVlvActtionOilPressForCyl5 3628;
BA_ "SAEDocument" SG_ 2566752254 EngIntkVlvActtionOilPressForCyl5 "J1939-71";
BA_ "SigType" SG_ 2566751998 EngIntkVlvActtonOilPressForCyl12 1;
BA_ "SPN" SG_ 2566751998 EngIntkVlvActtonOilPressForCyl12 3635;
BA_ "SAEDocument" SG_ 2566751998 EngIntkVlvActtonOilPressForCyl12 "J1939-71";
BA_ "SigType" SG_ 2566751998 EngIntkVlvActtonOilPressForCyl11 1;
BA_ "SPN" SG_ 2566751998 EngIntkVlvActtonOilPressForCyl11 3634;
BA_ "SAEDocument" SG_ 2566751998 EngIntkVlvActtonOilPressForCyl11 "J1939-71";
BA_ "SigType" SG_ 2566751998 EngIntkVlvActtonOilPressForCyl10 1;
BA_ "SPN" SG_ 2566751998 EngIntkVlvActtonOilPressForCyl10 3633;
BA_ "SAEDocument" SG_ 2566751998 EngIntkVlvActtonOilPressForCyl10 "J1939-71";
BA_ "SigType" SG_ 2566751998 EngIntkVlvActtionOilPressForCyl9 1;
BA_ "SPN" SG_ 2566751998 EngIntkVlvActtionOilPressForCyl9 3632;
BA_ "SAEDocument" SG_ 2566751998 EngIntkVlvActtionOilPressForCyl9 "J1939-71";
BA_ "SigType" SG_ 2566751742 EngIntkVlvActtonOilPressForCyl16 1;
BA_ "SPN" SG_ 2566751742 EngIntkVlvActtonOilPressForCyl16 3639;
BA_ "SAEDocument" SG_ 2566751742 EngIntkVlvActtonOilPressForCyl16 "J1939-71";
BA_ "SigType" SG_ 2566751742 EngIntkVlvActtonOilPressForCyl15 1;
BA_ "SPN" SG_ 2566751742 EngIntkVlvActtonOilPressForCyl15 3638;
BA_ "SAEDocument" SG_ 2566751742 EngIntkVlvActtonOilPressForCyl15 "J1939-71";
BA_ "SigType" SG_ 2566751742 EngIntkVlvActtonOilPressForCyl14 1;
BA_ "SPN" SG_ 2566751742 EngIntkVlvActtonOilPressForCyl14 3637;
BA_ "SAEDocument" SG_ 2566751742 EngIntkVlvActtonOilPressForCyl14 "J1939-71";
BA_ "SigType" SG_ 2566751742 EngIntkVlvActtonOilPressForCyl13 1;
BA_ "SPN" SG_ 2566751742 EngIntkVlvActtonOilPressForCyl13 3636;
BA_ "SAEDocument" SG_ 2566751742 EngIntkVlvActtonOilPressForCyl13 "J1939-71";
BA_ "SigType" SG_ 2566751486 EngIntkVlvActtonOilPressForCyl20 1;
BA_ "SPN" SG_ 2566751486 EngIntkVlvActtonOilPressForCyl20 3643;
BA_ "SAEDocument" SG_ 2566751486 EngIntkVlvActtonOilPressForCyl20 "J1939-71";
BA_ "SigType" SG_ 2566751486 EngIntkVlvActtonOilPressForCyl19 1;
BA_ "SPN" SG_ 2566751486 EngIntkVlvActtonOilPressForCyl19 3642;
BA_ "SAEDocument" SG_ 2566751486 EngIntkVlvActtonOilPressForCyl19 "J1939-71";
BA_ "SigType" SG_ 2566751486 EngIntkVlvActtonOilPressForCyl18 1;
BA_ "SPN" SG_ 2566751486 EngIntkVlvActtonOilPressForCyl18 3641;
BA_ "SAEDocument" SG_ 2566751486 EngIntkVlvActtonOilPressForCyl18 "J1939-71";
BA_ "SigType" SG_ 2566751486 EngIntkVlvActtonOilPressForCyl17 1;
BA_ "SPN" SG_ 2566751486 EngIntkVlvActtonOilPressForCyl17 3640;
BA_ "SAEDocument" SG_ 2566751486 EngIntkVlvActtonOilPressForCyl17 "J1939-71";
BA_ "SigType" SG_ 2499641854 EGR1CoolerBypassActuatorPostion 1;
BA_ "SPN" SG_ 2499641854 EGR1CoolerBypassActuatorPostion 3672;
BA_ "SAEDocument" SG_ 2499641854 EGR1CoolerBypassActuatorPostion "J1939-71";
BA_ "SigType" SG_ 2566748158 EngSparkPlug4 1;
BA_ "SPN" SG_ 2566748158 EngSparkPlug4 1297;
BA_ "SAEDocument" SG_ 2566748158 EngSparkPlug4 "J1939-71";
BA_ "SigType" SG_ 2566748158 EngSparkPlug3 1;
BA_ "SPN" SG_ 2566748158 EngSparkPlug3 1296;
BA_ "SAEDocument" SG_ 2566748158 EngSparkPlug3 "J1939-71";
BA_ "SigType" SG_ 2566748158 EngSparkPlug2 1;
BA_ "SPN" SG_ 2566748158 EngSparkPlug2 1295;
BA_ "SAEDocument" SG_ 2566748158 EngSparkPlug2 "J1939-71";
BA_ "SigType" SG_ 2566748158 EngSparkPlug1 1;
BA_ "SPN" SG_ 2566748158 EngSparkPlug1 1294;
BA_ "SAEDocument" SG_ 2566748158 EngSparkPlug1 "J1939-71";
BA_ "SigType" SG_ 2566747902 EngSparkPlug8 1;
BA_ "SPN" SG_ 2566747902 EngSparkPlug8 1301;
BA_ "SAEDocument" SG_ 2566747902 EngSparkPlug8 "J1939-71";
BA_ "SigType" SG_ 2566747902 EngSparkPlug7 1;
BA_ "SPN" SG_ 2566747902 EngSparkPlug7 1300;
BA_ "SAEDocument" SG_ 2566747902 EngSparkPlug7 "J1939-71";
BA_ "SigType" SG_ 2566747902 EngSparkPlug6 1;
BA_ "SPN" SG_ 2566747902 EngSparkPlug6 1299;
BA_ "SAEDocument" SG_ 2566747902 EngSparkPlug6 "J1939-71";
BA_ "SigType" SG_ 2566747902 EngSparkPlug5 1;
BA_ "SPN" SG_ 2566747902 EngSparkPlug5 1298;
BA_ "SAEDocument" SG_ 2566747902 EngSparkPlug5 "J1939-71";
BA_ "SigType" SG_ 2566747646 EngSparkPlug12 1;
BA_ "SPN" SG_ 2566747646 EngSparkPlug12 1305;
BA_ "SAEDocument" SG_ 2566747646 EngSparkPlug12 "J1939-71";
BA_ "SigType" SG_ 2566747646 EngSparkPlug11 1;
BA_ "SPN" SG_ 2566747646 EngSparkPlug11 1304;
BA_ "SAEDocument" SG_ 2566747646 EngSparkPlug11 "J1939-71";
BA_ "SigType" SG_ 2566747646 EngSparkPlug10 1;
BA_ "SPN" SG_ 2566747646 EngSparkPlug10 1303;
BA_ "SAEDocument" SG_ 2566747646 EngSparkPlug10 "J1939-71";
BA_ "SigType" SG_ 2566747646 EngSparkPlug9 1;
BA_ "SPN" SG_ 2566747646 EngSparkPlug9 1302;
BA_ "SAEDocument" SG_ 2566747646 EngSparkPlug9 "J1939-71";
BA_ "SigType" SG_ 2566747390 EngSparkPlug16 1;
BA_ "SPN" SG_ 2566747390 EngSparkPlug16 1309;
BA_ "SAEDocument" SG_ 2566747390 EngSparkPlug16 "J1939-71";
BA_ "SigType" SG_ 2566747390 EngSparkPlug15 1;
BA_ "SPN" SG_ 2566747390 EngSparkPlug15 1308;
BA_ "SAEDocument" SG_ 2566747390 EngSparkPlug15 "J1939-71";
BA_ "SigType" SG_ 2566747390 EngSparkPlug14 1;
BA_ "SPN" SG_ 2566747390 EngSparkPlug14 1307;
BA_ "SAEDocument" SG_ 2566747390 EngSparkPlug14 "J1939-71";
BA_ "SigType" SG_ 2566747390 EngSparkPlug13 1;
BA_ "SPN" SG_ 2566747390 EngSparkPlug13 1306;
BA_ "SAEDocument" SG_ 2566747390 EngSparkPlug13 "J1939-71";
BA_ "SigType" SG_ 2566747134 EngSparkPlug20 1;
BA_ "SPN" SG_ 2566747134 EngSparkPlug20 1313;
BA_ "SAEDocument" SG_ 2566747134 EngSparkPlug20 "J1939-71";
BA_ "SigType" SG_ 2566747134 EngSparkPlug19 1;
BA_ "SPN" SG_ 2566747134 EngSparkPlug19 1312;
BA_ "SAEDocument" SG_ 2566747134 EngSparkPlug19 "J1939-71";
BA_ "SigType" SG_ 2566747134 EngSparkPlug18 1;
BA_ "SPN" SG_ 2566747134 EngSparkPlug18 1311;
BA_ "SAEDocument" SG_ 2566747134 EngSparkPlug18 "J1939-71";
BA_ "SigType" SG_ 2566747134 EngSparkPlug17 1;
BA_ "SPN" SG_ 2566747134 EngSparkPlug17 1310;
BA_ "SAEDocument" SG_ 2566747134 EngSparkPlug17 "J1939-71";
BA_ "SigType" SG_ 2566746878 EngSparkPlug24 1;
BA_ "SPN" SG_ 2566746878 EngSparkPlug24 1317;
BA_ "SAEDocument" SG_ 2566746878 EngSparkPlug24 "J1939-71";
BA_ "SigType" SG_ 2566746878 EngSparkPlug23 1;
BA_ "SPN" SG_ 2566746878 EngSparkPlug23 1316;
BA_ "SAEDocument" SG_ 2566746878 EngSparkPlug23 "J1939-71";
BA_ "SigType" SG_ 2566746878 EngSparkPlug22 1;
BA_ "SPN" SG_ 2566746878 EngSparkPlug22 1315;
BA_ "SAEDocument" SG_ 2566746878 EngSparkPlug22 "J1939-71";
BA_ "SigType" SG_ 2566746878 EngSparkPlug21 1;
BA_ "SPN" SG_ 2566746878 EngSparkPlug21 1314;
BA_ "SAEDocument" SG_ 2566746878 EngSparkPlug21 "J1939-71";
BA_ "SigType" SG_ 2561277694 LaneDepartureWarningEnableCmd 5;
BA_ "SPN" SG_ 2561277694 LaneDepartureWarningEnableCmd 3564;
BA_ "SAEDocument" SG_ 2561277694 LaneDepartureWarningEnableCmd "J1939-71";
BA_ "SPN" SG_ 2633861886 J2012DTCOccurrenceCount 3622;
BA_ "SAEDocument" SG_ 2633861886 J2012DTCOccurrenceCount "J1939-71";
BA_ "SPN" SG_ 2633861886 J2012DTCStatus 3621;
BA_ "SAEDocument" SG_ 2633861886 J2012DTCStatus "J1939-71";
BA_ "SPN" SG_ 2633861886 J2012DTC 3620;
BA_ "SAEDocument" SG_ 2633861886 J2012DTC "J1939-71";
BA_ "SigType" SG_ 2633861886 NumberOfJ2012DTCs 1;
BA_ "SPN" SG_ 2633861886 NumberOfJ2012DTCs 3619;
BA_ "SAEDocument" SG_ 2633861886 NumberOfJ2012DTCs "J1939-71";
BA_ "SPN" SG_ 2565873150 MessageChecksum 3690;
BA_ "SAEDocument" SG_ 2565873150 MessageChecksum "J1939-71";
BA_ "SPN" SG_ 2565873150 MessageCounter 3689;
BA_ "SAEDocument" SG_ 2565873150 MessageCounter "J1939-71";
BA_ "SigType" SG_ 2565873150 SteerAngleSensorCalibrated 5;
BA_ "SPN" SG_ 2565873150 SteerAngleSensorCalibrated 3688;
BA_ "SAEDocument" SG_ 2565873150 SteerAngleSensorCalibrated "J1939-71";
BA_ "SigType" SG_ 2565873150 SteerAngleSensorActiveMode 5;
BA_ "SPN" SG_ 2565873150 SteerAngleSensorActiveMode 3687;
BA_ "SAEDocument" SG_ 2565873150 SteerAngleSensorActiveMode "J1939-71";
BA_ "SigType" SG_ 2565873150 SteerWheelAngleRange 1;
BA_ "SPN" SG_ 2565873150 SteerWheelAngleRange 3686;
BA_ "SAEDocument" SG_ 2565873150 SteerWheelAngleRange "J1939-71";
BA_ "SigType" SG_ 2565873150 SteerWheelAngleRangeCounterType 5;
BA_ "SPN" SG_ 2565873150 SteerWheelAngleRangeCounterType 3685;
BA_ "SAEDocument" SG_ 2565873150 SteerWheelAngleRangeCounterType "J1939-71";
BA_ "SPN" SG_ 2565873150 SteerWheelAngleRangeCounter 3684;
BA_ "SAEDocument" SG_ 2565873150 SteerWheelAngleRangeCounter "J1939-71";
BA_ "SigType" SG_ 2565873150 SteerWheelAngle 1;
BA_ "SPN" SG_ 2565873150 SteerWheelAngle 3683;
BA_ "SAEDocument" SG_ 2565873150 SteerWheelAngle "J1939-71";
BA_ "SigType" SG_ 2566745854 Aftrtrtmnt1SCRCtlystCnvrsnEffcnc 1;
BA_ "SPN" SG_ 2566745854 Aftrtrtmnt1SCRCtlystCnvrsnEffcnc 4364;
BA_ "SAEDocument" SG_ 2566745854 Aftrtrtmnt1SCRCtlystCnvrsnEffcnc "J1939-71";
BA_ "SPN" SG_ 2566745854 Aftrtrtmnt1SCRCmmnddCtlystRgntCn 3828;
BA_ "SAEDocument" SG_ 2566745854 Aftrtrtmnt1SCRCmmnddCtlystRgntCn "J1939-71";
BA_ "SigType" SG_ 2566745854 Aftrtrtmnt1SCRAvrgCtlystRgntCnsm 1;
BA_ "SPN" SG_ 2566745854 Aftrtrtmnt1SCRAvrgCtlystRgntCnsm 3826;
BA_ "SAEDocument" SG_ 2566745854 Aftrtrtmnt1SCRAvrgCtlystRgntCnsm "J1939-71";
BA_ "SigType" SG_ 2566745854 Aftrtrtmnt1DslExhstFldTnkLwLvlIn 1;
BA_ "SPN" SG_ 2566745854 Aftrtrtmnt1DslExhstFldTnkLwLvlIn 5463;
BA_ "SAEDocument" SG_ 2566745854 Aftrtrtmnt1DslExhstFldTnkLwLvlIn "J1939-71";
BA_ "SPN" SG_ 2566751230 TransferCaseStatus 3645;
BA_ "SAEDocument" SG_ 2566751230 TransferCaseStatus "J1939-71";
BA_ "SigType" SG_ 2566755838 TransOilLifeRemaining 1;
BA_ "SPN" SG_ 2566755838 TransOilLifeRemaining 4177;
BA_ "SAEDocument" SG_ 2566755838 TransOilLifeRemaining "J1939-71";
BA_ "SigType" SG_ 2566755838 TrnsTorqueConverterOilOutletTemp 1;
BA_ "SPN" SG_ 2566755838 TrnsTorqueConverterOilOutletTemp 3823;
BA_ "SAEDocument" SG_ 2566755838 TrnsTorqueConverterOilOutletTemp "J1939-71";
BA_ "SigType" SG_ 2566755838 TransOverheatIndicator 5;
BA_ "SPN" SG_ 2566755838 TransOverheatIndicator 5345;
BA_ "SAEDocument" SG_ 2566755838 TransOverheatIndicator "J1939-71";
BA_ "SigType" SG_ 2566755838 TransOilLevelSwitch 5;
BA_ "SPN" SG_ 2566755838 TransOilLevelSwitch 3533;
BA_ "SAEDocument" SG_ 2566755838 TransOilLevelSwitch "J1939-71";
BA_ "SigType" SG_ 2566755838 TransOilFilterRestrictionSwitch 5;
BA_ "SPN" SG_ 2566755838 TransOilFilterRestrictionSwitch 3359;
BA_ "SAEDocument" SG_ 2566755838 TransOilFilterRestrictionSwitch "J1939-71";
BA_ "SigType" SG_ 2566752766 VehicleRoll 1;
BA_ "SPN" SG_ 2566752766 VehicleRoll 3623;
BA_ "SAEDocument" SG_ 2566752766 VehicleRoll "J1939-71";
BA_ "SigType" SG_ 2633938942 TotalEngCruiseTime 1;
BA_ "SPN" SG_ 2633938942 TotalEngCruiseTime 1017;
BA_ "SAEDocument" SG_ 2633938942 TotalEngCruiseTime "J1939-71";
BA_ "SigType" SG_ 2633938942 TotalDriveAverageLoadFactor 1;
BA_ "SPN" SG_ 2633938942 TotalDriveAverageLoadFactor 1016;
BA_ "SAEDocument" SG_ 2633938942 TotalDriveAverageLoadFactor "J1939-71";
BA_ "SigType" SG_ 2633938942 TripDriveAverageLoadFactor 1;
BA_ "SPN" SG_ 2633938942 TripDriveAverageLoadFactor 1015;
BA_ "SAEDocument" SG_ 2633938942 TripDriveAverageLoadFactor "J1939-71";
BA_ "SigType" SG_ 2633938942 TripAverageEngSpeed 1;
BA_ "SPN" SG_ 2633938942 TripAverageEngSpeed 1014;
BA_ "SAEDocument" SG_ 2633938942 TripAverageEngSpeed "J1939-71";
BA_ "SigType" SG_ 2633938942 TripMaxEngSpeed 1;
BA_ "SPN" SG_ 2633938942 TripMaxEngSpeed 1013;
BA_ "SAEDocument" SG_ 2633938942 TripMaxEngSpeed "J1939-71";
BA_ "SigType" SG_ 2566799614 ImplementRearWorkLight 4;
BA_ "SPN" SG_ 2566799614 ImplementRearWorkLight 2394;
BA_ "SAEDocument" SG_ 2566799614 ImplementRearWorkLight "J1939-71";
BA_ "SigType" SG_ 2566799614 ImplementLeftForwardWorkLight 4;
BA_ "SPN" SG_ 2566799614 ImplementLeftForwardWorkLight 2400;
BA_ "SAEDocument" SG_ 2566799614 ImplementLeftForwardWorkLight "J1939-71";
BA_ "SigType" SG_ 2566799614 ImplementRightForwardWorkLight 4;
BA_ "SPN" SG_ 2566799614 ImplementRightForwardWorkLight 2402;
BA_ "SAEDocument" SG_ 2566799614 ImplementRightForwardWorkLight "J1939-71";
BA_ "SigType" SG_ 2566799614 ImplementLeftFacingWorkLight 4;
BA_ "SPN" SG_ 2566799614 ImplementLeftFacingWorkLight 2598;
BA_ "SAEDocument" SG_ 2566799614 ImplementLeftFacingWorkLight "J1939-71";
BA_ "SigType" SG_ 2566799614 ImplementRightFacingWorkLight 4;
BA_ "SPN" SG_ 2566799614 ImplementRightFacingWorkLight 2407;
BA_ "SAEDocument" SG_ 2566799614 ImplementRightFacingWorkLight "J1939-71";
BA_ "SigType" SG_ 2566799614 ImplementOEMOption1Light 4;
BA_ "SPN" SG_ 2566799614 ImplementOEMOption1Light 2396;
BA_ "SAEDocument" SG_ 2566799614 ImplementOEMOption1Light "J1939-71";
BA_ "SigType" SG_ 2566799614 ImplementOEMOption2Light 4;
BA_ "SPN" SG_ 2566799614 ImplementOEMOption2Light 2398;
BA_ "SAEDocument" SG_ 2566799614 ImplementOEMOption2Light "J1939-71";
BA_ "SigType" SG_ 2566799614 TrctorFrontHighMountedWorkLights 4;
BA_ "SPN" SG_ 2566799614 TrctorFrontHighMountedWorkLights 2356;
BA_ "SAEDocument" SG_ 2566799614 TrctorFrontHighMountedWorkLights "J1939-71";
BA_ "SigType" SG_ 2566799614 TractorFrontLowMountedWorkLights 4;
BA_ "SPN" SG_ 2566799614 TractorFrontLowMountedWorkLights 2354;
BA_ "SAEDocument" SG_ 2566799614 TractorFrontLowMountedWorkLights "J1939-71";
BA_ "SigType" SG_ 2566799614 TractorSideHighMountedWorkLights 4;
BA_ "SPN" SG_ 2566799614 TractorSideHighMountedWorkLights 2366;
BA_ "SAEDocument" SG_ 2566799614 TractorSideHighMountedWorkLights "J1939-71";
BA_ "SigType" SG_ 2566799614 TractorSideLowMountedWorkLights 4;
BA_ "SPN" SG_ 2566799614 TractorSideLowMountedWorkLights 2364;
BA_ "SAEDocument" SG_ 2566799614 TractorSideLowMountedWorkLights "J1939-71";
BA_ "SigType" SG_ 2566799614 TractorRearHighMountedWorkLights 4;
BA_ "SPN" SG_ 2566799614 TractorRearHighMountedWorkLights 2362;
BA_ "SAEDocument" SG_ 2566799614 TractorRearHighMountedWorkLights "J1939-71";
BA_ "SigType" SG_ 2566799614 TractorRearLowMountedWorkLights 4;
BA_ "SPN" SG_ 2566799614 TractorRearLowMountedWorkLights 2360;
BA_ "SAEDocument" SG_ 2566799614 TractorRearLowMountedWorkLights "J1939-71";
BA_ "SigType" SG_ 2566799614 TrctorUndersideMountedWorkLights 4;
BA_ "SPN" SG_ 2566799614 TrctorUndersideMountedWorkLights 2358;
BA_ "SAEDocument" SG_ 2566799614 TrctorUndersideMountedWorkLights "J1939-71";
BA_ "SigType" SG_ 2566799614 RearFogLights 4;
BA_ "SPN" SG_ 2566799614 RearFogLights 2390;
BA_ "SAEDocument" SG_ 2566799614 RearFogLights "J1939-71";
BA_ "SigType" SG_ 2566799614 TractorMarkerLight 4;
BA_ "SPN" SG_ 2566799614 TractorMarkerLight 2378;
BA_ "SAEDocument" SG_ 2566799614 TractorMarkerLight "J1939-71";
BA_ "SigType" SG_ 2566799614 ImplementMarkerLight 4;
BA_ "SPN" SG_ 2566799614 ImplementMarkerLight 2380;
BA_ "SAEDocument" SG_ 2566799614 ImplementMarkerLight "J1939-71";
BA_ "SigType" SG_ 2566799614 TractorClearanceLight 4;
BA_ "SPN" SG_ 2566799614 TractorClearanceLight 2382;
BA_ "SAEDocument" SG_ 2566799614 TractorClearanceLight "J1939-71";
BA_ "SigType" SG_ 2566799614 ImplementClearanceLight 4;
BA_ "SPN" SG_ 2566799614 ImplementClearanceLight 2384;
BA_ "SAEDocument" SG_ 2566799614 ImplementClearanceLight "J1939-71";
BA_ "SigType" SG_ 2566799614 LeftStopLight 4;
BA_ "SPN" SG_ 2566799614 LeftStopLight 2372;
BA_ "SAEDocument" SG_ 2566799614 LeftStopLight "J1939-71";
BA_ "SigType" SG_ 2566799614 RightStopLight 4;
BA_ "SPN" SG_ 2566799614 RightStopLight 2374;
BA_ "SAEDocument" SG_ 2566799614 RightStopLight "J1939-71";
BA_ "SigType" SG_ 2566799614 CenterStopLight 4;
BA_ "SPN" SG_ 2566799614 CenterStopLight 2376;
BA_ "SAEDocument" SG_ 2566799614 CenterStopLight "J1939-71";
BA_ "SigType" SG_ 2566799614 BackUpLightAndAlarmHorn 4;
BA_ "SPN" SG_ 2566799614 BackUpLightAndAlarmHorn 2392;
BA_ "SAEDocument" SG_ 2566799614 BackUpLightAndAlarmHorn "J1939-71";
BA_ "SigType" SG_ 2566799614 LeftTurnSignalLights 4;
BA_ "SPN" SG_ 2566799614 LeftTurnSignalLights 2368;
BA_ "SAEDocument" SG_ 2566799614 LeftTurnSignalLights "J1939-71";
BA_ "SigType" SG_ 2566799614 RightTurnSignalLights 4;
BA_ "SPN" SG_ 2566799614 RightTurnSignalLights 2370;
BA_ "SAEDocument" SG_ 2566799614 RightTurnSignalLights "J1939-71";
BA_ "SigType" SG_ 2566799614 RotatingBeaconLight 4;
BA_ "SPN" SG_ 2566799614 RotatingBeaconLight 2386;
BA_ "SAEDocument" SG_ 2566799614 RotatingBeaconLight "J1939-71";
BA_ "SigType" SG_ 2566799614 TractorFrontFogLights 4;
BA_ "SPN" SG_ 2566799614 TractorFrontFogLights 2388;
BA_ "SAEDocument" SG_ 2566799614 TractorFrontFogLights "J1939-71";
BA_ "SigType" SG_ 2566799614 HighBeamHeadLightData 4;
BA_ "SPN" SG_ 2566799614 HighBeamHeadLightData 2348;
BA_ "SAEDocument" SG_ 2566799614 HighBeamHeadLightData "J1939-71";
BA_ "SigType" SG_ 2566799614 LowBeamHeadLightData 4;
BA_ "SPN" SG_ 2566799614 LowBeamHeadLightData 2350;
BA_ "SAEDocument" SG_ 2566799614 LowBeamHeadLightData "J1939-71";
BA_ "SigType" SG_ 2566799614 AltBeamHeadLightData 4;
BA_ "SPN" SG_ 2566799614 AltBeamHeadLightData 2352;
BA_ "SAEDocument" SG_ 2566799614 AltBeamHeadLightData "J1939-71";
BA_ "SigType" SG_ 2566799614 RunningLight 4;
BA_ "SPN" SG_ 2566799614 RunningLight 2404;
BA_ "SAEDocument" SG_ 2566799614 RunningLight "J1939-71";
VAL_ 2566714110 EngFuelValve2OperationStatus 14 "Error" 6 "1101ReservedForFutureAssignment" 5 "UnCtrlledShutdownActive" 4 "CtrlledShutdownActive" 3 "DerateActive" 2 "AlarmHighSeverity" 1 "Alarm" 0 "Normal" ;
VAL_ 2566714110 EngFuelValve1OperationStatus 14 "Error" 6 "1101ReservedForFutureAssignment" 5 "UnCtrlledShutdownActive" 4 "CtrlledShutdownActive" 3 "DerateActive" 2 "AlarmHighSeverity" 1 "Alarm" 0 "Normal" ;
VAL_ 2566714110 EngThrottleValve2OperationStatus 14 "Error" 6 "1101ReservedForFutureAssignment" 5 "UnCtrlledShutdownActive" 4 "CtrlledShutdownActive" 3 "DerateActive" 2 "AlarmHighSeverity" 1 "Alarm" 0 "Normal" ;
VAL_ 2566714110 EngThrottleValve1OperationStatus 15 "Not available" 14 "Error" 6 "1101 Reserved for future assignment" 5 "Uncontrolled Shutdown Active actuator current is off so it is limp" 4 "Controlled Shutdown Active driving to the default position  usually this means closed" 3 "Derate Active torque output reduced due to environmental conditions" 2 "Alarm High Severity functional but transient performance may be reduced" 1 "Alarm fully operational but needs service" 0 "Normal" ;
VAL_ 2566714110 EngFuelValve2TempStatus 7 "Not available" 6 "Error" 5 "Not Defined" 4 "Low Most severe" 3 "Low Least severe" 2 "In Range" 1 "High Least severe" 0 "High most severe" ;
VAL_ 2566714110 EngFuelValve1TempStatus 7 "Not available" 6 "Error" 5 "Not Defined" 4 "Low Most severe" 3 "Low Least severe" 2 "In Range" 1 "High Least severe" 0 "High Most severe" ;
VAL_ 2566714110 EngThrottleValve2TempStatus 7 "Not available" 6 "Error" 5 "Not Defined" 4 "Low Most severe" 3 "Low Least severe" 2 "In Range" 1 "High Least severe" 0 "High Most severe" ;
VAL_ 2566714110 EngThrottleValve1TempStatus 7 "Not available" 6 "Error" 5 "Not Defined" 4 "Low Most severe" 3 "Low Least severe" 2 "In Range" 1 "High Least severe" 0 "High most severe" ;
VAL_ 2365400574 Jystick9GripXAxisDetentPosStatus 3 "Not Available" 2 "Error Indicator" 1 "In the Detent Position" 0 "Not in the Detent Position" ;
VAL_ 2365400574 Jystick9GripYAxisDetentPosStatus 3 "Not Available" 2 "Error Indicator" 1 "In the Detent Position" 0 "Not in the Detent Position" ;
VAL_ 2365400574 Jystick9ThetaAxisDetentPosStatus 3 "Not Available" 2 "Error Indicator" 1 "In the Detent Position" 0 "Not in the Detent Position" ;
VAL_ 2365400574 Jystck9ThtAxsClckwsPstvPosStatus 3 "Not Available" 2 "Error Indicator" 1 "On positive side of Neutral" 0 "Not on Positive side of Neutral" ;
VAL_ 2365400574 Jystck9ThtAxsCntrClckwsNgtvPsStt 3 "Not Available" 2 "Error Indicator" 1 "On negative side of Neutral" 0 "Not on negative side of Neutral" ;
VAL_ 2365400574 Jystck9ThetaAxisNeutralPosStatus 3 "Not Available" 2 "Error Indicator" 1 "In Neutral Position" 0 "Not in Neutral Position" ;
VAL_ 2365400574 Jystck9GrpYAxsLvrFrwrdPstvPsStts 3 "Not Available" 2 "Error Indicator" 1 "On positive side of Neutral" 0 "Not on Positive side of Neutral" ;
VAL_ 2365400574 Jystck9GrpYAxsLvrBckNgtvPsStatus 3 "Not Available" 2 "Error Indicator" 1 "On negative side of Neutral" 0 "Not on negative side of Neutral" ;
VAL_ 2365400574 Jystck9GripYAxisNeutralPosStatus 3 "Not Available" 2 "Error Indicator" 1 "In Neutral Position" 0 "Not in Neutral Position" ;
VAL_ 2365400574 Jystck9GrpXAxsLvrRghtPstvPsSttus 3 "Not Available" 2 "Error Indicator" 1 "On positive side of Neutral" 0 "Not on Positive side of Neutral" ;
VAL_ 2365400574 Jystck9GrpXAxsLvrLftNgtvPsStatus 3 "Not Available" 2 "Error Indicator" 1 "On negative side of Neutral" 0 "Not on negative side of Neutral" ;
VAL_ 2365400574 Jystck9GripXAxisNeutralPosStatus 3 "Not Available" 2 "Error Indicator" 1 "In Neutral Position" 0 "Not in Neutral Position" ;
VAL_ 2365401086 Jystick8GripXAxisDetentPosStatus 3 "Not Available" 2 "Error Indicator" 1 "In the Detent Position" 0 "Not in the Detent Position" ;
VAL_ 2365401086 Jystick8GripYAxisDetentPosStatus 3 "Not Available" 2 "Error Indicator" 1 "In the Detent Position" 0 "Not in the Detent Position" ;
VAL_ 2365401086 Jystick8ThetaAxisDetentPosStatus 3 "Not Available" 2 "Error Indicator" 1 "In the Detent Position" 0 "Not in the Detent Position" ;
VAL_ 2365401086 Jystck8ThtAxsClckwsPstvPosStatus 3 "Not Available" 2 "Error Indicator" 1 "On positive side of Neutral" 0 "Not on Positive side of Neutral" ;
VAL_ 2365401086 Jystck8ThtAxsCntrClckwsNgtvPsStt 3 "Not Available" 2 "Error Indicator" 1 "On negative side of Neutral" 0 "Not on negative side of Neutral" ;
VAL_ 2365401086 Jystck8ThetaAxisNeutralPosStatus 3 "Not Available" 2 "Error Indicator" 1 "In Neutral Position" 0 "Not in Neutral Position" ;
VAL_ 2365401086 Jystck8GrpYAxsLvrFrwrdPstvPsStts 3 "Not Available" 2 "Error Indicator" 1 "On positive side of Neutral" 0 "Not on Positive side of Neutral" ;
VAL_ 2365401086 Jystck8GrpYAxsLvrBckNgtvPsStatus 3 "Not Available" 2 "Error Indicator" 1 "On negative side of Neutral" 0 "Not on negative side of Neutral" ;
VAL_ 2365401086 Jystck8GripYAxisNeutralPosStatus 3 "Not Available" 2 "Error Indicator" 1 "In Neutral Position" 0 "Not in Neutral Position" ;
VAL_ 2365401086 Jystck8GrpXAxsLvrRghtPstvPsSttus 3 "Not Available" 2 "Error Indicator" 1 "On positive side of Neutral" 0 "Not on Positive side of Neutral" ;
VAL_ 2365401086 Jystck8GrpXAxsLvrLftNgtvPsStatus 3 "Not Available" 2 "Error Indicator" 1 "On negative side of Neutral" 0 "Not on negative side of Neutral" ;
VAL_ 2365401086 Jystck8GripXAxisNeutralPosStatus 3 "Not Available" 2 "Error Indicator" 1 "In Neutral Position" 0 "Not in Neutral Position" ;
VAL_ 2365401598 Jystick7GripXAxisDetentPosStatus 3 "Not Available" 2 "Error Indicator" 1 "In the Detent Position" 0 "Not in the Detent Position" ;
VAL_ 2365401598 Jystick7GripYAxisDetentPosStatus 3 "Not Available" 2 "Error Indicator" 1 "In the Detent Position" 0 "Not in the Detent Position" ;
VAL_ 2365401598 Jystick7ThetaAxisDetentPosStatus 3 "Not Available" 2 "Error Indicator" 1 "In the Detent Position" 0 "Not in the Detent Position" ;
VAL_ 2365401598 Jystck7ThtAxsClckwsPstvPosStatus 3 "Not Available" 2 "Error Indicator" 1 "On positive side of Neutral" 0 "Not on Positive side of Neutral" ;
VAL_ 2365401598 Jystck7ThtAxsCntrClckwsNgtvPsStt 3 "Not Available" 2 "Error Indicator" 1 "On negative side of Neutral" 0 "Not on negative side of Neutral" ;
VAL_ 2365401598 Jystck7ThetaAxisNeutralPosStatus 3 "Not Available" 2 "Error Indicator" 1 "In Neutral Position" 0 "Not in Neutral Position" ;
VAL_ 2365401598 Jystck7GrpYAxsLvrFrwrdPstvPsStts 3 "Not Available" 2 "Error Indicator" 1 "On positive side of Neutral" 0 "Not on Positive side of Neutral" ;
VAL_ 2365401598 Jystck7GrpYAxsLvrBckNgtvPsStatus 3 "Not Available" 2 "Error Indicator" 1 "On negative side of Neutral" 0 "Not on negative side of Neutral" ;
VAL_ 2365401598 Jystck7GripYAxisNeutralPosStatus 3 "Not Available" 2 "Error Indicator" 1 "In Neutral Position" 0 "Not in Neutral Position" ;
VAL_ 2365401598 Jystck7GrpXAxsLvrRghtPstvPsSttus 3 "Not Available" 2 "Error Indicator" 1 "On positive side of Neutral" 0 "Not on Positive side of Neutral" ;
VAL_ 2365401598 Jystck7GrpXAxsLvrLftNgtvPsStatus 3 "Not Available" 2 "Error Indicator" 1 "On negative side of Neutral" 0 "Not on negative side of Neutral" ;
VAL_ 2365401598 Jystck7GripXAxisNeutralPosStatus 3 "Not Available" 2 "Error Indicator" 1 "In Neutral Position" 0 "Not in Neutral Position" ;
VAL_ 2365402110 Jystick6GripXAxisDetentPosStatus 3 "Not Available" 2 "Error Indicator" 1 "In the Detent Position" 0 "Not in the Detent Position" ;
VAL_ 2365402110 Jystick6GripYAxisDetentPosStatus 3 "Not Available" 2 "Error Indicator" 1 "In the Detent Position" 0 "Not in the Detent Position" ;
VAL_ 2365402110 Jystick6ThetaAxisDetentPosStatus 3 "Not Available" 2 "Error Indicator" 1 "In the Detent Position" 0 "Not in the Detent Position" ;
VAL_ 2365402110 Jystck6ThtAxsClckwsPstvPosStatus 3 "Not Available" 2 "Error Indicator" 1 "On positive side of Neutral" 0 "Not on Positive side of Neutral" ;
VAL_ 2365402110 Jystck6ThtAxsCntrClckwsNgtvPsStt 3 "Not Available" 2 "Error Indicator" 1 "On negative side of Neutral" 0 "Not on negative side of Neutral" ;
VAL_ 2365402110 Jystck6ThetaAxisNeutralPosStatus 3 "Not Available" 2 "Error Indicator" 1 "In Neutral Position" 0 "Not in Neutral Position" ;
VAL_ 2365402110 Jystck6GrpYAxsLvrFrwrdPstvPsStts 3 "Not Available" 2 "Error Indicator" 1 "On positive side of Neutral" 0 "Not on Positive side of Neutral" ;
VAL_ 2365402110 Jystck6GrpYAxsLvrBckNgtvPsStatus 3 "Not Available" 2 "Error Indicator" 1 "On negative side of Neutral" 0 "Not on negative side of Neutral" ;
VAL_ 2365402110 Jystck6GripYAxisNeutralPosStatus 3 "Not Available" 2 "Error Indicator" 1 "In Neutral Position" 0 "Not in Neutral Position" ;
VAL_ 2365402110 Jystck6GrpXAxsLvrRghtPstvPsSttus 3 "Not Available" 2 "Error Indicator" 1 "On positive side of Neutral" 0 "Not on Positive side of Neutral" ;
VAL_ 2365402110 Jystck6GrpXAxsLvrLftNgtvPsStatus 3 "Not Available" 2 "Error Indicator" 1 "On negative side of Neutral" 0 "Not on negative side of Neutral" ;
VAL_ 2365402110 Jystck6GripXAxisNeutralPosStatus 3 "Not Available" 2 "Error Indicator" 1 "In Neutral Position" 0 "Not in Neutral Position" ;
VAL_ 2365402622 Jystick5GripXAxisDetentPosStatus 3 "Not Available" 2 "Error Indicator" 1 "In the Detent Position" 0 "Not in the Detent Position" ;
VAL_ 2365402622 Jystick5GripYAxisDetentPosStatus 3 "Not Available" 2 "Error Indicator" 1 "In the Detent Position" 0 "Not in the Detent Position" ;
VAL_ 2365402622 Jystick5ThetaAxisDetentPosStatus 3 "Not Available" 2 "Error Indicator" 1 "In the Detent Position" 0 "Not in the Detent Position" ;
VAL_ 2365402622 Jystck5ThtAxsClckwsPstvPosStatus 3 "Not Available" 2 "Error Indicator" 1 "On positive side of Neutral" 0 "Not on Positive side of Neutral" ;
VAL_ 2365402622 Jystck5ThtAxsCntrClckwsNgtvPsStt 3 "Not Available" 2 "Error Indicator" 1 "On negative side of Neutral" 0 "Not on negative side of Neutral" ;
VAL_ 2365402622 Jystck5ThetaAxisNeutralPosStatus 3 "Not Available" 2 "Error Indicator" 1 "In Neutral Position" 0 "Not in Neutral Position" ;
VAL_ 2365402622 Jystck5GrpYAxsLvrFrwrdPstvPsStts 3 "Not Available" 2 "Error Indicator" 1 "On positive side of Neutral" 0 "Not on Positive side of Neutral" ;
VAL_ 2365402622 Jystck5GrpYAxsLvrBckNgtvPsStatus 3 "Not Available" 2 "Error Indicator" 1 "On negative side of Neutral" 0 "Not on negative side of Neutral" ;
VAL_ 2365402622 Jystck5GripYAxisNeutralPosStatus 3 "Not Available" 2 "Error Indicator" 1 "In Neutral Position" 0 "Not in Neutral Position" ;
VAL_ 2365402622 Jystck5GrpXAxsLvrRghtPstvPsSttus 3 "Not Available" 2 "Error Indicator" 1 "On positive side of Neutral" 0 "Not on Positive side of Neutral" ;
VAL_ 2365402622 Jystck5GrpXAxsLvrLftNgtvPsStatus 3 "Not Available" 2 "Error Indicator" 1 "On negative side of Neutral" 0 "Not on negative side of Neutral" ;
VAL_ 2365402622 Jystck5GripXAxisNeutralPosStatus 3 "Not Available" 2 "Error Indicator" 1 "In Neutral Position" 0 "Not in Neutral Position" ;
VAL_ 2365403134 Jystick4GripXAxisDetentPosStatus 3 "Not Available" 2 "Error Indicator" 1 "In the Detent Position" 0 "Not in the Detent Position" ;
VAL_ 2365403134 Jystick4GripYAxisDetentPosStatus 3 "Not Available" 2 "Error Indicator" 1 "In the Detent Position" 0 "Not in the Detent Position" ;
VAL_ 2365403134 Jystick4ThetaAxisDetentPosStatus 3 "Not Available" 2 "Error Indicator" 1 "In the Detent Position" 0 "Not in the Detent Position" ;
VAL_ 2365403134 Jystck4ThtAxsClckwsPstvPosStatus 3 "Not Available" 2 "Error Indicator" 1 "On positive side of Neutral" 0 "Not on Positive side of Neutral" ;
VAL_ 2365403134 Jystck4ThtAxsCntrClckwsNgtvPsStt 3 "Not Available" 2 "Error Indicator" 1 "On negative side of Neutral" 0 "Not on negative side of Neutral" ;
VAL_ 2365403134 Jystck4ThetaAxisNeutralPosStatus 3 "Not Available" 2 "Error Indicator" 1 "In Neutral Position" 0 "Not in Neutral Position" ;
VAL_ 2365403134 Jystck4GrpYAxsLvrFrwrdPstvPsStts 3 "Not Available" 2 "Error Indicator" 1 "On positive side of Neutral" 0 "Not on Positive side of Neutral" ;
VAL_ 2365403134 Jystck4GrpYAxsLvrBckNgtvPsStatus 3 "Not Available" 2 "Error Indicator" 1 "On negative side of Neutral" 0 "Not on negative side of Neutral" ;
VAL_ 2365403134 Jystck4GripYAxisNeutralPosStatus 3 "Not Available" 2 "Error Indicator" 1 "In Neutral Position" 0 "Not in Neutral Position" ;
VAL_ 2365403134 Jystck4GrpXAxsLvrRghtPstvPsSttus 3 "Not Available" 2 "Error Indicator" 1 "On positive side of Neutral" 0 "Not on Positive side of Neutral" ;
VAL_ 2365403134 Jystck4GrpXAxsLvrLftNgtvPsStatus 3 "Not Available" 2 "Error Indicator" 1 "On negative side of Neutral" 0 "Not on negative side of Neutral" ;
VAL_ 2365403134 Jystck4GripXAxisNeutralPosStatus 3 "Not Available" 2 "Error Indicator" 1 "In Neutral Position" 0 "Not in Neutral Position" ;
VAL_ 2365400062 Jystck10GripXAxisDetentPosStatus 3 "Not Available" 2 "Error Indicator" 1 "In the Detent Position" 0 "Not in the Detent Position" ;
VAL_ 2365400062 Jystck10GripYAxisDetentPosStatus 3 "Not Available" 2 "Error Indicator" 1 "In the Detent Position" 0 "Not in the Detent Position" ;
VAL_ 2365400062 Jystck10ThetaAxisDetentPosStatus 3 "Not Available" 2 "Error Indicator" 1 "In the Detent Position" 0 "Not in the Detent Position" ;
VAL_ 2365400062 Jystck10ThtAxsClckwsPstvPsStatus 3 "Not Available" 2 "Error Indicator" 1 "On positive side of Neutral" 0 "Not on Positive side of Neutral" ;
VAL_ 2365400062 Jystck10ThtAxsCntrClckwsNgtvPsSt 3 "Not Available" 2 "Error Indicator" 1 "On negative side of Neutral" 0 "Not on negative side of Neutral" ;
VAL_ 2365400062 Jystck10ThtaAxisNeutralPosStatus 3 "Not Available" 2 "Error Indicator" 1 "In Neutral Position" 0 "Not in Neutral Position" ;
VAL_ 2365400062 Jystck10GrpYAxsLvrFrwrdPstvPsStt 3 "Not Available" 2 "Error Indicator" 1 "On positive side of Neutral" 0 "Not on Positive side of Neutral" ;
VAL_ 2365400062 Jystck10GrpYAxsLvrBckNgtvPsSttus 3 "Not Available" 2 "Error Indicator" 1 "On negative side of Neutral" 0 "Not on negative side of Neutral" ;
VAL_ 2365400062 Jystck10GrpYAxisNeutralPosStatus 3 "Not Available" 2 "Error Indicator" 1 "In Neutral Position" 0 "Not in Neutral Position" ;
VAL_ 2365400062 Jystck10GrpXAxsLvrRghtPstvPsStts 3 "Not Available" 2 "Error Indicator" 1 "On positive side of Neutral" 0 "Not on Positive side of Neutral" ;
VAL_ 2365400062 Jystck10GrpXAxsLvrLftNgtvPsSttus 3 "Not Available" 2 "Error Indicator" 1 "On negative side of Neutral" 0 "Not on negative side of Neutral" ;
VAL_ 2365400062 Jystck10GrpXAxisNeutralPosStatus 3 "Not Available" 2 "Error Indicator" 1 "In Neutral Position" 0 "Not in Neutral Position" ;
VAL_ 2566749438 DslPrtcltFltrActvRgnrtnFrcdSttus 5 "Reserved for SAE Assignment" 4 "Reserved for SAE Assignment" 7 "not available" 6 "Reserved for SAE Assignment" 2 "Active  Forced by Service Tool" 3 "Reserved for SAE Assignment" 1 "Active  Forced by Switch See SPN 3696" 0 "Not Active" ;
VAL_ 2566749438 ExhaustSystemHighTempLampCmd 7 "not available" 6 "reserved for SAE assignment" 1 "On  solid" 0 "Off" 5 "reserved for SAE assignment" 4 "reserved for SAE assignment" 3 "reserved for SAE assignment" 2 "reserved for SAE assignment" ;
VAL_ 2566749438 DslPrtcltFltrAtmtcActvRgnrtnIntt 3 "not available" 2 "reserved for SAE assignment" 1 "enabled" 0 "not enabled" ;
VAL_ 2566749438 DslPrtcltFltrActvRgnrtnInhbtdDTV 3 "notAvailable" 2 "reservedForSAEAssignment" 1 "inhibited" 0 "notInhibited" ;
VAL_ 2566749438 DslPrtcltFltrActvRgnrtnInhbtdDTE 3 "notAvailable" 2 "reservedForSAEAssignment" 1 "inhibited" 0 "notInhibited" ;
VAL_ 2566749438 DslPrtcltFltrActvRgnrtnInhb_0000 3 "notAvailable" 2 "reservedForSAEAssignment" 1 "inhibited" 0 "notInhibited" ;
VAL_ 2566749438 DslPrtcltFltrActvRgnrtnInhbtdDTT 3 "not available" 2 "reserved for SAE assignment" 1 "inhibited" 0 "not inhibited" ;
VAL_ 2566749438 DslPrtcltFltrActvRgnrtnInhbtdDTS 3 "not available" 2 "reserved for SAE assignment" 1 "inhibited" 0 "not inhibited" ;
VAL_ 2566749438 DslPrtcltFltrActvRgnrtnInhbtdDTL 3 "not available" 2 "reserved for SAE assignment" 1 "inhibited" 0 "not inhibited" ;
VAL_ 2566749438 DslPrtcltFltrActvRgnrtnInhb_0001 3 "notAvailable" 2 "reservedForSAEAssignment" 1 "inhibited" 0 "notInhibited" ;
VAL_ 2566749438 DslPrtcltFltrActvRgnrtnInhb_0002 3 "notAvailable" 2 "reservedForSAEAssignment" 1 "inhibited" 0 "notInhibited" ;
VAL_ 2566749438 DslPrtcltFltrActvRgnrtnInhbtdDTO 3 "notAvailable" 2 "reservedForSAEAssignment" 1 "inhibited" 0 "notInhibited" ;
VAL_ 2566749438 DslPrtcltFltrActvRgnrtnInhbtdDTA 3 "not available" 2 "reserved for SAE assignment" 1 "inhibited" 0 "not inhibited" ;
VAL_ 2566749438 DslPrtcltFltrActvRgnrtnInhbtdDTP 3 "not available" 2 "reserved for SAE assignment" 1 "inhibited" 0 "not inhibited" ;
VAL_ 2566749438 DslPrtcltFltrActvRgnrtnInhbtdDTC 3 "not available" 2 "reserved for SAE assignment" 1 "inhibited" 0 "not inhibited" ;
VAL_ 2566749438 DslPrtcltFltrActvRgnrtnInhbtdDTI 3 "not available" 2 "reserved for SAE assignment" 1 "inhibited" 0 "not inhibited" ;
VAL_ 2566749438 DslPrtcltFltrActvRgnrtnInhbtdStt 3 "not available" 2 "reserved for SAE assignment" 1 "inhibited" 0 "not inhibited" ;
VAL_ 2566749438 DieselParticulateFilterStatus 7 "not available" 6 "reserved for SAE assignment" 3 "Regeneration needed  highest level" 2 "Regeneration needed  moderate level" 1 "Regeneration needed  lowest level" 0 "Regeneration not needed" 5 "reserved for SAE assignment" 4 "reserved for SAE assignment" ;
VAL_ 2566749438 DslPrtcltFltrActvRgnrationStatus 3 "not available" 2 "regeneration needed  automatically initiated active regeneration imminent" 1 "active" 0 "not active" ;
VAL_ 2566749438 DslPrtcltFltrPssvRgnrationStatus 3 "not available" 2 "reserved for SAE assignment" 1 "active" 0 "not active" ;
VAL_ 2566749438 DieselParticulateFilterLampCmd 7 "not available" 4 "On  fast blink 1 HZ" 6 "reserved for SAE assignment" 1 "On  solid" 0 "Off" 5 "reserved for SAE assignment" 3 "reserved for SAE assignment" 2 "reserved for SAE assignment" ;
VAL_ 2566718718 VehicleBatteryChargingLampData 3 "Not available" 2 "Error" 1 "Lamp activated On" 0 "Lamp deactivated Off" ;
VAL_ 2566718718 VehicleHVACRecirculationLampData 3 "Not available" 2 "Error" 1 "Lamp activated On" 0 "Lamp deactivated Off" ;
VAL_ 2566718718 VehicleAirPressLowLampData 3 "Not available" 2 "Error" 1 "Lamp activated On" 0 "Lamp deactivated Off" ;
VAL_ 2566718718 VehicleFuelLevelLowLampData 3 "Not available" 2 "Error" 1 "Lamp activated On" 0 "Lamp deactivated Off" ;
VAL_ 2566718718 VehicleBatteryVoltageLowLampData 3 "Not available" 2 "Error" 1 "Lamp activated On" 0 "Lamp deactivated Off" ;
VAL_ 2566718974 EngWaitToStartLampData 3 "Not available" 2 "Error" 1 "Lamp active" 0 "Lamp deactive" ;
VAL_ 2566718974 EngFuelFilterRestrictedLampData 3 "Not available" 2 "Error" 1 "Lamp activated On" 0 "Lamp deactivated Off" ;
VAL_ 2566718974 EngAirFilterRestrictionLampData 3 "Not available" 2 "Error" 1 "Lamp activated On" 0 "Lamp deactivated Off" ;
VAL_ 2566718974 EngIdleManagementActiveLampData 3 "Not available" 2 "Error" 1 "Lamp activated On" 0 "Lamp deactivated Off" ;
VAL_ 2566718974 EngCoolantLevelLowLampData 3 "Not available" 2 "Error" 1 "Lamp activated On" 0 "Lamp deactivated Off" ;
VAL_ 2566718974 EngCoolantTempHighLampData 3 "Not available" 2 "Error" 1 "Lamp activated On" 0 "Lamp deactivated Off" ;
VAL_ 2566718974 EngOilPressLowLampData 3 "Not available" 2 "Error" 1 "Lamp activated On" 0 "Lamp deactivated Off" ;
VAL_ 2566718974 CmprssnBrkEnblSwtchIndctrLmpData 3 "Not available" 2 "Error" 1 "Lamp activated On" 0 "Lamp deactivated Off" ;
VAL_ 2566718974 EngBrakeActiveLampData 3 "Not available" 2 "Error" 1 "Lamp activated On" 0 "Lamp deactivated Off" ;
VAL_ 2566718974 OBDMalfunctionIndicatorLampData 3 "Not available" 2 "Error" 1 "Lamp activated On" 0 "Lamp deactivated Off" ;
VAL_ 2566718974 EngRedStopLampData 3 "Not available" 2 "Error" 1 "Lamp activated On" 0 "Lamp deactivated Off" ;
VAL_ 2566718974 EngAmberWarningLampData 3 "Not available" 2 "Error" 1 "Lamp activated On" 0 "Lamp deactivated Off" ;
VAL_ 2566718974 EngProtectLampData 3 "Not available" 2 "Error" 1 "Lamp activated On" 0 "Lamp deactivated Off" ;
VAL_ 2566719230 VehicleBatteryChargingLampCmd 3 "Not available" 2 "Reserved" 1 "Lamp On" 0 "Lamp Off" ;
VAL_ 2566719230 VehicleHVACRecirculationLampCmd 3 "Not available" 2 "Reserved" 1 "Lamp On" 0 "Lamp Off" ;
VAL_ 2566719230 VehicleAirPressLowLampCmd 3 "Not available" 2 "Reserved" 1 "Lamp On" 0 "Lamp Off" ;
VAL_ 2566719230 VehicleFuelLevelLowLampCmd 3 "Not available" 2 "Reserved" 1 "Lamp On" 0 "Lamp Off" ;
VAL_ 2566719230 VehicleBatteryVoltageLowLampCmd 3 "Not available" 2 "Reserved" 1 "Lamp On" 0 "Lamp Off" ;
VAL_ 2560818942 FailureModeIdentifier1 31 "Not available" 19 "Received network data in error" 18 "Below normal (moderately severe)" 17 "Below normal (least severe)" 16 "Above normal (moderately severe)" 15 "Above normal (least severe)" 14 "Special intstructions" 13 "Out of calibration" 12 "Bad intelligent device" 11 "Root cause not known" 10 "Abnormal rate of change" 9 "Abnormal update rate" 8 "Abnormal frequency" 7 "Mechanical system not responding" 6 "Current above normal" 5 "Current below normal" 4 "Voltage below normal" 3 "Voltage above normal" 2 "Data erratic" 1 "Below normal (most severe)" 0 "Above normal (most severe)" ;
VAL_ 2561212158 TextDisplayInstructions 6 "Blink substring" 15 "Not applicable" 1 "Hold display  The presently displayed information should be retained" 0 "Clear display  The displayed information should be deleted or not displayed any more" 5 "Highlight substring" 4 "Overwrite substring  A portion of the presently displayed information is to be overwritten with the transmitted" 3 "Overwrite display  The presently displayed information is to be overwritten with the transmitted information" 2 "Append at end of display  The transmitted information should be displayed at the end of the presently displayed" ;
VAL_ 2566746366 RetractStatusOfRamp5 2 "error" 1 "ramp extended" 0 "ramp retracted" 3 "not available" ;
VAL_ 2566746366 RetractStatusOfRamp4 3 "not available" 2 "error" 1 "ramp extended" 0 "ramp retracted" ;
VAL_ 2566746366 MovementStatusOfRamp5 3 "not available" 2 "error" 1 "ramp being moved" 0 "ramp not being moved" ;
VAL_ 2566746366 MovementStatusOfRamp4 3 "not available" 2 "error" 1 "ramp being moved" 0 "ramp not being moved" ;
VAL_ 2566746366 EnableStatusOfRamp5 3 "not available" 2 "error" 1 "ramp enabled" 0 "ramp disabled" ;
VAL_ 2566746366 EnableStatusOfRamp4 3 "not available" 2 "error" 1 "ramp enabled" 0 "ramp disabled" ;
VAL_ 2566746366 MovementStatusOfRamp3 3 "not available" 2 "error" 1 "ramp being moved" 0 "ramp not being moved" ;
VAL_ 2566746366 EnableStatusOfRamp3 3 "not available" 2 "error" 1 "ramp enabled" 0 "ramp disabled" ;
VAL_ 2566746366 RetractStatusOfRamp3 3 "not available" 2 "error" 1 "ramp extended" 0 "ramp retracted" ;
VAL_ 2566746366 MovementStatusOfRamp2 3 "not available" 2 "error" 1 "ramp being moved" 0 "ramp not being moved" ;
VAL_ 2566746366 EnableStatusOfRamp2 3 "not available" 2 "error" 1 "ramp enabled" 0 "ramp disabled" ;
VAL_ 2566746366 RetractStatusOfRamp2 3 "not available" 2 "error" 1 "ramp extended" 0 "ramp retracted" ;
VAL_ 2566746366 MovementStatusOfRamp1 3 "not available" 2 "error" 1 "ramp being moved" 0 "ramp not being moved" ;
VAL_ 2566746366 EnableStatusOfRamp1 3 "not available" 2 "error" 1 "ramp enabled" 0 "ramp disabled" ;
VAL_ 2566746366 RetractStatusOfRamp1 3 "not available" 2 "error" 1 "ramp extended" 0 "ramp retracted" ;
VAL_ 2561277694 LaneDepartureWarningEnableCmd 3 "Dont care" 2 "Reserved" 1 "Enable Lane Departure Warning" 0 "Disable Lane Departure Warning" ;
VAL_ 2565873150 SteerAngleSensorCalibrated 3 "Not available" 2 "Reserved" 1 "SAS calibrated" 0 "SAS not calibrated" ;
VAL_ 2565873150 SteerAngleSensorActiveMode 3 "Not available" 2 "Reserved" 1 "Normal mode active" 0 "Programming mode active" ;
VAL_ 2565873150 SteerWheelAngleRangeCounterType 3 "signal not available" 2 "not defined" 1 "absolute number of counts" 0 "relative number of counts" ;
VAL_ 2566751230 TransferCaseStatus 7 "not available" 3 "2 wheel low or Off Highway Range" 0 "2 wheel high normal or On Highway Range" 6 "error" 5 "Transfer Case Shift in Progress or gear not confirmed" 4 "4 wheel low or Off Highway Range" 2 "neutral" 1 "4 wheel high normal or On Highway Range" ;
VAL_ 2566755838 TransOverheatIndicator 3 "Not available" 2 "Transmission Overheat Indicator is flashing" 1 "Transmission Overheat Indicator is on continuously" 0 "Transmission Overheat Indicator is off" ;
VAL_ 2566755838 TransOilLevelSwitch 3 "Not available" 2 "Error" 1 "Full or not empty" 0 "Empty" ;
VAL_ 2566755838 TransOilFilterRestrictionSwitch 3 "Not available" 2 "Error" 1 "Restriction exists on oil filter" 0 "No restriction" ;
VAL_ 2566799614 ImplementRearWorkLight 3 "Not Available" 2 "Fault Detected" 1 "Activated" 0 "Deactivated" ;
VAL_ 2566799614 ImplementLeftForwardWorkLight 3 "Not Available" 2 "Fault Detected" 1 "Activated" 0 "Deactivated" ;
VAL_ 2566799614 ImplementRightForwardWorkLight 3 "Not Available" 2 "Fault Detected" 1 "Activated" 0 "Deactivated" ;
VAL_ 2566799614 ImplementLeftFacingWorkLight 3 "Not Available" 2 "Fault Detected" 1 "Activate" 0 "Deactivate" ;
VAL_ 2566799614 ImplementRightFacingWorkLight 3 "Not Available" 2 "Fault Detected" 1 "Activated" 0 "Deactivated" ;
VAL_ 2566799614 ImplementOEMOption1Light 3 "Not Available" 2 "Fault Detected" 1 "Activated" 0 "Deactivated" ;
VAL_ 2566799614 ImplementOEMOption2Light 3 "Not Available" 2 "Fault Detected" 1 "Activated" 0 "Deactivated" ;
VAL_ 2566799614 TrctorFrontHighMountedWorkLights 3 "Not Available" 2 "Fault Detected" 1 "Activated" 0 "Deactivated" ;
VAL_ 2566799614 TractorFrontLowMountedWorkLights 3 "Not Available" 2 "Fault Detected" 1 "Activated" 0 "Deactivated" ;
VAL_ 2566799614 TractorSideHighMountedWorkLights 3 "Not Available" 2 "Fault Detected" 1 "Activated" 0 "Deactivated" ;
VAL_ 2566799614 TractorSideLowMountedWorkLights 3 "Not Available" 2 "Fault Detected" 1 "Activated" 0 "Deactivated" ;
VAL_ 2566799614 TractorRearHighMountedWorkLights 3 "Not Available" 2 "Fault Detected" 1 "Activated" 0 "Deactivated" ;
VAL_ 2566799614 TractorRearLowMountedWorkLights 3 "Not Available" 2 "Fault Detected" 1 "Activated" 0 "Deactivated" ;
VAL_ 2566799614 TrctorUndersideMountedWorkLights 3 "Not Available" 2 "Fault Detected" 1 "Activated" 0 "Deactivated" ;
VAL_ 2566799614 RearFogLights 3 "Not Available" 2 "Fault Detected" 1 "Activated" 0 "Deactivated" ;
VAL_ 2566799614 TractorMarkerLight 3 "Not Available" 2 "Fault Detected" 1 "Activated" 0 "Deactivated" ;
VAL_ 2566799614 ImplementMarkerLight 3 "Not Available" 2 "Fault Detected" 1 "Activated" 0 "Deactivated" ;
VAL_ 2566799614 TractorClearanceLight 3 "Not Available" 2 "Fault Detected" 1 "Activated" 0 "Deactivated" ;
VAL_ 2566799614 ImplementClearanceLight 3 "Not Available" 2 "Fault Detected" 1 "Activated" 0 "Deactivated" ;
VAL_ 2566799614 LeftStopLight 3 "Not Available" 2 "Fault Detected" 1 "Activated" 0 "Deactivated" ;
VAL_ 2566799614 RightStopLight 3 "Not Available" 2 "Fault Detected" 1 "Activated" 0 "Deactivated" ;
VAL_ 2566799614 CenterStopLight 3 "Not Available" 2 "Fault Detected" 1 "Activated" 0 "Deactivated" ;
VAL_ 2566799614 BackUpLightAndAlarmHorn 3 "Not Available" 2 "Fault Detected" 1 "Activated" 0 "Deactivated" ;
VAL_ 2566799614 LeftTurnSignalLights 3 "Not Available" 2 "Fault Detected" 1 "Activated" 0 "Deactivated" ;
VAL_ 2566799614 RightTurnSignalLights 3 "Not Available" 2 "Fault Detected" 1 "Activated" 0 "Deactivated" ;
VAL_ 2566799614 RotatingBeaconLight 3 "Not Available" 2 "Fault Detected" 1 "Activated" 0 "Deactivated" ;
VAL_ 2566799614 TractorFrontFogLights 3 "Not Available" 2 "Fault Detected" 1 "Activated" 0 "Deactivated" ;
VAL_ 2566799614 HighBeamHeadLightData 3 "Not Available" 2 "Fault Detected" 1 "Activated" 0 "Deactivated" ;
VAL_ 2566799614 LowBeamHeadLightData 3 "Not Available" 2 "Fault Detected" 1 "Activated" 0 "Deactivated" ;
VAL_ 2566799614 AltBeamHeadLightData 3 "Not Available" 2 "Fault Detected" 1 "Activated" 0 "Deactivated" ;
VAL_ 2566799614 RunningLight 3 "Not Available" 2 "Fault Detected" 1 "Activated" 0 "Deactivated" ;
